VERSION ""

NS_ :

BS_:

BU_: AGSM BCM BSM CDCM DASM DCSM DCTM DIAG_TEST DTCM ECM ECM2 IPC ORC RFHM TBM TCM
BO_ 346 IMPACT_INFO: 4 ORC
 SG_ CRC_II : 31|8@0+ (1,0) [0|255] "" BCM,TBM
 SG_ IMPACT_A : 4|1@0+ (1,0) [0|1] "" Vector__XXX
 SG_ IMPACT_B : 3|1@0+ (1,0) [0|1] "" TBM
 SG_ IMPACT_C : 2|1@0+ (1,0) [0|1] "" TBM
 SG_ IMPACT_D : 1|1@0+ (1,0) [0|1] "" TBM
 SG_ IMPACT_E : 0|1@0+ (1,0) [0|1] "" TBM
 SG_ IMPACT_F : 15|1@0+ (1,0) [0|1] "" TBM
 SG_ IMPACT_G : 14|1@0+ (1,0) [0|1] "" Vector__XXX
 SG_ IMPACT_H : 13|1@0+ (1,0) [0|1] "" TBM
 SG_ IMPACT_I : 12|1@0+ (1,0) [0|1] "" TBM
 SG_ IMPACT_K : 11|1@0+ (1,0) [0|1] "" Vector__XXX
 SG_ IMPACT_L : 10|1@0+ (1,0) [0|1] "" TBM
 SG_ IMPACT_M : 9|1@0+ (1,0) [0|1] "" Vector__XXX
 SG_ IMPACT_O : 8|1@0+ (1,0) [0|1] "" Vector__XXX
 SG_ IMPACTCommand : 6|1@0+ (1,0) [0|1] "" BCM,ECM
 SG_ IMPACTConfirm : 7|1@0+ (1,0) [0|1] "" BCM,ECM
 SG_ IMPACTFailSts : 5|1@0+ (1,0) [0|1] "" BCM
 SG_ MessageCounter_II : 19|4@0+ (1,0) [0|15] "" BCM

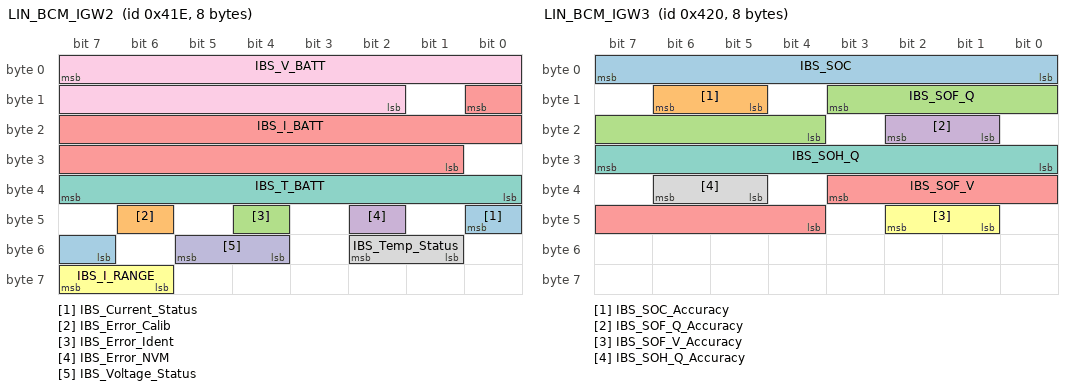
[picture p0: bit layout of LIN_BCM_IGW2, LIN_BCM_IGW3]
BO_ 1054 LIN_BCM_IGW2: 8 BCM
 SG_ IBS_Current_Status : 40|2@0+ (1,0) [0|3] "" ECM
 SG_ IBS_Error_Calib : 46|1@0+ (1,0) [0|1] "-" ECM
 SG_ IBS_Error_Ident : 44|1@0+ (1,0) [0|1] "-" ECM
 SG_ IBS_Error_NVM : 42|1@0+ (1,0) [0|1] "-" Vector__XXX
 SG_ IBS_I_BATT : 8|16@0+ (1,0) [0|65534] "" ECM
 SG_ IBS_I_RANGE : 63|2@0+ (1,0) [0|3] "" ECM
 SG_ IBS_T_BATT : 39|8@0+ (1,-40) [-40|215] "°C" ECM
 SG_ IBS_Temp_Status : 50|2@0+ (1,0) [0|3] "" BCM,ECM
 SG_ IBS_V_BATT : 7|14@0+ (0.0009765625,3) [3|18] "V" ECM
 SG_ IBS_Voltage_Status : 53|2@0+ (1,0) [0|3] "" ECM

BO_ 1056 LIN_BCM_IGW3: 8 BCM
 SG_ IBS_SOC : 7|8@0+ (1,0) [0|254] "%" ECM,IPC,ORC
 SG_ IBS_SOC_Accuracy : 14|2@0+ (1,0) [0|3] "" ECM
 SG_ IBS_SOF_Q : 11|8@0+ (0.5,0) [0|127] "Ah" ECM
 SG_ IBS_SOF_Q_Accuracy : 18|2@0+ (1,0) [0|3] "" ECM
 SG_ IBS_SOF_V : 35|8@0+ (0.0625,0) [0|15.875] "V" ECM
 SG_ IBS_SOF_V_Accuracy : 42|2@0+ (1,0) [0|3] "" ECM
 SG_ IBS_SOH_Q : 31|8@0+ (0.5,0) [0|127] "Ah" ECM
 SG_ IBS_SOH_Q_Accuracy : 38|2@0+ (1,0) [0|3] "" ECM

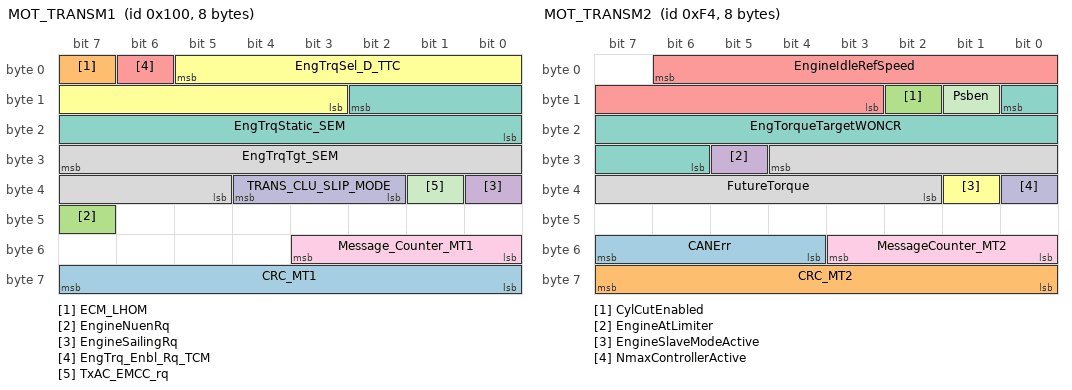
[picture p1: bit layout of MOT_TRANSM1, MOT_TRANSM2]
BO_ 256 MOT_TRANSM1: 8 ECM
 SG_ CRC_MT1 : 63|8@0+ (1,0) [0|255] "" DCTM,TCM
 SG_ ECM_LHOM : 7|1@0+ (1,0) [0|1] "-" DCTM,DTCM,TCM
 SG_ EngineNuenRq : 47|1@0+ (1,0) [0|1] "-" TCM
 SG_ EngineSailingRq : 32|1@0+ (1,0) [0|1] "-" DCTM,TCM
 SG_ EngTrq_Enbl_Rq_TCM : 6|1@0+ (1,0) [0|1] "-" ORC,TCM
 SG_ EngTrqSel_D_TTC : 5|11@0+ (1,-500) [-500|1546] "Nm" Vector__XXX
 SG_ EngTrqStatic_SEM : 10|11@0+ (1,-500) [-500|1546] "Nm" TCM
 SG_ EngTrqTgt_SEM : 31|11@0+ (1,-500) [-500|1546] "Nm" TCM
 SG_ Message_Counter_MT1 : 51|4@0+ (1,0) [0|15] "" DCTM,TCM
 SG_ TRANS_CLU_SLIP_MODE : 36|3@0+ (1,0) [0|7] "-" TCM
 SG_ TxAC_EMCC_rq : 33|1@0+ (1,0) [0|1] "-" TCM

BO_ 244 MOT_TRANSM2: 8 ECM
 SG_ CANErr : 55|4@0+ (1,0) [0|15] "-" DCTM,TCM
 SG_ CRC_MT2 : 63|8@0+ (1,0) [0|255] "" DCTM,TCM
 SG_ CylCutEnabled : 10|1@0+ (1,0) [0|1] "" DCTM
 SG_ EngineAtLimiter : 29|1@0+ (1,0) [0|1] "" DCTM
 SG_ EngineIdleRefSpeed : 6|12@0+ (1,0) [0|4094] "1/min" DCTM,TCM
 SG_ EngineSlaveModeActive : 33|1@0+ (1,0) [0|1] "" DCTM
 SG_ EngTorqueTargetWONCR : 8|11@0+ (1,-500) [-500|1546] "Nm" DCTM
 SG_ FutureTorque : 28|11@0+ (1,-500) [-500|1546] "Nm" DCTM
 SG_ MessageCounter_MT2 : 51|4@0+ (1,0) [0|15] "" DCTM,TCM
 SG_ NmaxControllerActive : 32|1@0+ (1,0) [0|1] "" DCTM
 SG_ Psben : 9|1@0+ (1,0) [0|1] "-" DCTM,TCM

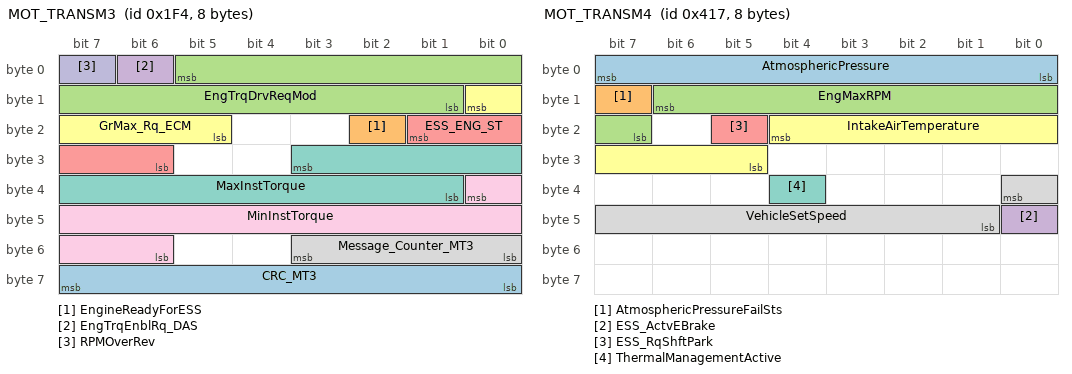
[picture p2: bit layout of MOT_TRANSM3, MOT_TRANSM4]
BO_ 500 MOT_TRANSM3: 8 ECM
 SG_ CRC_MT3 : 63|8@0+ (1,0) [0|255] "" BCM,BSM,DASM,DCSM,DCTM,TCM
 SG_ EngineReadyForESS : 18|1@0+ (1,0) [0|1] "-" BSM,DCTM,TCM
 SG_ EngTrqDrvReqMod : 5|13@0+ (0.25,-500) [-500|1547.5] "Nm" DCTM,TCM
 SG_ EngTrqEnblRq_DAS : 6|1@0+ (1,0) [0|1] "-" DASM
 SG_ ESS_ENG_ST : 17|4@0+ (1,0) [0|15] "-" AGSM,BCM,BSM,DASM,DCSM,DCTM,DTCM,TCM
 SG_ GrMax_Rq_ECM : 8|4@0+ (1,0) [0|15] "-" DCTM,TCM
 SG_ MaxInstTorque : 27|11@0+ (1,-500) [-500|1546] "Nm" DCTM
 SG_ Message_Counter_MT3 : 51|4@0+ (1,0) [0|15] "" BCM,BSM,DASM,DCSM,DCTM,TCM
 SG_ MinInstTorque : 32|11@0+ (1,-500) [-500|1546] "Nm" DCTM
 SG_ RPMOverRev : 7|1@0+ (1,0) [0|1] "-" DASM

BO_ 1047 MOT_TRANSM4: 8 ECM
 SG_ AtmosphericPressure : 7|8@0+ (3.6,300) [300|1214.4] "mbar" DCTM,ORC,RFHM,TCM
 SG_ AtmosphericPressureFailSts : 15|1@0+ (1,0) [0|1] "-" DCTM,RFHM,TCM
 SG_ EngMaxRPM : 14|8@0+ (50,0) [0|10000] "-" DCTM,TCM
 SG_ ESS_ActvEBrake : 40|1@0+ (1,0) [0|1] "-" BSM
 SG_ ESS_RqShftPark : 21|1@0+ (1,0) [0|1] "" DCTM,TCM
 SG_ IntakeAirTemperature : 20|8@0+ (1,-40) [-40|214] "C" Vector__XXX
 SG_ ThermalManagementActive : 36|1@0+ (1,0) [0|1] "-" DCTM,TCM
 SG_ VehicleSetSpeed : 32|8@0+ (1,0) [0|250] "km/h(mph)" DCTM,TCM

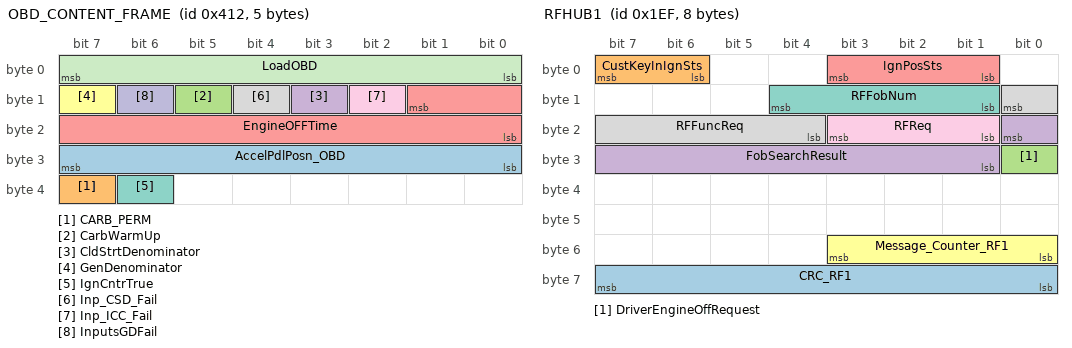
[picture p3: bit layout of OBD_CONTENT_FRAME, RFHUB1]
BO_ 1042 OBD_CONTENT_FRAME: 5 ECM
 SG_ AccelPdlPosn_OBD : 31|8@0+ (0.3922,0) [0|100] "%" DCTM,TCM
 SG_ CARB_PERM : 39|1@0+ (1,0) [0|1] "-" DCTM,TCM
 SG_ CarbWarmUp : 13|1@0+ (1,0) [0|1] "-" DCTM,TCM
 SG_ CldStrtDenominator : 11|1@0+ (1,0) [0|1] "-" DCTM,TCM
 SG_ EngineOFFTime : 9|10@0+ (1,0) [0|1022] "min" DCTM,DTCM,TCM
 SG_ GenDenominator : 15|1@0+ (1,0) [0|1] "-" DCTM,TCM
 SG_ IgnCntrTrue : 38|1@0+ (1,0) [0|1] "-" DCTM,TCM
 SG_ Inp_CSD_Fail : 12|1@0+ (1,0) [0|1] "-" DCTM,TCM
 SG_ Inp_ICC_Fail : 10|1@0+ (1,0) [0|1] "-" DCTM,TCM
 SG_ InputsGDFail : 14|1@0+ (1,0) [0|1] "-" DCTM,TCM
 SG_ LoadOBD : 7|8@0+ (0.3922,0) [0|100] "%" DCTM,TCM

BO_ 495 RFHUB1: 8 RFHM
 SG_ CRC_RF1 : 63|8@0+ (1,0) [0|255] "" BCM
 SG_ CustKeyInIgnSts : 7|2@0+ (1,0) [0|2] "" BCM
 SG_ DriverEngineOffRequest : 24|1@0+ (1,0) [0|1] "" BCM
 SG_ FobSearchResult : 16|8@0+ (1,0) [0|255] "" BCM
 SG_ IgnPosSts : 3|3@0+ (1,0) [0|6] "" BCM
 SG_ Message_Counter_RF1 : 51|4@0+ (1,0) [0|15] "" BCM
 SG_ RFFobNum : 12|4@0+ (1,0) [0|14] "" BCM
 SG_ RFFuncReq : 8|5@0+ (1,0) [0|30] "" BCM,RFHM
 SG_ RFReq : 19|3@0+ (1,0) [0|6] "" BCM

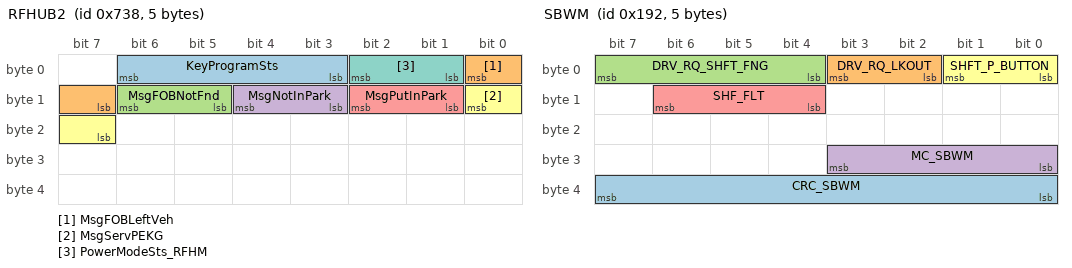
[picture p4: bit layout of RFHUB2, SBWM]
BO_ 1848 RFHUB2: 5 RFHM
 SG_ KeyProgramSts : 6|4@0+ (1,0) [0|15] "" IPC
 SG_ MsgFOBLeftVeh : 0|2@0+ (1,0) [0|2] "" IPC
 SG_ MsgFOBNotFnd : 14|2@0+ (1,0) [0|2] "" IPC
 SG_ MsgNotInPark : 12|2@0+ (1,0) [0|3] "" IPC
 SG_ MsgPutInPark : 10|2@0+ (1,0) [0|3] "" IPC
 SG_ MsgServPEKG : 8|2@0+ (1,0) [0|3] "" IPC
 SG_ PowerModeSts_RFHM : 2|2@0+ (1,0) [0|3] "" BCM

BO_ 402 SBWM: 5 AGSM
 SG_ CRC_SBWM : 39|8@0+ (1,0) [0|255] "" TCM
 SG_ DRV_RQ_LKOUT : 3|2@0+ (1,0) [0|3] "-" TCM
 SG_ DRV_RQ_SHFT_FNG : 7|4@0+ (1,0) [0|15] "" TCM
 SG_ MC_SBWM : 27|4@0+ (1,0) [0|15] "" TCM
 SG_ SHF_FLT : 14|3@0+ (1,0) [0|7] "-" TCM
 SG_ SHFT_P_BUTTON : 1|2@0+ (1,0) [0|3] "-" TCM

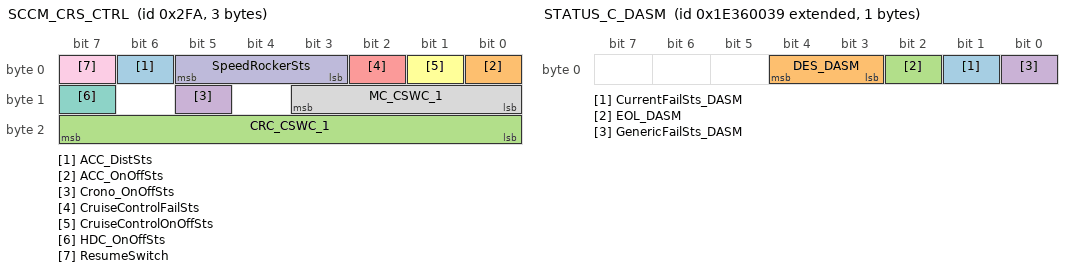
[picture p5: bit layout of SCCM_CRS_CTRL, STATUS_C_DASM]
BO_ 762 SCCM_CRS_CTRL: 3 BCM
 SG_ ACC_DistSts : 6|1@0+ (1,0) [0|1] "" DASM,ORC
 SG_ ACC_OnOffSts : 0|1@0+ (1,0) [0|1] "" DASM,ORC
 SG_ CRC_CSWC_1 : 23|8@0+ (1,0) [0|255] "" DASM,ECM
 SG_ Crono_OnOffSts : 13|1@0+ (1,0) [0|1] "" IPC
 SG_ CruiseControlFailSts : 2|1@0+ (1,0) [0|1] "" ECM,ORC
 SG_ CruiseControlOnOffSts : 1|1@0+ (1,0) [0|1] "" DASM,ECM,ORC
 SG_ HDC_OnOffSts : 15|1@0+ (1,0) [0|1] "" ECM
 SG_ MC_CSWC_1 : 11|4@0+ (1,0) [0|15] "" DASM,ECM
 SG_ ResumeSwitch : 7|1@0+ (1,0) [0|1] "" BSM,DASM,ECM,ORC
 SG_ SpeedRockerSts : 5|3@0+ (1,0) [0|7] "" BSM,DASM,ECM

BO_ 2654339129 STATUS_C_DASM: 1 DASM
 SG_ CurrentFailSts_DASM : 1|1@0+ (1,0) [0|1] "-" BCM
 SG_ DES_DASM : 4|2@0+ (1,0) [0|2] "-" Vector__XXX
 SG_ EOL_DASM : 2|1@0+ (1,0) [0|1] "-" BCM
 SG_ GenericFailSts_DASM : 0|1@0+ (1,0) [0|1] "-" BCM

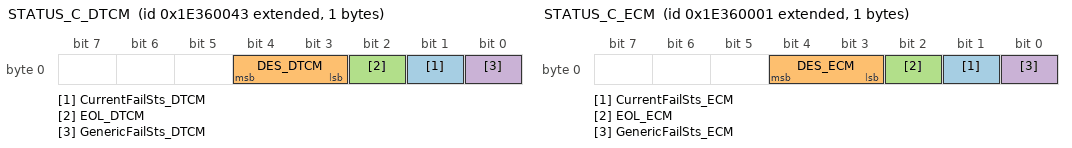
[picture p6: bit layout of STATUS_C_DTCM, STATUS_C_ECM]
BO_ 2654339139 STATUS_C_DTCM: 1 DTCM
 SG_ CurrentFailSts_DTCM : 1|1@0+ (1,0) [0|1] "-" BCM
 SG_ DES_DTCM : 4|2@0+ (1,0) [0|2] "-" Vector__XXX
 SG_ EOL_DTCM : 2|1@0+ (1,0) [0|1] "-" BCM
 SG_ GenericFailSts_DTCM : 0|1@0+ (1,0) [0|1] "-" BCM

BO_ 2654339073 STATUS_C_ECM: 1 ECM
 SG_ CurrentFailSts_ECM : 1|1@0+ (1,0) [0|1] "-" BCM
 SG_ DES_ECM : 4|2@0+ (1,0) [0|2] "-" Vector__XXX
 SG_ EOL_ECM : 2|1@0+ (1,0) [0|1] "-" BCM
 SG_ GenericFailSts_ECM : 0|1@0+ (1,0) [0|1] "-" BCM

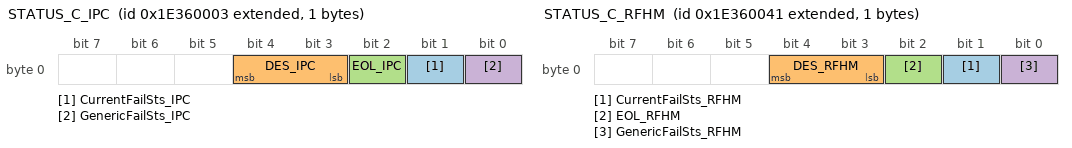
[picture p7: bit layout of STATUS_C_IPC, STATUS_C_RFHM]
BO_ 2654339075 STATUS_C_IPC: 1 IPC
 SG_ CurrentFailSts_IPC : 1|1@0+ (1,0) [0|1] "-" BCM
 SG_ DES_IPC : 4|2@0+ (1,0) [0|2] "-" Vector__XXX
 SG_ EOL_IPC : 2|1@0+ (1,0) [0|1] "-" BCM
 SG_ GenericFailSts_IPC : 0|1@0+ (1,0) [0|1] "-" BCM

BO_ 2654339137 STATUS_C_RFHM: 1 RFHM
 SG_ CurrentFailSts_RFHM : 1|1@0+ (1,0) [0|1] "-" BCM
 SG_ DES_RFHM : 4|2@0+ (1,0) [0|2] "-" Vector__XXX
 SG_ EOL_RFHM : 2|1@0+ (1,0) [0|1] "-" BCM
 SG_ GenericFailSts_RFHM : 0|1@0+ (1,0) [0|1] "-" BCM

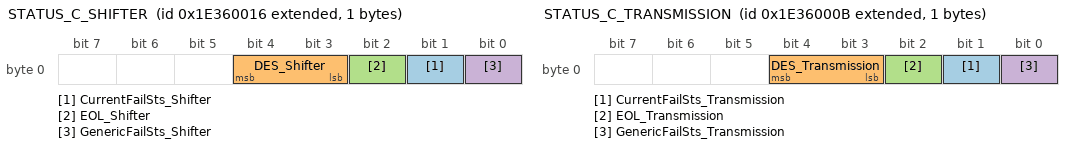
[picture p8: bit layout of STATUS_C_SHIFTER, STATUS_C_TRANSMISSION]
BO_ 2654339094 STATUS_C_SHIFTER: 1 AGSM
 SG_ CurrentFailSts_Shifter : 1|1@0+ (1,0) [0|1] "-" BCM
 SG_ DES_Shifter : 4|2@0+ (1,0) [0|2] "-" Vector__XXX
 SG_ EOL_Shifter : 2|1@0+ (1,0) [0|1] "-" BCM
 SG_ GenericFailSts_Shifter : 0|1@0+ (1,0) [0|1] "-" BCM

BO_ 2654339083 STATUS_C_TRANSMISSION: 1 TCM
 SG_ CurrentFailSts_Transmission : 1|1@0+ (1,0) [0|1] "-" BCM
 SG_ DES_Transmission : 4|2@0+ (1,0) [0|2] "-" Vector__XXX
 SG_ EOL_Transmission : 2|1@0+ (1,0) [0|1] "-" BCM
 SG_ GenericFailSts_Transmission : 0|1@0+ (1,0) [0|1] "-" BCM

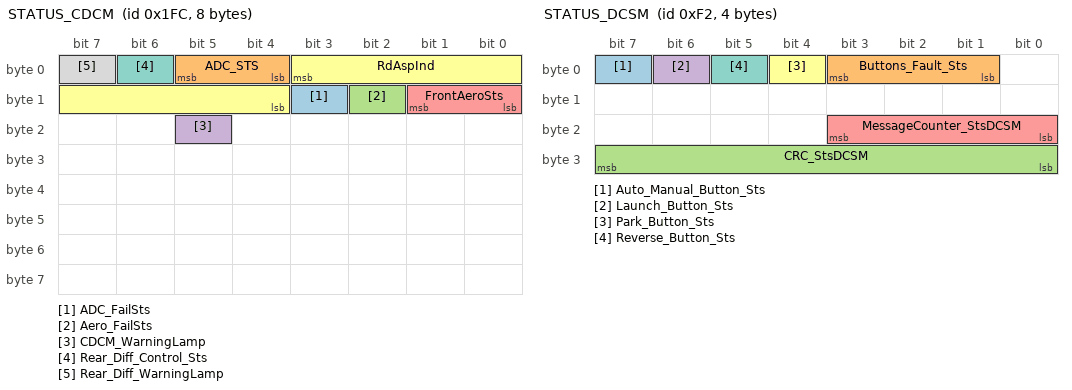
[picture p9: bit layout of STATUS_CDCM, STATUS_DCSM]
BO_ 508 STATUS_CDCM: 8 CDCM
 SG_ ADC_FailSts : 11|1@0+ (1,0) [0|1] "" IPC
 SG_ ADC_STS : 5|2@0+ (1,0) [0|3] "-" IPC
 SG_ Aero_FailSts : 10|1@0+ (1,0) [0|1] "" IPC
 SG_ CDCM_WarningLamp : 21|1@0+ (1,0) [0|1] "" IPC
 SG_ FrontAeroSts : 9|2@0+ (1,0) [0|3] "" Vector__XXX
 SG_ RdAspInd : 3|8@0+ (1,0) [0|255] "-" Vector__XXX
 SG_ Rear_Diff_Control_Sts : 6|1@0+ (1,0) [0|1] "" Vector__XXX
 SG_ Rear_Diff_WarningLamp : 7|1@0+ (1,0) [0|1] "" IPC

BO_ 1852 STATUS_DASM: 8 DASM
 SG_ ACC_RadarBlinded : 58|1@0+ (1,0) [0|1] "" BSM,IPC
 SG_ ACC_SetSpeedKPH : 31|8@0+ (1,0) [0|255] "kph" IPC
 SG_ ACC_SetSpeedMPH : 39|8@0+ (1,0) [0|255] "mph" IPC
 SG_ ACCFailSts : 47|1@0+ (1,0) [0|1] "" BSM,IPC
 SG_ ACCSystemSts : 62|3@0+ (1,0) [0|7] "" BSM,ECM
 SG_ CameraBlinded : 22|1@0+ (1,0) [0|1] "" IPC
 SG_ CameraFailure : 23|1@0+ (1,0) [0|1] "" IPC
 SG_ CHIME_REP_RATESts : 5|4@0+ (1,0) [0|15] "" IPC
 SG_ CHIME_TYPSts : 7|2@0+ (1,0) [0|3] "-" IPC,ORC
 SG_ DASMFailSts : 9|1@0+ (1,0) [0|1] "" BSM,IPC
 SG_ DASMTemporaryFailSts : 8|1@0+ (1,0) [0|1] "" BSM,IPC,ORC
 SG_ FCWSts : 15|2@0+ (1,0) [0|3] "-" IPC
 SG_ FCWSystemSts : 12|2@0+ (1,0) [0|3] "-" IPC,ORC
 SG_ HMICode_ACC : 45|8@0+ (1,0) [0|255] "" IPC
 SG_ HMICode_ACC_Ind : 63|1@0+ (1,0) [0|1] "" IPC
 SG_ HMICode_FCW : 21|6@0+ (1,0) [0|63] "" IPC
 SG_ HMIDisplay_ACC : 53|6@0+ (1,0) [0|63] "" IPC
 SG_ LF_CHIME_RQSts : 0|1@0+ (1,0) [0|1] "-" IPC
 SG_ NCCFailSts : 46|1@0+ (1,0) [0|1] "" IPC
 SG_ RadarBlinded : 10|1@0+ (1,0) [0|1] "" BSM,IPC
 SG_ RF_CHIME_RQSts : 1|1@0+ (1,0) [0|1] "" IPC

BO_ 242 STATUS_DCSM: 4 DCSM
 SG_ Auto_Manual_Button_Sts : 7|1@0+ (1,0) [0|1] "" DCTM
 SG_ Buttons_Fault_Sts : 3|3@0+ (1,0) [0|7] "" DCTM
 SG_ CRC_StsDCSM : 31|8@0+ (1,0) [0|255] "" DCTM
 SG_ Launch_Button_Sts : 6|1@0+ (1,0) [0|1] "" DCTM
 SG_ MessageCounter_StsDCSM : 19|4@0+ (1,0) [0|15] "" DCTM
 SG_ Park_Button_Sts : 4|1@0+ (1,0) [0|1] "" DCTM
 SG_ Reverse_Button_Sts : 5|1@0+ (1,0) [0|1] "" DCTM

BO_ 1454 STATUS_ECM: 8 ECM
 SG_ ChkFuelCap : 31|1@0+ (1,0) [0|1] "-" IPC
 SG_ ColdStartLampIndication : 17|2@0+ (1,0) [0|3] "-" BCM,IPC
 SG_ CompressorSts : 33|2@0+ (1,0) [0|3] "-" BCM,TCM
 SG_ DPFSts : 34|1@0+ (1,0) [0|1] "-" BCM,IPC
 SG_ EMSFailSts : 36|2@0+ (1,0) [0|3] "-" BCM,IPC,ORC
 SG_ EngineOperatingMode : 44|3@0+ (1,0) [0|7] "-" TCM
 SG_ EngineWaterTempWarningLightSts : 37|1@0+ (1,0) [0|1] "-" BCM,IPC
 SG_ ETCFailSts : 19|2@0+ (1,0) [0|3] "-" BCM,IPC,ORC
 SG_ ExhaustTemperature : 41|8@0+ (4,0) [0|1020] "°C" TCM
 SG_ FuelFilterHeaterReq : 46|1@0+ (1,0) [0|1] "-" BCM
 SG_ FuelWaterPresentFailSts : 38|1@0+ (1,0) [0|1] "-" IPC
 SG_ FuelWaterPresentSts : 39|1@0+ (1,0) [0|1] "-" IPC
 SG_ GlowPlugFailSts : 24|1@0+ (1,0) [0|1] "-" IPC
 SG_ GlowPlugLampSts : 25|1@0+ (1,0) [0|1] "-" BCM,IPC
 SG_ OilLifeSts : 29|2@0+ (1,0) [0|3] "-" BCM,IPC
 SG_ OilPressureFailSts : 30|1@0+ (1,0) [0|1] "-" IPC
 SG_ OilPressureSts : 26|1@0+ (1,0) [0|1] "-" BCM,IPC

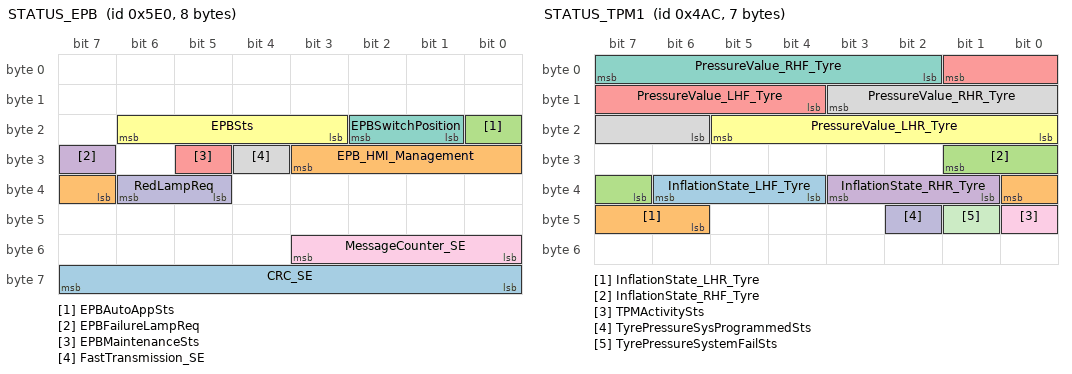
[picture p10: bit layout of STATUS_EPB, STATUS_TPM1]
BO_ 1504 STATUS_EPB: 8 BSM
 SG_ CRC_SE : 63|8@0+ (1,0) [0|255] "" BCM,DASM,DCTM,DTCM,ECM,TCM
 SG_ EPB_HMI_Management : 27|5@0+ (1,0) [0|31] "" IPC
 SG_ EPBAutoAppSts : 16|1@0+ (1,0) [0|1] "" IPC
 SG_ EPBFailureLampReq : 31|1@0+ (1,0) [0|1] "" IPC,ORC
 SG_ EPBMaintenanceSts : 29|1@0+ (1,0) [0|1] "" IPC
 SG_ EPBSts : 22|4@0+ (1,0) [0|14] "-" BCM,DASM,DCTM,DTCM,ECM,ORC,TCM
 SG_ EPBSwitchPosition : 18|2@0+ (1,0) [0|3] "" Vector__XXX
 SG_ FastTransmission_SE : 28|1@0+ (1,0) [0|1] "" Vector__XXX
 SG_ MessageCounter_SE : 51|4@0+ (1,0) [0|15] "" BCM,DASM,DCTM,DTCM,ECM,TCM
 SG_ RedLampReq : 38|2@0+ (1,0) [0|3] "" IPC,ORC

BO_ 1196 STATUS_TPM1: 7 RFHM
 SG_ InflationState_LHF_Tyre : 38|3@0+ (1,0) [0|4] "-" BCM,CDCM,IPC,ORC
 SG_ InflationState_LHR_Tyre : 32|3@0+ (1,0) [0|4] "-" BCM,CDCM,IPC,ORC
 SG_ InflationState_RHF_Tyre : 25|3@0+ (1,0) [0|4] "-" BCM,CDCM,IPC,ORC
 SG_ InflationState_RHR_Tyre : 35|3@0+ (1,0) [0|4] "-" BCM,CDCM,IPC,ORC
 SG_ PressureValue_LHF_Tyre : 1|6@0+ (0.1,0.7) [0.7|7] "bar" BCM,CDCM,IPC,ORC
 SG_ PressureValue_LHR_Tyre : 21|6@0+ (0.1,0.7) [0.7|7] "bar" BCM,CDCM,IPC,ORC
 SG_ PressureValue_RHF_Tyre : 7|6@0+ (0.1,0.7) [0.7|7] "bar" BCM,CDCM,IPC,ORC
 SG_ PressureValue_RHR_Tyre : 11|6@0+ (0.1,0.7) [0.7|7] "bar" BCM,CDCM,IPC,ORC
 SG_ TPMActivitySts : 40|1@0+ (1,0) [0|1] "-" CDCM,IPC,ORC
 SG_ TyrePressureSysProgrammedSts : 42|1@0+ (1,0) [0|1] "-" CDCM,IPC
 SG_ TyrePressureSystemFailSts : 41|1@0+ (1,0) [0|1] "-" BCM,CDCM,IPC,ORC

BO_ 1992 STATUS_TTM: 4 BCM
 SG_ TrailerConnectionSts : 8|2@0+ (1,0) [0|3] "" BSM,DASM
 SG_ TrailerGenericFailSts : 9|1@0+ (1,0) [0|1] "" BSM,DASM

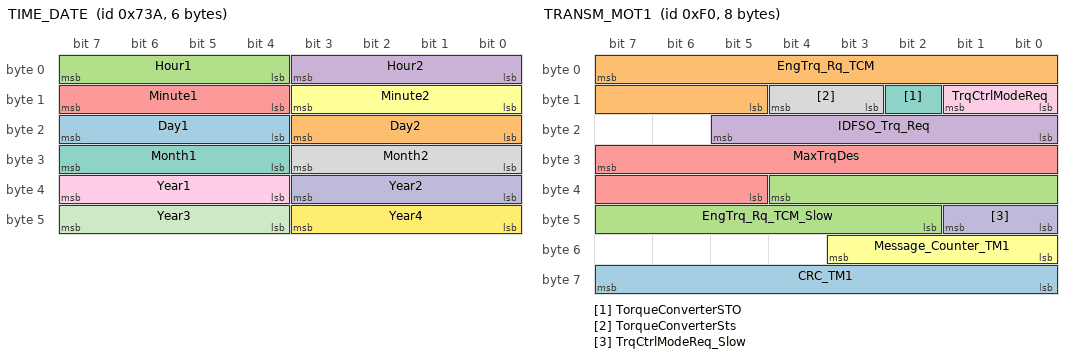
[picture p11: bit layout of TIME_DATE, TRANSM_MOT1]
BO_ 1850 TIME_DATE: 6 IPC
 SG_ Day1 : 23|4@0+ (1,0) [0|9] "-" BCM,ECM,RFHM
 SG_ Day2 : 19|4@0+ (1,0) [0|9] "-" BCM,ECM,RFHM
 SG_ Hour1 : 7|4@0+ (1,0) [0|9] "-" BCM,ECM,RFHM
 SG_ Hour2 : 3|4@0+ (1,0) [0|9] "-" BCM,ECM,RFHM
 SG_ Minute1 : 15|4@0+ (1,0) [0|9] "-" BCM,ECM,RFHM
 SG_ Minute2 : 11|4@0+ (1,0) [0|9] "-" BCM,ECM,RFHM
 SG_ Month1 : 31|4@0+ (1,0) [0|9] "-" BCM,ECM,RFHM
 SG_ Month2 : 27|4@0+ (1,0) [0|9] "-" BCM,ECM,RFHM
 SG_ Year1 : 39|4@0+ (1,0) [0|9] "-" BCM,ECM,RFHM
 SG_ Year2 : 35|4@0+ (1,0) [0|9] "-" BCM,ECM,RFHM
 SG_ Year3 : 47|4@0+ (1,0) [0|9] "-" BCM,ECM,RFHM
 SG_ Year4 : 43|4@0+ (1,0) [0|9] "-" BCM,ECM,RFHM

BO_ 240 TRANSM_MOT1: 8 TCM
 SG_ CRC_TM1 : 63|8@0+ (1,0) [0|255] "-" ECM
 SG_ EngTrq_Rq_TCM : 7|11@0+ (1,-500) [-500|1546] "Nm" ECM
 SG_ EngTrq_Rq_TCM_Slow : 36|11@0+ (1,-500) [-500|1546] "Nm" ECM
 SG_ IDFSO_Trq_Req : 21|6@0+ (3,-40) [-40|149] "°C" ECM
 SG_ MaxTrqDes : 31|11@0+ (1,-500) [-500|1546] "Nm" ECM
 SG_ Message_Counter_TM1 : 51|4@0+ (1,0) [0|15] "-" ECM
 SG_ TorqueConverterSTO : 10|1@0+ (1,0) [0|1] "-" ECM
 SG_ TorqueConverterSts : 12|2@0+ (1,0) [0|3] "-" ECM
 SG_ TrqCtrlModeReq : 9|2@0+ (1,0) [0|1] "-" ECM
 SG_ TrqCtrlModeReq_Slow : 41|2@0+ (1,0) [0|2] "-" ECM

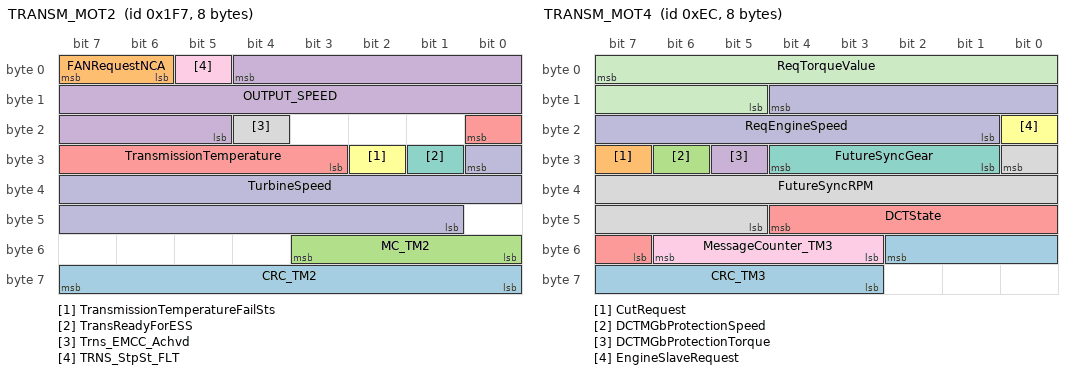
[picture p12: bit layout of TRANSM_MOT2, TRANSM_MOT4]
BO_ 503 TRANSM_MOT2: 8 DCTM
 SG_ CRC_TM2 : 63|8@0+ (1,0) [0|255] "-" ECM
 SG_ FANRequestNCA : 7|2@0+ (1,0) [0|3] "-" ECM
 SG_ MC_TM2 : 51|4@0+ (1,0) [0|15] "-" ECM
 SG_ OUTPUT_SPEED : 4|16@0+ (1,0) [0|65534] "RPM" DTCM,ECM
 SG_ TransmissionTemperature : 16|6@0+ (3,-40) [-40|149] "°C" ECM
 SG_ TransmissionTemperatureFailSts : 26|1@0+ (1,0) [0|1] "-" ECM
 SG_ TransReadyForESS : 25|1@0+ (1,0) [0|1] "-" ECM
 SG_ Trns_EMCC_Achvd : 20|1@0+ (1,0) [0|1] "-" ECM
 SG_ TRNS_StpSt_FLT : 5|1@0+ (1,0) [0|1] "-" ECM
 SG_ TurbineSpeed : 24|16@0+ (1,0) [0|65534] "RPM" ECM

BO_ 236 TRANSM_MOT4: 8 DCTM
 SG_ CRC_TM3 : 50|8@0+ (1,0) [0|225] "" ECM
 SG_ CutRequest : 31|1@0+ (1,0) [0|1] "" ECM
 SG_ DCTMGbProtectionSpeed : 30|1@0+ (1,0) [0|1] "" ECM
 SG_ DCTMGbProtectionTorque : 29|1@0+ (1,0) [0|1] "" ECM
 SG_ DCTState : 44|6@0+ (1,0) [0|63] "" ECM
 SG_ EngineSlaveRequest : 16|1@0+ (1,0) [0|1] "" ECM
 SG_ FutureSyncGear : 28|4@0+ (1,-500) [-500|1546] "" ECM
 SG_ FutureSyncRPM : 24|12@0+ (5,0) [0|2470] "rev/min" ECM
 SG_ MessageCounter_TM3 : 54|4@0+ (1,0) [0|15] "" ECM
 SG_ ReqEngineSpeed : 12|12@0+ (5,0) [0|2470] "rev/min" ECM
 SG_ ReqTorqueValue : 7|11@0+ (1,-500) [-500|1546] "Nm" ECM

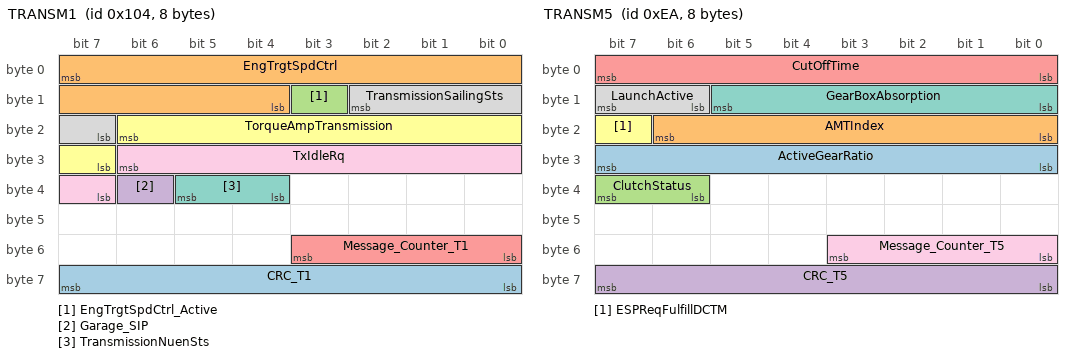
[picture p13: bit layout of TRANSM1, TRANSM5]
BO_ 260 TRANSM1: 8 DCTM
 SG_ CRC_T1 : 63|8@0+ (1,0) [0|255] "-" CDCM,DASM,DTCM,ECM
 SG_ EngTrgtSpdCtrl : 7|12@0+ (2.05,0) [0|8392.7] "rpm" ECM
 SG_ EngTrgtSpdCtrl_Active : 11|1@0+ (1,0) [0|1] "-" ECM
 SG_ Garage_SIP : 38|1@0+ (1,0) [0|1] "-" ECM
 SG_ Message_Counter_T1 : 51|4@0+ (1,0) [0|15] "" CDCM,DASM,DTCM,ECM
 SG_ TorqueAmpTransmission : 22|8@0+ (0.125,0) [0|23.125] "-" CDCM,DASM,ECM
 SG_ TransmissionNuenSts : 37|2@0+ (1,0) [0|3] "-" DTCM,ECM
 SG_ TransmissionSailingSts : 10|4@0+ (1,0) [0|15] "-" DTCM,ECM
 SG_ TxIdleRq : 30|8@0+ (4,500) [500|1516] "rpm" ECM

BO_ 1448 TRANSM2: 8 DCTM
 SG_ BuzzerReqSts_T2 : 11|2@0+ (1,0) [0|3] "" IPC
 SG_ CrankEnable : 7|1@0+ (1,0) [0|1] "-" ECM
 SG_ CRC_T2 : 63|8@0+ (1,0) [0|255] "count" AGSM,BCM,BSM,CDCM,DCSM,DTCM,ECM,RFHM
 SG_ DriveModeSts : 38|4@0+ (1,0) [0|7] "-" ECM
 SG_ GearEngaged : 26|4@0+ (1,0) [0|15] "-" BSM,CDCM,DASM,DTCM,ECM,IPC
 SG_ GearIndicationSts : 9|1@0+ (1,0) [0|1] "-" AGSM,DCSM,IPC
 SG_ LeverPosition : 8|4@0+ (1,0) [0|15] "-" BCM,DTCM
 SG_ LimpHomeSts : 6|1@0+ (1,0) [0|1] "-" DASM,ECM,ORC
 SG_ Message_Counter_T2 : 51|4@0+ (1,0) [0|15] "" AGSM,BCM,BSM,CDCM,DCSM,DTCM,ECM,RFHM
 SG_ MIReq : 5|1@0+ (1,0) [0|1] "-" ECM
 SG_ OilTemperatureSts : 20|1@0+ (1,0) [0|1] "-" IPC
 SG_ ParkingFailSts : 3|1@0+ (1,0) [0|1] "-" Vector__XXX
 SG_ ParkingSts : 4|1@0+ (1,0) [0|1] "-" Vector__XXX
 SG_ ShiftInProgress : 19|1@0+ (1,0) [0|1] "-" BSM,CDCM,DASM,ECM
 SG_ ShiftLeverPosition : 17|4@0+ (1,0) [0|15] "-" AGSM,BCM,BSM,CDCM,DCSM,ECM,IPC,ORC,RFHM
 SG_ ShiftModeSts : 28|1@0+ (1,0) [0|1] "-" BCM,DASM,ECM,IPC
 SG_ TargetGear : 34|4@0+ (1,0) [0|15] "-" BSM,CDCM,DASM,DTCM,ECM,IPC
 SG_ TemporaryManualSts : 42|1@0+ (1,0) [0|1] "-" IPC
 SG_ TransmissionFailSts : 12|1@0+ (1,0) [0|1] "" BCM,IPC,ORC
 SG_ TransmissionWarnings : 2|6@0+ (1,0) [0|10] "-" AGSM,IPC
 SG_ TxDisengaged : 46|1@0+ (1,0) [0|1] "-" ECM
 SG_ UpDownShiftSel : 27|1@0+ (1,0) [0|1] "-" Vector__XXX

BO_ 234 TRANSM5: 8 DCTM
 SG_ ActiveGearRatio : 31|8@0+ (0.125,0) [0|31.75] "" ECM
 SG_ AMTIndex : 22|7@0+ (1,0) [0|126] "%" ECM
 SG_ ClutchStatus : 39|2@0+ (1,0) [0|3] "" ECM
 SG_ CRC_T5 : 63|8@0+ (1,0) [0|255] "count" ECM
 SG_ CutOffTime : 7|8@0+ (5,0) [0|1270] "ms" ECM
 SG_ ESPReqFulfillDCTM : 23|1@0+ (1,0) [0|1] "" ECM
 SG_ GearBoxAbsorption : 13|6@0+ (1,0) [0|62] "" ECM
 SG_ LaunchActive : 15|2@0+ (1,0) [0|3] "" ECM,IPC
 SG_ Message_Counter_T5 : 51|4@0+ (1,0) [0|15] "" ECM

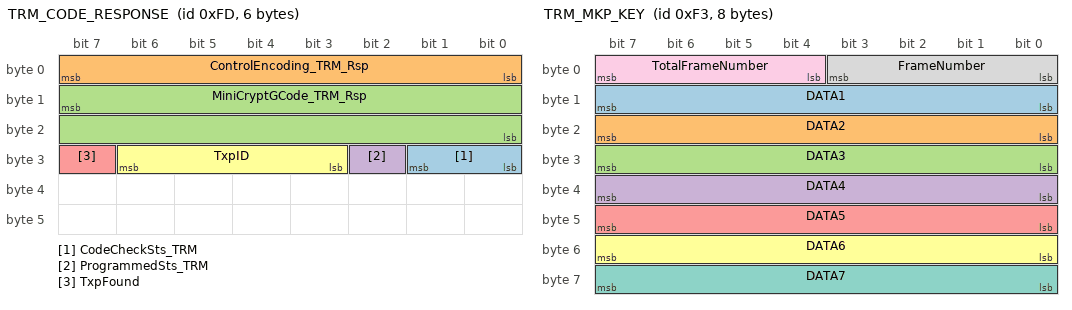
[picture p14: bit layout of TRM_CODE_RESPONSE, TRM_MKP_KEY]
BO_ 253 TRM_CODE_RESPONSE: 6 RFHM
 SG_ CodeCheckSts_TRM : 25|2@0+ (1,0) [0|3] "-" BCM
 SG_ ControlEncoding_TRM_Rsp : 7|8@0+ (1,0) [0|255] "-" BCM
 SG_ MiniCryptGCode_TRM_Rsp : 15|16@0+ (1,0) [0|65535] "" BCM
 SG_ ProgrammedSts_TRM : 26|1@0+ (1,0) [0|1] "-" BCM
 SG_ TxpFound : 31|1@0+ (1,0) [0|1] "-" BCM
 SG_ TxpID : 30|4@0+ (1,0) [0|15] "-" BCM

BO_ 243 TRM_MKP_KEY: 8 RFHM
 SG_ DATA1 : 15|8@0+ (1,0) [0|255] "" BCM
 SG_ DATA2 : 23|8@0+ (1,0) [0|255] "" BCM
 SG_ DATA3 : 31|8@0+ (1,0) [0|255] "" BCM
 SG_ DATA4 : 39|8@0+ (1,0) [0|255] "" BCM
 SG_ DATA5 : 47|8@0+ (1,0) [0|255] "" BCM
 SG_ DATA6 : 55|8@0+ (1,0) [0|255] "" BCM
 SG_ DATA7 : 63|8@0+ (1,0) [0|255] "" BCM
 SG_ FrameNumber : 3|4@0+ (1,0) [0|15] "-" BCM
 SG_ TotalFrameNumber : 7|4@0+ (1,0) [0|15] "-" BCM

BO_ 1046 VIN: 8 BCM
 SG_ VIN_DATA : 15|56@0+ (1,0) [0|7.20575940379279E+16] "" AGSM,DASM,DCSM,DCTM,DTCM,ECM,IPC,ORC,RFHM,TCM
 SG_ VIN_MSG : 1|2@0+ (1,0) [0|3] "" AGSM,DASM,DCSM,DCTM,DTCM,ECM,IPC,ORC,RFHM,TCM

BO_ 2654208000 WAKE_C_BCM: 8 BCM
 SG_ MainWakeSts_BCM : 7|1@0+ (1,0) [0|1] "-" BSM,IPC,RFHM,TCM
 SG_ Node0 : 40|1@0+ (1,0) [0|1] "-" BSM,IPC,RFHM,TCM
 SG_ Node1 : 41|1@0+ (1,0) [0|1] "-" BSM,IPC,RFHM,TCM
 SG_ Node10 : 34|1@0+ (1,0) [0|1] "-" BSM,IPC,RFHM,TCM
 SG_ Node11 : 35|1@0+ (1,0) [0|1] "-" BSM,IPC,RFHM,TCM
 SG_ Node12 : 36|1@0+ (1,0) [0|1] "-" BSM,IPC,RFHM,TCM
 SG_ Node13 : 37|1@0+ (1,0) [0|1] "-" BSM,IPC,RFHM,TCM
 SG_ Node14 : 38|1@0+ (1,0) [0|1] "-" BSM,IPC,RFHM,TCM
 SG_ Node15 : 39|1@0+ (1,0) [0|1] "-" BSM,IPC,RFHM,TCM
 SG_ Node16 : 24|1@0+ (1,0) [0|1] "-" BSM,IPC,RFHM,TCM
 SG_ Node17 : 25|1@0+ (1,0) [0|1] "-" BSM,IPC,RFHM,TCM
 SG_ Node18 : 26|1@0+ (1,0) [0|1] "-" BSM,IPC,RFHM,TCM
 SG_ Node19 : 27|1@0+ (1,0) [0|1] "-" BSM,IPC,RFHM,TCM
 SG_ Node2 : 42|1@0+ (1,0) [0|1] "-" BSM,IPC,RFHM,TCM
 SG_ Node20 : 28|1@0+ (1,0) [0|1] "-" BSM,IPC,RFHM,TCM
 SG_ Node21 : 29|1@0+ (1,0) [0|1] "-" BSM,IPC,RFHM,TCM
 SG_ Node22 : 30|1@0+ (1,0) [0|1] "-" BSM,IPC,RFHM,TCM
 SG_ Node23 : 31|1@0+ (1,0) [0|1] "-" BSM,IPC,RFHM,TCM
 SG_ Node24 : 16|1@0+ (1,0) [0|1] "-" BSM,IPC,RFHM,TCM
 SG_ Node25 : 17|1@0+ (1,0) [0|1] "-" BSM,IPC,RFHM,TCM
 SG_ Node26 : 18|1@0+ (1,0) [0|1] "-" BSM,IPC,RFHM,TCM
 SG_ Node27 : 19|1@0+ (1,0) [0|1] "-" BSM,IPC,RFHM,TCM
 SG_ Node28 : 20|1@0+ (1,0) [0|1] "-" BSM,IPC,RFHM,TCM
 SG_ Node29 : 21|1@0+ (1,0) [0|1] "-" BSM,IPC,RFHM,TCM
 SG_ Node3 : 43|1@0+ (1,0) [0|1] "-" BSM,IPC,RFHM,TCM
 SG_ Node30 : 22|1@0+ (1,0) [0|1] "-" BSM,IPC,RFHM,TCM
 SG_ Node31 : 23|1@0+ (1,0) [0|1] "-" BSM,IPC,RFHM,TCM
 SG_ Node4 : 44|1@0+ (1,0) [0|1] "-" BSM,IPC,RFHM,TCM
 SG_ Node5 : 45|1@0+ (1,0) [0|1] "-" BSM,IPC,RFHM,TCM
 SG_ Node6 : 46|1@0+ (1,0) [0|1] "-" BSM,IPC,RFHM,TCM
 SG_ Node7 : 47|1@0+ (1,0) [0|1] "-" BSM,IPC,RFHM,TCM
 SG_ Node8 : 32|1@0+ (1,0) [0|1] "-" BSM,IPC,RFHM,TCM
 SG_ Node9 : 33|1@0+ (1,0) [0|1] "-" BSM,IPC,RFHM,TCM
 SG_ WakeCntr_BCM : 15|8@0+ (1,0) [0|255] "-" Vector__XXX
 SG_ WakeRsn_BCM : 6|7@0+ (1,0) [0|127] "-" Vector__XXX

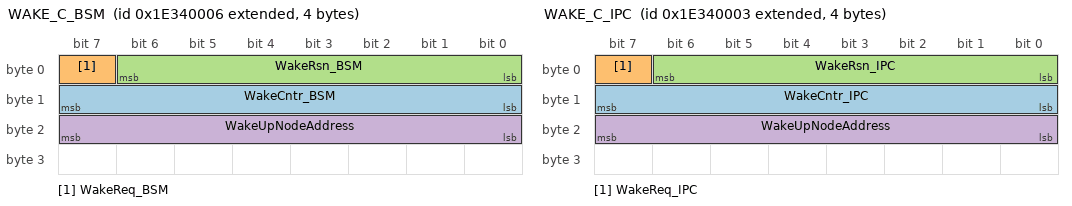
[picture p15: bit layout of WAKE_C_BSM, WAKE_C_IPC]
BO_ 2654208006 WAKE_C_BSM: 4 BSM
 SG_ WakeCntr_BSM : 15|8@0+ (1,0) [0|255] "" Vector__XXX
 SG_ WakeReq_BSM : 7|1@0+ (1,0) [0|1] "" BCM
 SG_ WakeRsn_BSM : 6|7@0+ (1,0) [0|127] "" Vector__XXX
 SG_ WakeUpNodeAddress : 23|8@0+ (1,0) [0|255] "" BCM

BO_ 2654208003 WAKE_C_IPC: 4 IPC
 SG_ WakeCntr_IPC : 15|8@0+ (1,0) [0|255] "" Vector__XXX
 SG_ WakeReq_IPC : 7|1@0+ (1,0) [0|1] "" BCM
 SG_ WakeRsn_IPC : 6|7@0+ (1,0) [0|127] "" Vector__XXX
 SG_ WakeUpNodeAddress : 23|8@0+ (1,0) [0|255] "" BCM

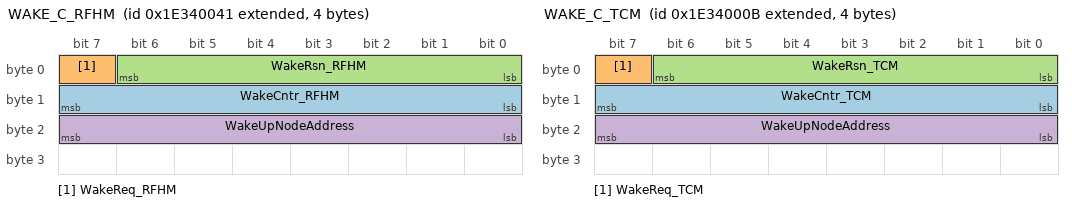
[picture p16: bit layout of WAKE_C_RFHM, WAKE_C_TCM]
BO_ 2654208065 WAKE_C_RFHM: 4 RFHM
 SG_ WakeCntr_RFHM : 15|8@0+ (1,0) [0|255] "" Vector__XXX
 SG_ WakeReq_RFHM : 7|1@0+ (1,0) [0|1] "" BCM
 SG_ WakeRsn_RFHM : 6|7@0+ (1,0) [0|127] "" Vector__XXX
 SG_ WakeUpNodeAddress : 23|8@0+ (1,0) [0|255] "" BCM

BO_ 2654208011 WAKE_C_TCM: 4 TCM
 SG_ WakeCntr_TCM : 15|8@0+ (1,0) [0|255] "" Vector__XXX
 SG_ WakeReq_TCM : 7|1@0+ (1,0) [0|1] "" BCM
 SG_ WakeRsn_TCM : 6|7@0+ (1,0) [0|127] "" Vector__XXX
 SG_ WakeUpNodeAddress : 23|8@0+ (1,0) [0|255] "" BCM

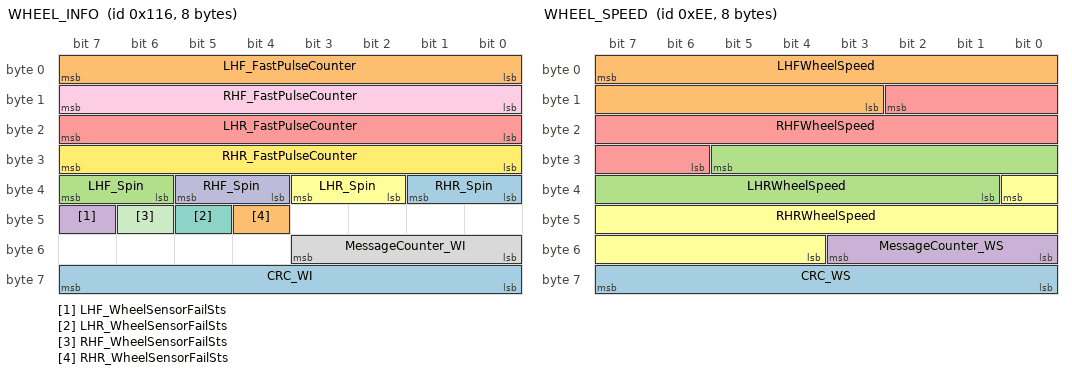
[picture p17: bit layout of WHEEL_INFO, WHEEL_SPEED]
BO_ 278 WHEEL_INFO: 8 BSM
 SG_ CRC_WI : 63|8@0+ (1,0) [0|255] "-" CDCM,DCTM,DTCM,RFHM,TCM
 SG_ LHF_FastPulseCounter : 7|8@0+ (1,0) [0|255] "pulse" BCM,DASM,RFHM
 SG_ LHF_Spin : 39|2@0+ (1,0) [0|3] "-" BCM,CDCM,DCTM,DTCM,TCM
 SG_ LHF_WheelSensorFailSts : 47|1@0+ (1,0) [0|1] "-" BCM,CDCM,DASM,DCTM,DTCM,RFHM,TCM
 SG_ LHR_FastPulseCounter : 23|8@0+ (1,0) [0|255] "pulse" BCM,DASM,ORC,RFHM
 SG_ LHR_Spin : 35|2@0+ (1,0) [0|3] "-" BCM,CDCM,DASM,DCTM,DTCM,TCM
 SG_ LHR_WheelSensorFailSts : 45|1@0+ (1,0) [0|1] "-" BCM,CDCM,DASM,DCTM,DTCM,RFHM,TCM
 SG_ MessageCounter_WI : 51|4@0+ (1,0) [0|15] "-" CDCM,DCTM,DTCM,RFHM,TCM
 SG_ RHF_FastPulseCounter : 15|8@0+ (1,0) [0|255] "pulse" BCM,DASM,RFHM
 SG_ RHF_Spin : 37|2@0+ (1,0) [0|3] "-" BCM,CDCM,DCTM,DTCM,TCM
 SG_ RHF_WheelSensorFailSts : 46|1@0+ (1,0) [0|1] "-" BCM,CDCM,DASM,DCTM,DTCM,RFHM,TCM
 SG_ RHR_FastPulseCounter : 31|8@0+ (1,0) [0|255] "pulse" BCM,DASM,ORC,RFHM
 SG_ RHR_Spin : 33|2@0+ (1,0) [0|3] "-" BCM,CDCM,DASM,DCTM,DTCM,TCM
 SG_ RHR_WheelSensorFailSts : 44|1@0+ (1,0) [0|1] "-" BCM,CDCM,DASM,DCTM,DTCM,RFHM,TCM

BO_ 238 WHEEL_SPEED: 8 BSM
 SG_ CRC_WS : 63|8@0+ (1,0) [0|255] "" CDCM,DASM,DCTM,DTCM,ECM,RFHM,TCM
 SG_ LHFWheelSpeed : 7|13@0+ (0.0625,0) [0|511.875] "Km/h" CDCM,DASM,DCTM,DTCM,ECM,ORC,RFHM,TCM
 SG_ LHRWheelSpeed : 29|13@0+ (0.0625,0) [0|511.875] "Km/h" CDCM,DASM,DCTM,DTCM,ECM,ORC,RFHM,TCM
 SG_ MessageCounter_WS : 51|4@0+ (1,0) [0|15] "" CDCM,DASM,DCTM,DTCM,ECM,RFHM,TCM
 SG_ RHFWheelSpeed : 10|13@0+ (0.0625,0) [0|511.875] "Km/h" CDCM,DASM,DCTM,DTCM,ECM,ORC,RFHM,TCM
 SG_ RHRWheelSpeed : 32|13@0+ (0.0625,0) [0|511.875] "Km/h" CDCM,DASM,DCTM,DTCM,ECM,ORC,RFHM,TCM

BO_TX_BU_ 2654339094 : AGSM,DCSM;
BO_TX_BU_ 503 : DCTM,TCM;
BO_TX_BU_ 260 : DCTM,TCM;
BO_TX_BU_ 1448 : DCTM,TCM;
CM_ SG_ 346 CRC_II "CRC according to SAE J1850 standard that has to be calculated from bit 63 to bit 8 at each frame transmission.";
CM_ SG_ 346 IMPACT_A "Front Pretensioner Event";
CM_ SG_ 346 IMPACT_B "EARS Rear Event";
CM_ SG_ 346 IMPACT_C "EARS Higher Severity Front Event";
CM_ SG_ 346 IMPACT_D "Less Severe Side Event";
CM_ SG_ 346 IMPACT_E "Rear Event";
CM_ SG_ 346 IMPACT_F "EARS Lower Severity Front Event";
CM_ SG_ 346 IMPACT_G "Not Used";
CM_ SG_ 346 IMPACT_H "Non-EARS RolloverEvent";
CM_ SG_ 346 IMPACT_I "EARS RolloverEvent";
CM_ SG_ 346 IMPACT_K "EARS Driver/Left Side Event";
CM_ SG_ 346 IMPACT_L "EARS Side Event";
CM_ SG_ 346 IMPACT_M "EARS Passenger/Right Side Event";
CM_ SG_ 346 IMPACT_O "Pedestrain Crash Event";
CM_ SG_ 346 IMPACTCommand "This signal is used to indicate that a crash happened";
CM_ SG_ 346 IMPACTConfirm "This signal is used to confirm that a crash happened";
CM_ SG_ 346 IMPACTFailSts "This signal is used to inform that an internal fault is present in the ORC";
CM_ SG_ 346 MessageCounter_II "This signal is a counter used for safety checks strategies. This counter is incremented of 1 (one) unit at each frame transmission.";
CM_ SG_ 1054 IBS_Current_Status "IBS Current Status";
CM_ SG_ 1054 IBS_Error_Calib "Error in IBS calibration data";
CM_ SG_ 1054 IBS_Error_Ident "Error in ECU identification";
CM_ SG_ 1054 IBS_Error_NVM "Error in IBS NVM data";
CM_ SG_ 1054 IBS_I_BATT "Battery current (Using I_Range resolution)";
CM_ SG_ 1054 IBS_I_RANGE "Current range sensor setting";
CM_ SG_ 1054 IBS_T_BATT "Battery temperature";
CM_ SG_ 1054 IBS_Temp_Status "IBS Temperature Status";
CM_ SG_ 1054 IBS_V_BATT "Batt. voltage measured at the terminals";
CM_ SG_ 1054 IBS_Voltage_Status "IBS Voltage Status";
CM_ SG_ 1056 IBS_SOC "State of charge";
CM_ SG_ 1056 IBS_SOC_Accuracy "SOC accuracy status";
CM_ SG_ 1056 IBS_SOF_Q "Residual battery charge in Ah";
CM_ SG_ 1056 IBS_SOF_Q_Accuracy "SOF_Q accuracy status";
CM_ SG_ 1056 IBS_SOF_V "Predicted battery voltage during cranking V2";
CM_ SG_ 1056 IBS_SOF_V_Accuracy "SOF_V accuracy status";
CM_ SG_ 1056 IBS_SOH_Q "State of health";
CM_ SG_ 1056 IBS_SOH_Q_Accuracy "SOH_Q accuracy status";
CM_ SG_ 256 EngineNuenRq "This signal indicates the request for NueN functionality";
CM_ SG_ 256 EngineSailingRq "This signal indicates the request for Sailing functionality";
CM_ SG_ 256 EngTrq_Enbl_Rq_TCM "Allow TRANS torque request";
CM_ SG_ 244 CANErr "This is a feedback on the status of communication between ECM and DCTM.
There are 4 possible cases:
A. No CAN message received from DCTM (time out).
B. Unplausible message
C. Unplausible command
D. Not used.";
CM_ SG_ 244 CylCutEnabled "Fuel cut strategy enable flag. Informs the gearbox that one or more cylinders are currently in fuel cut-off.";
CM_ SG_ 244 EngineAtLimiter "Informs the gearbox that the engine speed limiter is currently active.";
CM_ SG_ 244 EngineIdleRefSpeed "This signal represents target of engine speed for the idle control function, at the end of dynamic transient conditions. It takes into account changes of idle speed due to temperature and auxiliary loads. It is updated even when the engine is ou(...)";
CM_ SG_ 244 EngineSlaveModeActive "Acknowledge of the slave mode by the ECM.";
CM_ SG_ 244 FutureTorque "Driver torque which will be active in the target gear/target speed during gearshift/pullaway.";
CM_ SG_ 244 NmaxControllerActive "Acknowledge of max engine speed limitation from the ECM.";
CM_ SG_ 244 Psben "This signal indicate inhibition of gear shift down";
CM_ SG_ 500 EngineReadyForESS "ESS request HIS charget (1=do charge)";
CM_ SG_ 500 GrMax_Rq_ECM "Target gear upper limit (ECM requested limit)";
CM_ SG_ 500 MaxInstTorque "Maximum torque currently deliverable by the engine through spark advance control";
CM_ SG_ 500 MinInstTorque "Minimum torque currently deliverable by the engine through spark advance control";
CM_ SG_ 1047 ESS_ActvEBrake "Stop start system requests shifting to park";
CM_ SG_ 1042 AccelPdlPosn_OBD "Pedal value for OBD (ISO 15031-5.4 PID 49)";
CM_ SG_ 1042 CARB_PERM "Fault code for diagnostics.";
CM_ SG_ 1042 CarbWarmUp "CARB warmup criteria true.  The engine controller will set this bit when the engine coolant temp achieves the CARB warm-up criteria.";
CM_ SG_ 1042 CldStrtDenominator "Cold start denominator conditions are met [1]";
CM_ SG_ 1042 EngineOFFTime "The number of minutes the engine was off.";
CM_ SG_ 1042 GenDenominator "General denominator conditions are met.  The engine controller will set this bit when the conditions for setting the General Denominator are met for rate based diagnostics.";
CM_ SG_ 1042 IgnCntrTrue "Ignition cycle counter is true [1]";
CM_ SG_ 1042 Inp_CSD_Fail "Inputs to the cold start denominator are in a pend or MIL fault.";
CM_ SG_ 1042 Inp_ICC_Fail "Inputs to the Ign Cycle Cntr are in a Pend or MIL cond.";
CM_ SG_ 1042 InputsGDFail "General Denominator Requirements Achieved Validity. The engine controller sets this bit when any of the inputs to the General Denominator are in a pending or MIL fault.";
CM_ SG_ 1042 LoadOBD "Engine calculated load value in percentage of load.";
CM_ SG_ 495 CRC_RF1 "CRC according to SAE J1850 standard that has to be calculated at each frame transmission";
CM_ SG_ 495 DriverEngineOffRequest "The signal is used to inform that an engine shut off is requried by the driver";
CM_ SG_ 495 FobSearchResult "FOB search result";
CM_ SG_ 495 Message_Counter_RF1 "This signal is a counter used for safety checks strategies. This counter is incremented of 1 (one) unit at each frame transmission";
CM_ SG_ 1848 MsgFOBLeftVeh "FOB left vehicle";
CM_ SG_ 1848 MsgFOBNotFnd "FOB Not Detected.";
CM_ SG_ 402 CRC_SBWM "CRC according to SAE J1850 standard that has to be calculated from bit 63 to bit 8 at each frame transmission";
CM_ SG_ 402 DRV_RQ_LKOUT "This signals gives the information of the Driver requested shifter lockout release switch";
CM_ SG_ 402 DRV_RQ_SHFT_FNG "This signal gives the information of the Driver requested gear shift position";
CM_ SG_ 402 MC_SBWM "This signal is a counter used for safety checks strategies. This counter is incremented of 1 (one) unit at each frame transmission.";
CM_ SG_ 402 SHF_FLT "This signal indicates the fault of the Lever";
CM_ SG_ 402 SHFT_P_BUTTON "This signals gives the information of the Driver request P-button";
CM_ SG_ 762 ACC_DistSts "ACC distance switch regulation";
CM_ SG_ 762 ACC_OnOffSts "This signal is used to give information about adaptive cruise control on/off button activation.";
CM_ SG_ 762 CRC_CSWC_1 "CRC according to SAE J1850 standard that has to be calculated from bit 63 to bit 48 at each frame transmission.";
CM_ SG_ 762 Crono_OnOffSts "This signal indicates the status to enable/disable the Chronometer functionality";
CM_ SG_ 762 CruiseControlFailSts "This signal is used to give information about a fault on cruise control commands.";
CM_ SG_ 762 CruiseControlOnOffSts "This signal is used to give information about cruise control on/off button activation.";
CM_ SG_ 762 HDC_OnOffSts "This signal is used to give information about HDC on/off button activation.";
CM_ SG_ 762 MC_CSWC_1 "This signal is a counter used for safety checks strategies. This counter is incremented of 1 (one) unit at each frame transmission.";
CM_ SG_ 762 ResumeSwitch "This signal is used to give information about cruise control RESUME button activation.";
CM_ SG_ 762 SpeedRockerSts "This signal is used to give information about speed rocker request";
CM_ SG_ 2654339129 CurrentFailSts_DASM "The signal indicates that a present fault exists on node";
CM_ SG_ 2654339129 DES_DASM "The signal indicates the CAN Controller status";
CM_ SG_ 2654339129 EOL_DASM "This signal indicates if it is required/not required to the node to partecipate to the PROXI procedure.";
CM_ SG_ 2654339129 GenericFailSts_DASM "The signal indicates that one or more cells containing fault information exist on node memory.";
CM_ SG_ 2654339139 CurrentFailSts_DTCM "The signal indicates that a present fault exists on node";
CM_ SG_ 2654339139 DES_DTCM "The signal indicates the CAN Controller status";
CM_ SG_ 2654339139 EOL_DTCM "This signal indicates if it is required/not required to the node to partecipate to the PROXI procedure.";
CM_ SG_ 2654339139 GenericFailSts_DTCM "The signal indicates that one or more cells containing fault information exist on node memory.";
CM_ SG_ 2654339073 CurrentFailSts_ECM "The signal indicates that a present fault exists on node";
CM_ SG_ 2654339073 DES_ECM "The signal indicates the CAN Controller status";
CM_ SG_ 2654339073 EOL_ECM "This signal indicates if it is required/not required to the node to partecipate to the PROXI procedure.";
CM_ SG_ 2654339073 GenericFailSts_ECM "The signal indicates that one or more cells containing fault information exist on node memory.";
CM_ SG_ 2654339075 CurrentFailSts_IPC "The signal indicates that a present fault exists on node";
CM_ SG_ 2654339075 DES_IPC "The signal indicates the CAN Controller status";
CM_ SG_ 2654339075 EOL_IPC "This signal indicates if it is required/not required to the node to partecipate to the PROXI procedure.";
CM_ SG_ 2654339075 GenericFailSts_IPC "The signal indicates that one or more cells containing fault information exist on node memory.";
CM_ SG_ 2654339137 CurrentFailSts_RFHM "The signal indicates that a present fault exists on node";
CM_ SG_ 2654339137 DES_RFHM "The signal indicates the CAN Controller status";
CM_ SG_ 2654339137 EOL_RFHM "This signal indicates if it is required/not required to the node to partecipate to the PROXI procedure.";
CM_ SG_ 2654339137 GenericFailSts_RFHM "The signal indicates that one or more cells containing fault information exist on node memory.";
CM_ SG_ 2654339094 CurrentFailSts_Shifter "The signal indicates that a present fault exists on node";
CM_ SG_ 2654339094 DES_Shifter "The signal indicates the CAN Controller status";
CM_ SG_ 2654339094 EOL_Shifter "This signal indicates if it is required/not required to the node to partecipate to the PROXI procedure.";
CM_ SG_ 2654339094 GenericFailSts_Shifter "The signal indicates that one or more cells containing fault information exist on node memory.";
CM_ SG_ 2654339083 CurrentFailSts_Transmission "The signal indicates that a present fault exists on node";
CM_ SG_ 2654339083 DES_Transmission "The signal indicates the CAN Controller status";
CM_ SG_ 2654339083 EOL_Transmission "This signal indicates if it is required/not required to the node to partecipate to the PROXI procedure.";
CM_ SG_ 2654339083 GenericFailSts_Transmission "The signal indicates that one or more cells containing fault information exist on node memory.";
CM_ SG_ 508 ADC_FailSts "Tihs signal indicates the fail status of ADC control";
CM_ SG_ 508 ADC_STS "This signal indicates the state of ADC control";
CM_ SG_ 508 Aero_FailSts "Tihs signal indicates the fail status of Aero system";
CM_ SG_ 508 CDCM_WarningLamp "This signal indicates the request for CDCM_Warning_Lamp";
CM_ SG_ 508 FrontAeroSts "This signal indicates the status of the Front Aero System";
CM_ SG_ 508 RdAspInd "This signal indicates the road asperity index estimated by CDCM";
CM_ SG_ 508 Rear_Diff_Control_Sts "This signal indicates the Status of Rear Differential Control.";
CM_ SG_ 508 Rear_Diff_WarningLamp "This signal indicates the request for Rear_Differential_Warning_Lamp";
CM_ SG_ 1852 ACC_RadarBlinded "It communicate if the Radar is blinded or not";
CM_ SG_ 1852 ACC_SetSpeedKPH "Speed shown by IPC, which ACC is controlling in KPH";
CM_ SG_ 1852 ACC_SetSpeedMPH "Speed shown by IPC, which ACC is controlling in MPH";
CM_ SG_ 1852 ACCFailSts "It informs about an ACC failure visualized in the IPC";
CM_ SG_ 1852 ACCSystemSts "It indicates ACC/NCC system status";
CM_ SG_ 1852 CameraBlinded "This signal is used to indicate the presence of an occlusion on the camera";
CM_ SG_ 1852 CameraFailure "This signal is used to indicate the presence of a failure in the camera";
CM_ SG_ 1852 CHIME_TYPSts "Selects Chime Type for ACC & FCW.";
CM_ SG_ 1852 DASMFailSts "This signal is used to indicate the presence of a permanent failure in the ECU";
CM_ SG_ 1852 DASMTemporaryFailSts "This signal is used to indicate the presence of a temporary failure in the ECU";
CM_ SG_ 1852 FCWSts "This signal is used to indicate the type of intervention set by customer";
CM_ SG_ 1852 FCWSystemSts "This signal is used to indicate the actual system status of FCW features";
CM_ SG_ 1852 HMICode_ACC "It is used in order to command ACC and NCC warnings and failures.";
CM_ SG_ 1852 HMICode_ACC_Ind "Used to activate the HMIDisplay_ACC indications on the IPC";
CM_ SG_ 1852 HMICode_FCW "Signal to activate HMI indication on IPC";
CM_ SG_ 1852 HMIDisplay_ACC "It indicates the status of ACC/NCC, visualized in the IPC.";
CM_ SG_ 1852 NCCFailSts "It informs about an NCC failure visualized in the IPC";
CM_ SG_ 1852 RadarBlinded "This signal is used to indicate the presence of an occlusion on the radar";
CM_ SG_ 242 Auto_Manual_Button_Sts "This signal is usedto indicate the status of the Auto/Manual Button";
CM_ SG_ 242 Buttons_Fault_Sts "This signal is use to indicate the Fail Status of the DCMS";
CM_ SG_ 242 CRC_StsDCSM "CRC according to SAE J1850 standard that has to be calculated from bit 63 to bit 8 at each frame transmission.";
CM_ SG_ 242 Launch_Button_Sts "This signal is use to indicate the status of the Launch_Button";
CM_ SG_ 242 MessageCounter_StsDCSM "This signal is a counter used for safety checks strategies. This counter is incremented of 1 (one) unit at each frame transmission.";
CM_ SG_ 242 Park_Button_Sts "This signal is use to indicate the status of the Park_Button";
CM_ SG_ 242 Reverse_Button_Sts "This signal is use to indicate the status of the Reverse_Button";
CM_ SG_ 1454 ChkFuelCap "This signal gives indication about loose fuel cap.";
CM_ SG_ 1454 ColdStartLampIndication "This signal gives indications about starting strategies in case of engine cold start.";
CM_ SG_ 1454 CompressorSts "This signal gives information about the present status of A/C external request and actual A/C activation by ECM.";
CM_ SG_ 1454 DPFSts "It is required only on diesel systems equipped with Diesel Particulate Filter. It is used to signalize that the current operating conditions (engine load, DPF pressure and temperature) do not allow performing the DPF regeneration strategy (signa(...)";
CM_ SG_ 1454 EMSFailSts "This signal is used  to switch on and off the engine control system warning lamp (called MI for EOBD applications)";
CM_ SG_ 1454 EngineOperatingMode "This signal indicates the engine operating mode (normal or after-treatment systems regeneration)";
CM_ SG_ 1454 EngineWaterTempWarningLightSts "It is the information about water overtemperature light status.";
CM_ SG_ 1454 ETCFailSts "This signal is used  to switch on and off  ETC lamp to give informations about faults not EOBD relevant.";
CM_ SG_ 1454 ExhaustTemperature "This signal indicates the exhaust engine temperature after combustion or after-treatment systems (if applicable)";
CM_ SG_ 1454 FuelFilterHeaterReq "This signal is used to require the fuel filter heating.";
CM_ SG_ 1454 FuelWaterPresentFailSts "The signal is required on diesel systems only. It is the Fail Status bit of FuelWaterPresentSts signal.";
CM_ SG_ 1454 FuelWaterPresentSts "This signal is send if water is present on the fuel. It is required on diesel systems only.";
CM_ SG_ 1454 GlowPlugFailSts "It is the information that a fault is detected by glow plug control unit; it is transmitted on diesel systems only.";
CM_ SG_ 1454 GlowPlugLampSts "The signal is required on diesel systems only. It is the glow plug light command";
CM_ SG_ 1454 OilLifeSts "This information is related to engine oil life algorithm, currently used on Diesel engines equipped with DPF.";
CM_ SG_ 1454 OilPressureFailSts "It is the Fail Status bit of OilPressure signal.";
CM_ SG_ 1454 OilPressureSts "This signal  indicates oil pressure status (High or low).";
CM_ SG_ 1504 EPB_HMI_Management "Management IPC/VP pop-up";
CM_ SG_ 1504 EPBAutoAppSts "Status of AutoApply Functionality";
CM_ SG_ 1504 EPBFailureLampReq "This signal is used to request the EPB failure indication";
CM_ SG_ 1504 EPBMaintenanceSts "Status of Maintenance Functionality";
CM_ SG_ 1504 EPBSts "This signal describes the EPB status";
CM_ SG_ 1504 EPBSwitchPosition "This signal is used to give information about the postition of the EPB switch";
CM_ SG_ 1504 RedLampReq "This signal is used to request the EPB RED Indication";
CM_ SG_ 1196 InflationState_LHF_Tyre "It signal indicated the state for the pressure of the wheel identified";
CM_ SG_ 1196 InflationState_LHR_Tyre "It signal indicated the state for the pressure of the wheel identified";
CM_ SG_ 1196 InflationState_RHF_Tyre "It signal indicated the state for the pressure of the wheel identified";
CM_ SG_ 1196 InflationState_RHR_Tyre "It signal indicated the state for the pressure of the wheel identified";
CM_ SG_ 1196 PressureValue_LHF_Tyre "It is the value of indicated tyre wheel [bar]";
CM_ SG_ 1196 PressureValue_LHR_Tyre "It is the value of indicated tyre wheel [bar]";
CM_ SG_ 1196 PressureValue_RHF_Tyre "It is the value of indicated tyre wheel [bar]";
CM_ SG_ 1196 PressureValue_RHR_Tyre "It is the value of indicated tyre wheel [bar]";
CM_ SG_ 1196 TPMActivitySts "It indicates whether the TPMS ECU is enabled or disabled.";
CM_ SG_ 1196 TyrePressureSysProgrammedSts "It indicates the TPMS ECU programming status.";
CM_ SG_ 1196 TyrePressureSystemFailSts "It indicates that the TPM System is in Fault or not";
CM_ SG_ 1992 TrailerConnectionSts "Connection status of TTM";
CM_ SG_ 1992 TrailerGenericFailSts "Status of Fail of TTM";
CM_ SG_ 1850 Day1 "It is the first digit of the day for the date visualization";
CM_ SG_ 1850 Day2 "It is the second digit of the day for the date visualization";
CM_ SG_ 1850 Hour1 "It is the first digit of the hours for the clock visualization";
CM_ SG_ 1850 Hour2 "It is the second digit of the hours for the clock visualization";
CM_ SG_ 1850 Minute1 "It is  the first digit of the minutes for the clock visualization";
CM_ SG_ 1850 Minute2 "It is the second digit of the minutes for the clock visualization";
CM_ SG_ 1850 Month1 "It is the first digit of the month for the date visualization";
CM_ SG_ 1850 Month2 "It is the second digit of the month for the date visualization";
CM_ SG_ 1850 Year1 "It is the first digit of the year for the date visualization";
CM_ SG_ 1850 Year2 "It is the second digit of the year for the date visualization";
CM_ SG_ 1850 Year3 "It is the third digit of the year for the date visualization";
CM_ SG_ 1850 Year4 "It is the fourth digit of the year for the date visualization";
CM_ SG_ 240 EngTrq_Rq_TCM "Requested engine torque";
CM_ SG_ 240 EngTrq_Rq_TCM_Slow "Slow path torque request from transmission to be actuated by throttle";
CM_ SG_ 240 MaxTrqDes "Maximum engine torque desired";
CM_ SG_ 240 TorqueConverterSTO "Conf. (torque converter lock-up) \"Starts to open\"";
CM_ SG_ 240 TorqueConverterSts "This signal indicates the control phase of lockup clutch.";
CM_ SG_ 240 TrqCtrlModeReq "Torque control mode request";
CM_ SG_ 240 TrqCtrlModeReq_Slow "Slow path torque control mode request";
CM_ SG_ 503 CRC_TM2 "Checksum";
CM_ SG_ 503 MC_TM2 "Message Counter";
CM_ SG_ 236 CutRequest "Engine fuel cut request from DCTM";
CM_ SG_ 236 DCTMGbProtectionSpeed "Protection maximum engine speed request value active flag from DCTM. Maximum speed value will be sent on ReqEngineSpeed";
CM_ SG_ 236 DCTMGbProtectionTorque "Protection maximum engine torque request value active flag from DCTM. Maximum torque value will be sent on ReqTorqueValue.";
CM_ SG_ 236 DCTState "See DCT State Definition";
CM_ SG_ 236 EngineSlaveRequest "Speed or Torque request from DCTM active flag";
CM_ SG_ 236 FutureSyncGear "Target gear for upcoming gearshift used by ECM for calibration switching.";
CM_ SG_ 236 FutureSyncRPM "Final synchronization engine speed for upcoming gearshift/pullaway used by ECM for calibration switching.";
CM_ SG_ 236 ReqEngineSpeed "Engine Speed request from DCTM";
CM_ SG_ 236 ReqTorqueValue "Engine Torque request from DCTM";
CM_ SG_ 260 Garage_SIP "This signal indicates the control phase of lockup clutch.";
CM_ SG_ 260 TorqueAmpTransmission "It is the torque transmission ratio from gearbox primary to wheels, calculated by gearbox . It is only used in Automatic Transmission application";
CM_ SG_ 260 TransmissionNuenSts "This signal indicates the status of the Nuen functionality";
CM_ SG_ 260 TransmissionSailingSts "This signal indicates the status of the Sailing functionality";
CM_ SG_ 1448 CrankEnable "This signal is used to enable the cranking in safety condition";
CM_ SG_ 1448 GearEngaged "Current engaged gear.";
CM_ SG_ 1448 LimpHomeSts "This signal is used in case of those gearbox faults that limit the higher usable gear.";
CM_ SG_ 1448 MIReq "This signal indicates that the gearbox has any EOBD errors.";
CM_ SG_ 1448 ShiftInProgress "Transmission shift in progress";
CM_ SG_ 1448 TargetGear "Tells of the intended target gear that the transmission will be shifting to. Also includes an cancel shift that the DASM uses for better control.";
CM_ SG_ 1448 TemporaryManualSts "This signal indicates a temporary manual Status of the GearBox";
CM_ SG_ 1448 TxDisengaged "Transmission is disengaged";
CM_ SG_ 1448 UpDownShiftSel "When the bit is switching from ON to OFF, the clutch is engaging and the vehicle is driving away from stop condition";
CM_ SG_ 234 ActiveGearRatio "Current gearbox transmission ratio, defined as a continous profile during gearshift";
CM_ SG_ 234 AMTIndex "Percentage of AMT Gearshift simulation strategy";
CM_ SG_ 234 ClutchStatus "Current operating state defined from combining the actual state of both clutches";
CM_ SG_ 234 CutOffTime "DCTM request to prevent the ECM from entering fuel cut-off mode";
CM_ SG_ 234 ESPReqFulfillDCTM "ESP torque cut request fulfilled by DCTM strategy";
CM_ SG_ 234 GearBoxAbsorption "Loss torque from gearbox";
CM_ SG_ 234 LaunchActive "Additional flag reserved for possible Launch control implementations.";
CM_ SG_ 253 CodeCheckSts_TRM "This signal is used to indicate the result of the code check.";
CM_ SG_ 253 ProgrammedSts_TRM "This signal  is used to indicate if the TRM is programmed.";
CM_ SG_ 253 TxpFound "This signal is used to give information about the presence of a transponder";
CM_ SG_ 253 TxpID "This signal is used to give information about the transponder authentication.";
CM_ SG_ 1046 VIN_DATA "VIN Digits (8 bit ascii encoded)";
CM_ SG_ 1046 VIN_MSG "VIN Message Information";
CM_ SG_ 2654208000 MainWakeSts_BCM "Main wakeup status from BCM";
CM_ SG_ 2654208000 Node0 "Node 0 wakeup active";
CM_ SG_ 2654208000 Node1 "Node 1 wakeup active";
CM_ SG_ 2654208000 Node10 "Node 10 wakeup active";
CM_ SG_ 2654208000 Node11 "Node 11 wakeup active";
CM_ SG_ 2654208000 Node12 "Node 12 wakeup active";
CM_ SG_ 2654208000 Node13 "Node 13 wakeup active";
CM_ SG_ 2654208000 Node14 "Node 14 wakeup active";
CM_ SG_ 2654208000 Node15 "Node 15 wakeup active";
CM_ SG_ 2654208000 Node16 "Node 16 wakeup active";
CM_ SG_ 2654208000 Node17 "Node 17 wakeup active";
CM_ SG_ 2654208000 Node18 "Node 18 wakeup active";
CM_ SG_ 2654208000 Node19 "Node 19 wakeup active";
CM_ SG_ 2654208000 Node2 "Node 2 wakeup active";
CM_ SG_ 2654208000 Node20 "Node 20 wakeup active";
CM_ SG_ 2654208000 Node21 "Node 21 wakeup active";
CM_ SG_ 2654208000 Node22 "Node 22 wakeup active";
CM_ SG_ 2654208000 Node23 "Node 23 wakeup active";
CM_ SG_ 2654208000 Node24 "Node 24 wakeup active";
CM_ SG_ 2654208000 Node25 "Node 25 wakeup active";
CM_ SG_ 2654208000 Node26 "Node 26 wakeup active";
CM_ SG_ 2654208000 Node27 "Node 27 wakeup active";
CM_ SG_ 2654208000 Node28 "Node 28 wakeup active";
CM_ SG_ 2654208000 Node29 "Node 29 wakeup active";
CM_ SG_ 2654208000 Node3 "Node 3 wakeup active";
CM_ SG_ 2654208000 Node30 "Node 30 wakeup active";
CM_ SG_ 2654208000 Node31 "Node 31 wakeup active";
CM_ SG_ 2654208000 Node4 "Node 4 wakeup active";
CM_ SG_ 2654208000 Node5 "Node 5 wakeup active";
CM_ SG_ 2654208000 Node6 "Node 6 wakeup active";
CM_ SG_ 2654208000 Node7 "Node 7 wakeup active";
CM_ SG_ 2654208000 Node8 "Node 8 wakeup active";
CM_ SG_ 2654208000 Node9 "Node 9 wakeup active";
CM_ SG_ 2654208000 WakeCntr_BCM "Wakeup counter for BCM";
CM_ SG_ 2654208000 WakeRsn_BCM "Wakeup reason for BCM";
CM_ SG_ 2654208006 WakeCntr_BSM "Wakeup counter for BSM.";
CM_ SG_ 2654208006 WakeReq_BSM "Wakeup request bit for BSM.";
CM_ SG_ 2654208006 WakeRsn_BSM "Wakeup reason for BSM.";
CM_ SG_ 2654208003 WakeCntr_IPC "Wakeup counter for SCCM";
CM_ SG_ 2654208003 WakeReq_IPC "Wakeup request bit for SCCM";
CM_ SG_ 2654208003 WakeRsn_IPC "Wakeup reason for SCCM";
CM_ SG_ 2654208065 WakeCntr_RFHM "Wakeup counter for RFHM";
CM_ SG_ 2654208065 WakeReq_RFHM "Wakeup request bit for RFHM";
CM_ SG_ 2654208065 WakeRsn_RFHM "Wakeup reason for RFHM";
CM_ SG_ 2654208011 WakeCntr_TCM "Wakeup counter for TCM";
CM_ SG_ 2654208011 WakeReq_TCM "Wakeup request bit for TCM";
CM_ SG_ 2654208011 WakeRsn_TCM "Wakeup reason for TCM";
CM_ SG_ 278 CRC_WI "CRC according to SAE J1850 standard that has to be calculated from bit 63 to bit 8 at each frame transmission.";
CM_ SG_ 278 LHF_FastPulseCounter "This signal is the left front wheel pulse counter.";
CM_ SG_ 278 LHF_Spin "This signal indicates the left hand front wheel status";
CM_ SG_ 278 LHF_WheelSensorFailSts "This signal indicates the fail status of LHF sensor";
CM_ SG_ 278 LHR_FastPulseCounter "This signal is the left rear wheel pulse counter.";
CM_ SG_ 278 LHR_Spin "This signal indicates the left hand rear wheel status";
CM_ SG_ 278 LHR_WheelSensorFailSts "This signal indicates the fail status of LHR sensor";
CM_ SG_ 278 MessageCounter_WI "This signal is a counter used for safety checks strategies. This counter is incremented of 1 (one) unit at each frame transmission.";
CM_ SG_ 278 RHF_FastPulseCounter "This signal is the right front wheel pulse counter.";
CM_ SG_ 278 RHF_Spin "This signal indicates the right hand front wheel status";
CM_ SG_ 278 RHF_WheelSensorFailSts "This signal indicates the fail status of RHF sensor";
CM_ SG_ 278 RHR_FastPulseCounter "This signal is the right rear wheel pulse counter.";
CM_ SG_ 278 RHR_Spin "This signal indicates the right hand rear wheel status";
CM_ SG_ 278 RHR_WheelSensorFailSts "This signal indicates the fail status of RHR sensor";
CM_ SG_ 238 CRC_WS "CRC according to SAE J1850 standard that has to be calculated from bit 63 to bit 8 at each frame transmission.";
CM_ SG_ 238 LHFWheelSpeed "This is the value of the left front wheel speed";
CM_ SG_ 238 LHRWheelSpeed "This is the value of the left rear wheel speed";
CM_ SG_ 238 MessageCounter_WS "This signal is a counter used for safety checks strategies. This counter is incremented of 1 (one) unit at each frame transmission.";
CM_ SG_ 238 RHFWheelSpeed "This is the value of the right front wheel speed";
CM_ SG_ 238 RHRWheelSpeed "This is the value of the right rear wheel speed";

BA_DEF_ SG_ "Accuracy" STRING ;
BA_DEF_ SG_ "Event trans." ENUM "Yes","No";
BA_DEF_ SG_ "GenSigStartValue" INT 0 2147483647;
BA_DEF_ SG_ "GenSigInactiveValue" INT 0 2147483647;
BA_DEF_ SG_ "GenSigSendType" ENUM "NotUsed","OnWrite","OnWriteWithRepetition","OnChange","OnChangeWithRepetition","IfActive","IfActiveWithRepetition","NoSigSendType";
BA_DEF_ BO_ "DiagRequest" ENUM "No","Yes";
BA_DEF_ BO_ "Period [ms]" INT 0 65535;
BA_DEF_ BO_ "Type" ENUM "P","C","PE","COC","PE_Cntrl","E","E_Cntrl","OC","S","BAF","DC","EM","MM","-";
BA_DEF_ BO_ "DiagResponse" ENUM "No","Yes";
BA_DEF_ BO_ "NmMessage" ENUM "No","Yes";
BA_DEF_ BO_ "GenMsgSendType" ENUM "Cyclic","NotUsed","NotUsed","NotUsed","NotUsed","NotUsed","NotUsed","NotUsed","NoMsgSendType";
BA_DEF_ BO_ "GenMsgTimeoutTime" INT 0 10000;
BA_DEF_ BO_ "GenMsgNrOfRepetition" INT 0 255;
BA_DEF_ BO_ "GenMsgILSupport" ENUM "No","Yes";
BA_DEF_ BO_ "GenMsgStartDelayTime" INT 0 65535;
BA_DEF_ BO_ "GenMsgCycleTimeFast" INT 0 65535;
BA_DEF_ BO_ "GenMsgCycleTime" INT 0 65535;
BA_DEF_ BO_ "GenMsgDelayTime" INT 0 65535;
BA_DEF_ BO_ "DiagState" ENUM "No","Yes";
BA_DEF_DEF_ "Accuracy" "";
BA_DEF_DEF_ "Event trans." "No";
BA_DEF_DEF_ "GenSigStartValue" 0;
BA_DEF_DEF_ "GenSigInactiveValue" 0;
BA_DEF_DEF_ "GenSigSendType" "NoSigSendType";
BA_DEF_DEF_ "DiagRequest" "No";
BA_DEF_DEF_ "Period [ms]" 0;
BA_DEF_DEF_ "Type" "-";
BA_DEF_DEF_ "DiagResponse" "No";
BA_DEF_DEF_ "NmMessage" "No";
BA_DEF_DEF_ "GenMsgSendType" "NoMsgSendType";
BA_DEF_DEF_ "GenMsgTimeoutTime" 0;
BA_DEF_DEF_ "GenMsgNrOfRepetition" 0;
BA_DEF_DEF_ "GenMsgILSupport" "No";
BA_DEF_DEF_ "GenMsgStartDelayTime" 0;
BA_DEF_DEF_ "GenMsgCycleTimeFast" 0;
BA_DEF_DEF_ "GenMsgCycleTime" 0;
BA_DEF_DEF_ "GenMsgDelayTime" 0;
BA_DEF_DEF_ "DiagState" "No";
BA_ "Period [ms]" BO_ 346 500;
BA_ "Type" BO_ 346 10;
BA_ "GenMsgSendType" BO_ 346 0;
BA_ "GenMsgILSupport" BO_ 346 1;
BA_ "GenMsgStartDelayTime" BO_ 346 250;
BA_ "GenMsgCycleTimeFast" BO_ 346 10;
BA_ "GenMsgCycleTime" BO_ 346 500;
BA_ "Period [ms]" BO_ 1054 100;
BA_ "Type" BO_ 1054 1;
BA_ "GenMsgSendType" BO_ 1054 0;
BA_ "GenMsgILSupport" BO_ 1054 1;
BA_ "GenMsgCycleTime" BO_ 1054 100;
BA_ "Period [ms]" BO_ 1056 100;
BA_ "Type" BO_ 1056 1;
BA_ "GenMsgSendType" BO_ 1056 0;
BA_ "GenMsgILSupport" BO_ 1056 1;
BA_ "GenMsgCycleTime" BO_ 1056 100;
BA_ "Period [ms]" BO_ 256 10;
BA_ "Type" BO_ 256 1;
BA_ "GenMsgSendType" BO_ 256 0;
BA_ "GenMsgILSupport" BO_ 256 1;
BA_ "GenMsgStartDelayTime" BO_ 256 8;
BA_ "GenMsgCycleTime" BO_ 256 10;
BA_ "Period [ms]" BO_ 244 10;
BA_ "Type" BO_ 244 1;
BA_ "GenMsgSendType" BO_ 244 0;
BA_ "GenMsgILSupport" BO_ 244 1;
BA_ "GenMsgStartDelayTime" BO_ 244 2;
BA_ "GenMsgCycleTime" BO_ 244 10;
BA_ "Period [ms]" BO_ 500 20;
BA_ "Type" BO_ 500 1;
BA_ "GenMsgSendType" BO_ 500 0;
BA_ "GenMsgILSupport" BO_ 500 1;
BA_ "GenMsgStartDelayTime" BO_ 500 4;
BA_ "GenMsgCycleTime" BO_ 500 20;
BA_ "Period [ms]" BO_ 1047 100;
BA_ "Type" BO_ 1047 1;
BA_ "GenMsgSendType" BO_ 1047 0;
BA_ "GenMsgILSupport" BO_ 1047 1;
BA_ "GenMsgStartDelayTime" BO_ 1047 48;
BA_ "GenMsgCycleTime" BO_ 1047 100;
BA_ "Period [ms]" BO_ 1042 100;
BA_ "Type" BO_ 1042 1;
BA_ "GenMsgSendType" BO_ 1042 0;
BA_ "GenMsgILSupport" BO_ 1042 1;
BA_ "GenMsgStartDelayTime" BO_ 1042 14;
BA_ "GenMsgCycleTime" BO_ 1042 100;
BA_ "Period [ms]" BO_ 495 20;
BA_ "Type" BO_ 495 1;
BA_ "GenMsgSendType" BO_ 495 0;
BA_ "GenMsgILSupport" BO_ 495 1;
BA_ "GenMsgStartDelayTime" BO_ 495 10;
BA_ "GenMsgCycleTime" BO_ 495 20;
BA_ "Period [ms]" BO_ 1848 1000;
BA_ "Type" BO_ 1848 3;
BA_ "GenMsgSendType" BO_ 1848 0;
BA_ "GenMsgILSupport" BO_ 1848 1;
BA_ "GenMsgStartDelayTime" BO_ 1848 500;
BA_ "GenMsgCycleTime" BO_ 1848 1000;
BA_ "GenMsgDelayTime" BO_ 1848 20;
BA_ "Period [ms]" BO_ 402 10;
BA_ "Type" BO_ 402 1;
BA_ "GenMsgSendType" BO_ 402 0;
BA_ "GenMsgILSupport" BO_ 402 1;
BA_ "GenMsgStartDelayTime" BO_ 402 10;
BA_ "GenMsgCycleTime" BO_ 402 10;
BA_ "Type" BO_ 762 11;
BA_ "GenMsgTimeoutTime" BO_ 762 2500;
BA_ "GenMsgILSupport" BO_ 762 1;
BA_ "Period [ms]" BO_ 2654339129 1000;
BA_ "Type" BO_ 2654339129 1;
BA_ "GenMsgSendType" BO_ 2654339129 0;
BA_ "GenMsgTimeoutTime" BO_ 2654339129 2500;
BA_ "GenMsgILSupport" BO_ 2654339129 1;
BA_ "GenMsgStartDelayTime" BO_ 2654339129 500;
BA_ "GenMsgCycleTime" BO_ 2654339129 1000;
BA_ "Period [ms]" BO_ 2654339139 1000;
BA_ "Type" BO_ 2654339139 1;
BA_ "GenMsgSendType" BO_ 2654339139 0;
BA_ "GenMsgTimeoutTime" BO_ 2654339139 2500;
BA_ "GenMsgILSupport" BO_ 2654339139 1;
BA_ "GenMsgStartDelayTime" BO_ 2654339139 500;
BA_ "GenMsgCycleTime" BO_ 2654339139 1000;
BA_ "Period [ms]" BO_ 2654339073 1000;
BA_ "Type" BO_ 2654339073 1;
BA_ "GenMsgSendType" BO_ 2654339073 0;
BA_ "GenMsgTimeoutTime" BO_ 2654339073 2500;
BA_ "GenMsgILSupport" BO_ 2654339073 1;
BA_ "GenMsgStartDelayTime" BO_ 2654339073 100;
BA_ "GenMsgCycleTime" BO_ 2654339073 1000;
BA_ "Period [ms]" BO_ 2654339075 1000;
BA_ "Type" BO_ 2654339075 1;
BA_ "GenMsgSendType" BO_ 2654339075 0;
BA_ "GenMsgTimeoutTime" BO_ 2654339075 2500;
BA_ "GenMsgILSupport" BO_ 2654339075 1;
BA_ "GenMsgStartDelayTime" BO_ 2654339075 250;
BA_ "GenMsgCycleTime" BO_ 2654339075 1000;
BA_ "Period [ms]" BO_ 2654339137 1000;
BA_ "Type" BO_ 2654339137 1;
BA_ "GenMsgSendType" BO_ 2654339137 0;
BA_ "GenMsgTimeoutTime" BO_ 2654339137 2500;
BA_ "GenMsgILSupport" BO_ 2654339137 1;
BA_ "GenMsgStartDelayTime" BO_ 2654339137 500;
BA_ "GenMsgCycleTime" BO_ 2654339137 1000;
BA_ "Period [ms]" BO_ 2654339094 1000;
BA_ "Type" BO_ 2654339094 1;
BA_ "GenMsgSendType" BO_ 2654339094 0;
BA_ "GenMsgTimeoutTime" BO_ 2654339094 2500;
BA_ "GenMsgILSupport" BO_ 2654339094 1;
BA_ "GenMsgStartDelayTime" BO_ 2654339094 500;
BA_ "GenMsgCycleTime" BO_ 2654339094 1000;
BA_ "Period [ms]" BO_ 2654339083 1000;
BA_ "Type" BO_ 2654339083 1;
BA_ "GenMsgSendType" BO_ 2654339083 0;
BA_ "GenMsgTimeoutTime" BO_ 2654339083 2500;
BA_ "GenMsgILSupport" BO_ 2654339083 1;
BA_ "GenMsgStartDelayTime" BO_ 2654339083 250;
BA_ "GenMsgCycleTime" BO_ 2654339083 1000;
BA_ "Period [ms]" BO_ 508 20;
BA_ "Type" BO_ 508 1;
BA_ "GenMsgSendType" BO_ 508 0;
BA_ "GenMsgTimeoutTime" BO_ 508 2500;
BA_ "GenMsgILSupport" BO_ 508 1;
BA_ "GenMsgCycleTime" BO_ 508 20;
BA_ "Period [ms]" BO_ 1852 1000;
BA_ "Type" BO_ 1852 3;
BA_ "GenMsgSendType" BO_ 1852 0;
BA_ "GenMsgTimeoutTime" BO_ 1852 2500;
BA_ "GenMsgNrOfRepetition" BO_ 1852 2;
BA_ "GenMsgILSupport" BO_ 1852 1;
BA_ "GenMsgStartDelayTime" BO_ 1852 830;
BA_ "GenMsgCycleTimeFast" BO_ 1852 100;
BA_ "GenMsgCycleTime" BO_ 1852 1000;
BA_ "GenMsgDelayTime" BO_ 1852 20;
BA_ "Period [ms]" BO_ 242 10;
BA_ "Type" BO_ 242 1;
BA_ "GenMsgSendType" BO_ 242 0;
BA_ "GenMsgTimeoutTime" BO_ 242 2500;
BA_ "GenMsgILSupport" BO_ 242 1;
BA_ "GenMsgCycleTime" BO_ 242 10;
BA_ "Period [ms]" BO_ 1454 1000;
BA_ "Type" BO_ 1454 3;
BA_ "GenMsgSendType" BO_ 1454 0;
BA_ "GenMsgILSupport" BO_ 1454 1;
BA_ "GenMsgStartDelayTime" BO_ 1454 906;
BA_ "GenMsgCycleTime" BO_ 1454 1000;
BA_ "GenMsgDelayTime" BO_ 1454 20;
BA_ "Period [ms]" BO_ 1504 250;
BA_ "Type" BO_ 1504 10;
BA_ "GenMsgSendType" BO_ 1504 0;
BA_ "GenMsgILSupport" BO_ 1504 1;
BA_ "GenMsgStartDelayTime" BO_ 1504 125;
BA_ "GenMsgCycleTimeFast" BO_ 1504 20;
BA_ "GenMsgCycleTime" BO_ 1504 250;
BA_ "GenMsgDelayTime" BO_ 1504 10;
BA_ "Period [ms]" BO_ 1196 2000;
BA_ "Type" BO_ 1196 3;
BA_ "GenMsgSendType" BO_ 1196 0;
BA_ "GenMsgNrOfRepetition" BO_ 1196 2;
BA_ "GenMsgILSupport" BO_ 1196 1;
BA_ "GenMsgStartDelayTime" BO_ 1196 1000;
BA_ "GenMsgCycleTimeFast" BO_ 1196 10;
BA_ "GenMsgCycleTime" BO_ 1196 2000;
BA_ "GenMsgDelayTime" BO_ 1196 10;
BA_ "Type" BO_ 1992 11;
BA_ "GenMsgTimeoutTime" BO_ 1992 2500;
BA_ "GenMsgILSupport" BO_ 1992 1;
BA_ "Period [ms]" BO_ 1850 1000;
BA_ "Type" BO_ 1850 1;
BA_ "GenMsgSendType" BO_ 1850 0;
BA_ "GenMsgILSupport" BO_ 1850 1;
BA_ "GenMsgStartDelayTime" BO_ 1850 750;
BA_ "GenMsgCycleTime" BO_ 1850 1000;
BA_ "Period [ms]" BO_ 240 10;
BA_ "Type" BO_ 240 1;
BA_ "GenMsgSendType" BO_ 240 0;
BA_ "GenMsgILSupport" BO_ 240 1;
BA_ "GenMsgCycleTime" BO_ 240 10;
BA_ "Period [ms]" BO_ 503 20;
BA_ "Type" BO_ 503 1;
BA_ "GenMsgSendType" BO_ 503 0;
BA_ "GenMsgILSupport" BO_ 503 1;
BA_ "GenMsgStartDelayTime" BO_ 503 10;
BA_ "GenMsgCycleTime" BO_ 503 20;
BA_ "Period [ms]" BO_ 236 10;
BA_ "Type" BO_ 236 1;
BA_ "GenMsgSendType" BO_ 236 0;
BA_ "GenMsgNrOfRepetition" BO_ 236 3;
BA_ "GenMsgILSupport" BO_ 236 1;
BA_ "GenMsgCycleTimeFast" BO_ 236 10;
BA_ "GenMsgCycleTime" BO_ 236 10;
BA_ "GenMsgDelayTime" BO_ 236 10;
BA_ "Period [ms]" BO_ 260 10;
BA_ "Type" BO_ 260 1;
BA_ "GenMsgSendType" BO_ 260 0;
BA_ "GenMsgILSupport" BO_ 260 1;
BA_ "GenMsgStartDelayTime" BO_ 260 5;
BA_ "GenMsgCycleTime" BO_ 260 10;
BA_ "Period [ms]" BO_ 1448 1000;
BA_ "Type" BO_ 1448 3;
BA_ "GenMsgSendType" BO_ 1448 0;
BA_ "GenMsgILSupport" BO_ 1448 1;
BA_ "GenMsgStartDelayTime" BO_ 1448 750;
BA_ "GenMsgCycleTime" BO_ 1448 1000;
BA_ "GenMsgDelayTime" BO_ 1448 20;
BA_ "Period [ms]" BO_ 234 10;
BA_ "Type" BO_ 234 1;
BA_ "GenMsgSendType" BO_ 234 0;
BA_ "GenMsgILSupport" BO_ 234 1;
BA_ "GenMsgCycleTime" BO_ 234 10;
BA_ "GenMsgDelayTime" BO_ 234 20;
BA_ "Type" BO_ 253 8;
BA_ "GenMsgTimeoutTime" BO_ 253 2500;
BA_ "GenMsgILSupport" BO_ 253 1;
BA_ "GenMsgDelayTime" BO_ 253 10;
BA_ "Type" BO_ 243 12;
BA_ "GenMsgILSupport" BO_ 243 1;
BA_ "GenMsgDelayTime" BO_ 243 20;
BA_ "Period [ms]" BO_ 1046 100;
BA_ "Type" BO_ 1046 1;
BA_ "GenMsgSendType" BO_ 1046 0;
BA_ "GenMsgILSupport" BO_ 1046 1;
BA_ "GenMsgStartDelayTime" BO_ 1046 40;
BA_ "GenMsgCycleTime" BO_ 1046 100;
BA_ "Period [ms]" BO_ 2654208000 200;
BA_ "Type" BO_ 2654208000 3;
BA_ "NmMessage" BO_ 2654208000 1;
BA_ "GenMsgSendType" BO_ 2654208000 0;
BA_ "GenMsgTimeoutTime" BO_ 2654208000 2500;
BA_ "GenMsgCycleTime" BO_ 2654208000 200;
BA_ "GenMsgDelayTime" BO_ 2654208000 10;
BA_ "Type" BO_ 2654208006 8;
BA_ "NmMessage" BO_ 2654208006 1;
BA_ "GenMsgDelayTime" BO_ 2654208006 10;
BA_ "Type" BO_ 2654208003 8;
BA_ "NmMessage" BO_ 2654208003 1;
BA_ "GenMsgTimeoutTime" BO_ 2654208003 2500;
BA_ "GenMsgDelayTime" BO_ 2654208003 10;
BA_ "Type" BO_ 2654208065 8;
BA_ "NmMessage" BO_ 2654208065 1;
BA_ "GenMsgDelayTime" BO_ 2654208065 10;
BA_ "Type" BO_ 2654208011 8;
BA_ "NmMessage" BO_ 2654208011 1;
BA_ "GenMsgDelayTime" BO_ 2654208011 10;
BA_ "Period [ms]" BO_ 278 10;
BA_ "Type" BO_ 278 1;
BA_ "GenMsgSendType" BO_ 278 0;
BA_ "GenMsgILSupport" BO_ 278 1;
BA_ "GenMsgStartDelayTime" BO_ 278 10;
BA_ "GenMsgCycleTime" BO_ 278 10;
BA_ "Period [ms]" BO_ 238 10;
BA_ "Type" BO_ 238 1;
BA_ "GenMsgSendType" BO_ 238 0;
BA_ "GenMsgILSupport" BO_ 238 1;
BA_ "GenMsgCycleTime" BO_ 238 10;
BA_ "Event trans." SG_ 346 IMPACTCommand 0;
BA_ "GenSigSendType" SG_ 346 IMPACTCommand 5;
BA_ "Event trans." SG_ 346 IMPACTConfirm 0;
BA_ "GenSigStartValue" SG_ 346 IMPACTConfirm 1;
BA_ "GenSigInactiveValue" SG_ 346 IMPACTConfirm 1;
BA_ "GenSigSendType" SG_ 346 IMPACTConfirm 5;
BA_ "Event trans." SG_ 346 IMPACTFailSts 0;
BA_ "GenSigSendType" SG_ 346 IMPACTFailSts 5;
BA_ "GenSigStartValue" SG_ 1054 IBS_I_BATT 65535;
BA_ "GenSigStartValue" SG_ 1054 IBS_I_RANGE 3;
BA_ "GenSigStartValue" SG_ 1054 IBS_T_BATT 255;
BA_ "GenSigStartValue" SG_ 1054 IBS_V_BATT 16383;
BA_ "GenSigStartValue" SG_ 1056 IBS_SOC 255;
BA_ "GenSigStartValue" SG_ 1056 IBS_SOC_Accuracy 3;
BA_ "GenSigStartValue" SG_ 1056 IBS_SOF_Q 255;
BA_ "GenSigStartValue" SG_ 1056 IBS_SOF_Q_Accuracy 3;
BA_ "GenSigStartValue" SG_ 1056 IBS_SOF_V 255;
BA_ "GenSigStartValue" SG_ 1056 IBS_SOF_V_Accuracy 3;
BA_ "GenSigStartValue" SG_ 1056 IBS_SOH_Q 255;
BA_ "GenSigStartValue" SG_ 1056 IBS_SOH_Q_Accuracy 3;
BA_ "GenSigStartValue" SG_ 500 EngTrqDrvReqMod 8191;
BA_ "GenSigStartValue" SG_ 500 EngTrqEnblRq_DAS 1;
BA_ "GenSigStartValue" SG_ 500 ESS_ENG_ST 15;
BA_ "GenSigStartValue" SG_ 1047 AtmosphericPressure 255;
BA_ "GenSigStartValue" SG_ 1047 EngMaxRPM 255;
BA_ "GenSigStartValue" SG_ 1047 IntakeAirTemperature 65;
BA_ "Accuracy" SG_ 1042 CARB_PERM "-";
BA_ "Accuracy" SG_ 1042 CarbWarmUp "-";
BA_ "Accuracy" SG_ 1042 CldStrtDenominator "-";
BA_ "Accuracy" SG_ 1042 EngineOFFTime "-";
BA_ "GenSigStartValue" SG_ 1042 EngineOFFTime 1023;
BA_ "Accuracy" SG_ 1042 GenDenominator "-";
BA_ "Accuracy" SG_ 1042 IgnCntrTrue "-";
BA_ "Accuracy" SG_ 1042 Inp_CSD_Fail "-";
BA_ "Accuracy" SG_ 1042 Inp_ICC_Fail "-";
BA_ "Accuracy" SG_ 1042 InputsGDFail "-";
BA_ "Event trans." SG_ 1848 KeyProgramSts 0;
BA_ "GenSigSendType" SG_ 1848 KeyProgramSts 3;
BA_ "Event trans." SG_ 1848 MsgFOBLeftVeh 0;
BA_ "GenSigSendType" SG_ 1848 MsgFOBLeftVeh 3;
BA_ "Event trans." SG_ 1848 MsgFOBNotFnd 0;
BA_ "GenSigSendType" SG_ 1848 MsgFOBNotFnd 3;
BA_ "Event trans." SG_ 1848 MsgNotInPark 0;
BA_ "GenSigSendType" SG_ 1848 MsgNotInPark 3;
BA_ "Event trans." SG_ 1848 MsgPutInPark 0;
BA_ "GenSigSendType" SG_ 1848 MsgPutInPark 3;
BA_ "Event trans." SG_ 1848 MsgServPEKG 0;
BA_ "GenSigSendType" SG_ 1848 MsgServPEKG 3;
BA_ "GenSigStartValue" SG_ 762 CRC_CSWC_1 255;
BA_ "Accuracy" SG_ 2654339129 CurrentFailSts_DASM "-";
BA_ "Accuracy" SG_ 2654339129 DES_DASM "-";
BA_ "Accuracy" SG_ 2654339129 EOL_DASM "-";
BA_ "Accuracy" SG_ 2654339129 GenericFailSts_DASM "-";
BA_ "Accuracy" SG_ 2654339139 CurrentFailSts_DTCM "-";
BA_ "Accuracy" SG_ 2654339139 DES_DTCM "-";
BA_ "Accuracy" SG_ 2654339139 EOL_DTCM "-";
BA_ "Accuracy" SG_ 2654339139 GenericFailSts_DTCM "-";
BA_ "Accuracy" SG_ 2654339073 CurrentFailSts_ECM "-";
BA_ "Accuracy" SG_ 2654339073 DES_ECM "-";
BA_ "Accuracy" SG_ 2654339073 EOL_ECM "-";
BA_ "Accuracy" SG_ 2654339073 GenericFailSts_ECM "-";
BA_ "Accuracy" SG_ 2654339075 CurrentFailSts_IPC "-";
BA_ "Accuracy" SG_ 2654339075 DES_IPC "-";
BA_ "Accuracy" SG_ 2654339075 EOL_IPC "-";
BA_ "Accuracy" SG_ 2654339075 GenericFailSts_IPC "-";
BA_ "Accuracy" SG_ 2654339137 CurrentFailSts_RFHM "-";
BA_ "Accuracy" SG_ 2654339137 DES_RFHM "-";
BA_ "Accuracy" SG_ 2654339137 EOL_RFHM "-";
BA_ "Accuracy" SG_ 2654339137 GenericFailSts_RFHM "-";
BA_ "Accuracy" SG_ 2654339094 CurrentFailSts_Shifter "-";
BA_ "Accuracy" SG_ 2654339094 DES_Shifter "-";
BA_ "Accuracy" SG_ 2654339094 EOL_Shifter "-";
BA_ "Accuracy" SG_ 2654339094 GenericFailSts_Shifter "-";
BA_ "Accuracy" SG_ 2654339083 CurrentFailSts_Transmission "-";
BA_ "Accuracy" SG_ 2654339083 DES_Transmission "-";
BA_ "Accuracy" SG_ 2654339083 EOL_Transmission "-";
BA_ "Accuracy" SG_ 2654339083 GenericFailSts_Transmission "-";
BA_ "Accuracy" SG_ 508 ADC_STS "-";
BA_ "Accuracy" SG_ 508 CDCM_WarningLamp "-";
BA_ "Accuracy" SG_ 508 FrontAeroSts "-";
BA_ "Accuracy" SG_ 508 RdAspInd "-";
BA_ "Accuracy" SG_ 508 Rear_Diff_Control_Sts "-";
BA_ "Accuracy" SG_ 508 Rear_Diff_WarningLamp "-";
BA_ "Event trans." SG_ 1852 ACC_RadarBlinded 0;
BA_ "GenSigStartValue" SG_ 1852 ACC_RadarBlinded 1;
BA_ "GenSigSendType" SG_ 1852 ACC_RadarBlinded 4;
BA_ "Event trans." SG_ 1852 ACC_SetSpeedKPH 0;
BA_ "GenSigSendType" SG_ 1852 ACC_SetSpeedKPH 4;
BA_ "Event trans." SG_ 1852 ACC_SetSpeedMPH 0;
BA_ "GenSigSendType" SG_ 1852 ACC_SetSpeedMPH 4;
BA_ "Event trans." SG_ 1852 ACCFailSts 0;
BA_ "GenSigSendType" SG_ 1852 ACCFailSts 4;
BA_ "Event trans." SG_ 1852 ACCSystemSts 0;
BA_ "GenSigSendType" SG_ 1852 ACCSystemSts 4;
BA_ "Event trans." SG_ 1852 CameraBlinded 0;
BA_ "GenSigStartValue" SG_ 1852 CameraBlinded 1;
BA_ "GenSigSendType" SG_ 1852 CameraBlinded 4;
BA_ "Event trans." SG_ 1852 CameraFailure 0;
BA_ "GenSigStartValue" SG_ 1852 CameraFailure 1;
BA_ "GenSigSendType" SG_ 1852 CameraFailure 4;
BA_ "Accuracy" SG_ 1852 CHIME_TYPSts "-";
BA_ "Event trans." SG_ 1852 DASMFailSts 0;
BA_ "GenSigStartValue" SG_ 1852 DASMFailSts 1;
BA_ "GenSigSendType" SG_ 1852 DASMFailSts 4;
BA_ "Event trans." SG_ 1852 DASMTemporaryFailSts 0;
BA_ "GenSigStartValue" SG_ 1852 DASMTemporaryFailSts 1;
BA_ "GenSigSendType" SG_ 1852 DASMTemporaryFailSts 4;
BA_ "Accuracy" SG_ 1852 FCWSts "-";
BA_ "GenSigStartValue" SG_ 1852 FCWSts 2;
BA_ "Accuracy" SG_ 1852 FCWSystemSts "-";
BA_ "Event trans." SG_ 1852 FCWSystemSts 0;
BA_ "GenSigStartValue" SG_ 1852 FCWSystemSts 3;
BA_ "GenSigSendType" SG_ 1852 FCWSystemSts 4;
BA_ "Event trans." SG_ 1852 HMICode_ACC 0;
BA_ "GenSigSendType" SG_ 1852 HMICode_ACC 4;
BA_ "Event trans." SG_ 1852 HMICode_FCW 0;
BA_ "GenSigSendType" SG_ 1852 HMICode_FCW 4;
BA_ "Event trans." SG_ 1852 HMIDisplay_ACC 0;
BA_ "GenSigSendType" SG_ 1852 HMIDisplay_ACC 4;
BA_ "Event trans." SG_ 1852 NCCFailSts 0;
BA_ "GenSigSendType" SG_ 1852 NCCFailSts 4;
BA_ "Event trans." SG_ 1852 RadarBlinded 0;
BA_ "GenSigStartValue" SG_ 1852 RadarBlinded 1;
BA_ "GenSigSendType" SG_ 1852 RadarBlinded 4;
BA_ "Accuracy" SG_ 1454 ChkFuelCap "-";
BA_ "Event trans." SG_ 1454 ChkFuelCap 0;
BA_ "GenSigSendType" SG_ 1454 ChkFuelCap 3;
BA_ "Accuracy" SG_ 1454 ColdStartLampIndication "-";
BA_ "Event trans." SG_ 1454 ColdStartLampIndication 0;
BA_ "GenSigStartValue" SG_ 1454 ColdStartLampIndication 3;
BA_ "GenSigSendType" SG_ 1454 ColdStartLampIndication 3;
BA_ "Accuracy" SG_ 1454 CompressorSts "-";
BA_ "Event trans." SG_ 1454 CompressorSts 0;
BA_ "GenSigStartValue" SG_ 1454 CompressorSts 2;
BA_ "GenSigSendType" SG_ 1454 CompressorSts 3;
BA_ "Accuracy" SG_ 1454 DPFSts "-";
BA_ "Event trans." SG_ 1454 DPFSts 0;
BA_ "GenSigSendType" SG_ 1454 DPFSts 3;
BA_ "Accuracy" SG_ 1454 EMSFailSts "-";
BA_ "Event trans." SG_ 1454 EMSFailSts 0;
BA_ "GenSigStartValue" SG_ 1454 EMSFailSts 2;
BA_ "GenSigSendType" SG_ 1454 EMSFailSts 3;
BA_ "Event trans." SG_ 1454 EngineOperatingMode 0;
BA_ "GenSigSendType" SG_ 1454 EngineOperatingMode 3;
BA_ "Accuracy" SG_ 1454 EngineWaterTempWarningLightSts "-";
BA_ "Event trans." SG_ 1454 EngineWaterTempWarningLightSts 0;
BA_ "GenSigSendType" SG_ 1454 EngineWaterTempWarningLightSts 3;
BA_ "Accuracy" SG_ 1454 ETCFailSts "-";
BA_ "Event trans." SG_ 1454 ETCFailSts 0;
BA_ "GenSigSendType" SG_ 1454 ETCFailSts 3;
BA_ "Event trans." SG_ 1454 ExhaustTemperature 0;
BA_ "GenSigSendType" SG_ 1454 ExhaustTemperature 3;
BA_ "Accuracy" SG_ 1454 FuelFilterHeaterReq "-";
BA_ "Event trans." SG_ 1454 FuelFilterHeaterReq 0;
BA_ "GenSigSendType" SG_ 1454 FuelFilterHeaterReq 3;
BA_ "Accuracy" SG_ 1454 FuelWaterPresentFailSts "-";
BA_ "Event trans." SG_ 1454 FuelWaterPresentFailSts 0;
BA_ "GenSigSendType" SG_ 1454 FuelWaterPresentFailSts 3;
BA_ "Accuracy" SG_ 1454 FuelWaterPresentSts "-";
BA_ "Event trans." SG_ 1454 FuelWaterPresentSts 0;
BA_ "GenSigSendType" SG_ 1454 FuelWaterPresentSts 3;
BA_ "Accuracy" SG_ 1454 GlowPlugFailSts "-";
BA_ "Event trans." SG_ 1454 GlowPlugFailSts 0;
BA_ "GenSigSendType" SG_ 1454 GlowPlugFailSts 3;
BA_ "Accuracy" SG_ 1454 GlowPlugLampSts "-";
BA_ "Event trans." SG_ 1454 GlowPlugLampSts 0;
BA_ "GenSigSendType" SG_ 1454 GlowPlugLampSts 3;
BA_ "Accuracy" SG_ 1454 OilLifeSts "-";
BA_ "Event trans." SG_ 1454 OilLifeSts 0;
BA_ "GenSigSendType" SG_ 1454 OilLifeSts 3;
BA_ "Accuracy" SG_ 1454 OilPressureFailSts "-";
BA_ "Event trans." SG_ 1454 OilPressureFailSts 0;
BA_ "GenSigSendType" SG_ 1454 OilPressureFailSts 3;
BA_ "Accuracy" SG_ 1454 OilPressureSts "-";
BA_ "Event trans." SG_ 1454 OilPressureSts 0;
BA_ "GenSigStartValue" SG_ 1454 OilPressureSts 1;
BA_ "GenSigSendType" SG_ 1454 OilPressureSts 3;
BA_ "GenSigStartValue" SG_ 1504 EPBAutoAppSts 1;
BA_ "Event trans." SG_ 1504 FastTransmission_SE 0;
BA_ "GenSigSendType" SG_ 1504 FastTransmission_SE 5;
BA_ "Accuracy" SG_ 1196 InflationState_LHF_Tyre "-";
BA_ "Event trans." SG_ 1196 InflationState_LHF_Tyre 0;
BA_ "GenSigSendType" SG_ 1196 InflationState_LHF_Tyre 4;
BA_ "Accuracy" SG_ 1196 InflationState_LHR_Tyre "-";
BA_ "Event trans." SG_ 1196 InflationState_LHR_Tyre 0;
BA_ "GenSigSendType" SG_ 1196 InflationState_LHR_Tyre 4;
BA_ "Accuracy" SG_ 1196 InflationState_RHF_Tyre "-";
BA_ "Event trans." SG_ 1196 InflationState_RHF_Tyre 0;
BA_ "GenSigSendType" SG_ 1196 InflationState_RHF_Tyre 4;
BA_ "Accuracy" SG_ 1196 InflationState_RHR_Tyre "-";
BA_ "Event trans." SG_ 1196 InflationState_RHR_Tyre 0;
BA_ "GenSigSendType" SG_ 1196 InflationState_RHR_Tyre 4;
BA_ "Accuracy" SG_ 1196 PressureValue_LHF_Tyre "+/- 0,1 bar";
BA_ "Accuracy" SG_ 1196 PressureValue_LHR_Tyre "+/- 0,1 bar";
BA_ "Accuracy" SG_ 1196 PressureValue_RHF_Tyre "+/- 0,1 bar";
BA_ "Accuracy" SG_ 1196 PressureValue_RHR_Tyre "+/- 0,1 bar";
BA_ "Accuracy" SG_ 1196 TPMActivitySts "-";
BA_ "Accuracy" SG_ 1196 TyrePressureSysProgrammedSts "-";
BA_ "Event trans." SG_ 1196 TyrePressureSysProgrammedSts 0;
BA_ "GenSigSendType" SG_ 1196 TyrePressureSysProgrammedSts 4;
BA_ "Accuracy" SG_ 1196 TyrePressureSystemFailSts "-";
BA_ "Event trans." SG_ 1196 TyrePressureSystemFailSts 0;
BA_ "GenSigSendType" SG_ 1196 TyrePressureSystemFailSts 4;
BA_ "Accuracy" SG_ 1850 Day1 "-";
BA_ "Accuracy" SG_ 1850 Day2 "-";
BA_ "Accuracy" SG_ 1850 Hour1 "-";
BA_ "Accuracy" SG_ 1850 Hour2 "-";
BA_ "Accuracy" SG_ 1850 Minute1 "-";
BA_ "Accuracy" SG_ 1850 Minute2 "-";
BA_ "Accuracy" SG_ 1850 Month1 "-";
BA_ "Accuracy" SG_ 1850 Month2 "-";
BA_ "Accuracy" SG_ 1850 Year1 "-";
BA_ "Accuracy" SG_ 1850 Year2 "-";
BA_ "Accuracy" SG_ 1850 Year3 "-";
BA_ "Accuracy" SG_ 1850 Year4 "-";
BA_ "GenSigStartValue" SG_ 240 EngTrq_Rq_TCM 2047;
BA_ "GenSigStartValue" SG_ 240 EngTrq_Rq_TCM_Slow 2047;
BA_ "GenSigStartValue" SG_ 240 MaxTrqDes 2047;
BA_ "GenSigStartValue" SG_ 503 FANRequestNCA 3;
BA_ "GenSigStartValue" SG_ 503 OUTPUT_SPEED 65535;
BA_ "GenSigStartValue" SG_ 503 TRNS_StpSt_FLT 1;
BA_ "GenSigStartValue" SG_ 503 TurbineSpeed 65535;
BA_ "GenSigStartValue" SG_ 260 EngTrgtSpdCtrl 4095;
BA_ "Event trans." SG_ 1448 BuzzerReqSts_T2 0;
BA_ "GenSigSendType" SG_ 1448 BuzzerReqSts_T2 3;
BA_ "Event trans." SG_ 1448 CrankEnable 0;
BA_ "GenSigSendType" SG_ 1448 CrankEnable 3;
BA_ "Event trans." SG_ 1448 DriveModeSts 0;
BA_ "GenSigSendType" SG_ 1448 DriveModeSts 3;
BA_ "Event trans." SG_ 1448 GearEngaged 0;
BA_ "GenSigSendType" SG_ 1448 GearEngaged 3;
BA_ "Event trans." SG_ 1448 GearIndicationSts 0;
BA_ "GenSigSendType" SG_ 1448 GearIndicationSts 3;
BA_ "Event trans." SG_ 1448 LeverPosition 0;
BA_ "GenSigSendType" SG_ 1448 LeverPosition 3;
BA_ "Event trans." SG_ 1448 LimpHomeSts 0;
BA_ "GenSigSendType" SG_ 1448 LimpHomeSts 3;
BA_ "Event trans." SG_ 1448 MIReq 0;
BA_ "GenSigSendType" SG_ 1448 MIReq 3;
BA_ "Event trans." SG_ 1448 OilTemperatureSts 0;
BA_ "GenSigSendType" SG_ 1448 OilTemperatureSts 3;
BA_ "Event trans." SG_ 1448 ParkingFailSts 0;
BA_ "GenSigSendType" SG_ 1448 ParkingFailSts 3;
BA_ "Event trans." SG_ 1448 ParkingSts 0;
BA_ "GenSigSendType" SG_ 1448 ParkingSts 3;
BA_ "Event trans." SG_ 1448 ShiftInProgress 0;
BA_ "GenSigSendType" SG_ 1448 ShiftInProgress 3;
BA_ "Event trans." SG_ 1448 ShiftLeverPosition 0;
BA_ "GenSigSendType" SG_ 1448 ShiftLeverPosition 3;
BA_ "Event trans." SG_ 1448 ShiftModeSts 0;
BA_ "GenSigSendType" SG_ 1448 ShiftModeSts 3;
BA_ "Event trans." SG_ 1448 TargetGear 0;
BA_ "GenSigStartValue" SG_ 1448 TargetGear 15;
BA_ "GenSigSendType" SG_ 1448 TargetGear 3;
BA_ "Event trans." SG_ 1448 TemporaryManualSts 0;
BA_ "GenSigSendType" SG_ 1448 TemporaryManualSts 3;
BA_ "Event trans." SG_ 1448 TransmissionFailSts 0;
BA_ "GenSigSendType" SG_ 1448 TransmissionFailSts 3;
BA_ "Event trans." SG_ 1448 TransmissionWarnings 0;
BA_ "GenSigSendType" SG_ 1448 TransmissionWarnings 3;
BA_ "Event trans." SG_ 1448 TxDisengaged 0;
BA_ "GenSigSendType" SG_ 1448 TxDisengaged 3;
BA_ "Event trans." SG_ 1448 UpDownShiftSel 0;
BA_ "GenSigSendType" SG_ 1448 UpDownShiftSel 3;
BA_ "Accuracy" SG_ 253 ControlEncoding_TRM_Rsp "-";
BA_ "Event trans." SG_ 253 ControlEncoding_TRM_Rsp 0;
BA_ "GenSigSendType" SG_ 253 ControlEncoding_TRM_Rsp 3;
BA_ "GenSigStartValue" SG_ 253 TxpFound 1;
BA_ "Accuracy" SG_ 243 FrameNumber "-";
BA_ "Event trans." SG_ 243 FrameNumber 0;
BA_ "GenSigSendType" SG_ 243 FrameNumber 1;
BA_ "Accuracy" SG_ 243 TotalFrameNumber "-";
BA_ "GenSigStartValue" SG_ 1046 VIN_MSG 3;
BA_ "Accuracy" SG_ 2654208000 MainWakeSts_BCM "-";
BA_ "Accuracy" SG_ 2654208000 Node0 "-";
BA_ "Accuracy" SG_ 2654208000 Node1 "-";
BA_ "Accuracy" SG_ 2654208000 Node10 "-";
BA_ "Accuracy" SG_ 2654208000 Node11 "-";
BA_ "Accuracy" SG_ 2654208000 Node12 "-";
BA_ "Accuracy" SG_ 2654208000 Node13 "-";
BA_ "Accuracy" SG_ 2654208000 Node14 "-";
BA_ "Accuracy" SG_ 2654208000 Node15 "-";
BA_ "Accuracy" SG_ 2654208000 Node16 "-";
BA_ "Accuracy" SG_ 2654208000 Node17 "-";
BA_ "Accuracy" SG_ 2654208000 Node18 "-";
BA_ "Accuracy" SG_ 2654208000 Node19 "-";
BA_ "Accuracy" SG_ 2654208000 Node2 "-";
BA_ "Accuracy" SG_ 2654208000 Node20 "-";
BA_ "Accuracy" SG_ 2654208000 Node21 "-";
BA_ "Accuracy" SG_ 2654208000 Node22 "-";
BA_ "Accuracy" SG_ 2654208000 Node23 "-";
BA_ "Accuracy" SG_ 2654208000 Node24 "-";
BA_ "Accuracy" SG_ 2654208000 Node25 "-";
BA_ "Accuracy" SG_ 2654208000 Node26 "-";
BA_ "Accuracy" SG_ 2654208000 Node27 "-";
BA_ "Accuracy" SG_ 2654208000 Node28 "-";
BA_ "Accuracy" SG_ 2654208000 Node29 "-";
BA_ "Accuracy" SG_ 2654208000 Node3 "-";
BA_ "Accuracy" SG_ 2654208000 Node30 "-";
BA_ "Accuracy" SG_ 2654208000 Node31 "-";
BA_ "Accuracy" SG_ 2654208000 Node4 "-";
BA_ "Accuracy" SG_ 2654208000 Node5 "-";
BA_ "Accuracy" SG_ 2654208000 Node6 "-";
BA_ "Accuracy" SG_ 2654208000 Node7 "-";
BA_ "Accuracy" SG_ 2654208000 Node8 "-";
BA_ "Accuracy" SG_ 2654208000 Node9 "-";
BA_ "Accuracy" SG_ 2654208000 WakeCntr_BCM "-";
BA_ "Accuracy" SG_ 2654208000 WakeRsn_BCM "-";
BA_ "GenSigStartValue" SG_ 2654208006 WakeUpNodeAddress 1;
BA_ "GenSigStartValue" SG_ 2654208003 WakeUpNodeAddress 6;
BA_ "GenSigStartValue" SG_ 2654208065 WakeUpNodeAddress 21;
BA_ "GenSigStartValue" SG_ 2654208011 WakeUpNodeAddress 8;
BA_ "Accuracy" SG_ 278 CRC_WI "-";
BA_ "Accuracy" SG_ 278 LHF_FastPulseCounter "-";
BA_ "Accuracy" SG_ 278 LHF_Spin "-";
BA_ "Accuracy" SG_ 278 LHF_WheelSensorFailSts "-";
BA_ "Accuracy" SG_ 278 LHR_FastPulseCounter "-";
BA_ "Accuracy" SG_ 278 LHR_Spin "-";
BA_ "Accuracy" SG_ 278 LHR_WheelSensorFailSts "-";
BA_ "Accuracy" SG_ 278 MessageCounter_WI "-";
BA_ "Accuracy" SG_ 278 RHF_FastPulseCounter "-";
BA_ "Accuracy" SG_ 278 RHF_Spin "-";
BA_ "Accuracy" SG_ 278 RHF_WheelSensorFailSts "-";
BA_ "Accuracy" SG_ 278 RHR_FastPulseCounter "-";
BA_ "Accuracy" SG_ 278 RHR_Spin "-";
BA_ "Accuracy" SG_ 278 RHR_WheelSensorFailSts "-";
BA_ "Accuracy" SG_ 238 LHFWheelSpeed "-";
BA_ "Accuracy" SG_ 238 LHRWheelSpeed "-";
BA_ "Accuracy" SG_ 238 RHFWheelSpeed "-";
BA_ "Accuracy" SG_ 238 RHRWheelSpeed "-";
VAL_ 346 IMPACT_A 0 "Do_Not_Actuate" 1 "Actuate";
VAL_ 346 IMPACT_B 0 "Do_Not_Actuate" 1 "Actuate";
VAL_ 346 IMPACT_C 0 "Do_Not_Actuate" 1 "Actuate";
VAL_ 346 IMPACT_D 0 "Do_Not_Actuate" 1 "Actuate";
VAL_ 346 IMPACT_E 0 "Do_Not_Actuate" 1 "Actuate";
VAL_ 346 IMPACT_F 0 "Do_Not_Actuate" 1 "Actuate";
VAL_ 346 IMPACT_G 0 "Do_Not_Actuate" 1 "Actuate";
VAL_ 346 IMPACT_H 0 "Do_Not_Actuate" 1 "Actuate";
VAL_ 346 IMPACT_I 0 "Do_Not_Actuate" 1 "Actuate";
VAL_ 346 IMPACT_K 0 "Do_Not_Actuate" 1 "Actuate";
VAL_ 346 IMPACT_L 0 "Do_Not_Actuate" 1 "Actuate";
VAL_ 346 IMPACT_M 0 "Do_Not_Actuate" 1 "Actuate";
VAL_ 346 IMPACT_O 0 "Do_Not_Actuate" 1 "Actuate";
VAL_ 346 IMPACTCommand 0 "Do_Not_Actuate" 1 "Actuate";
VAL_ 346 IMPACTConfirm 0 "Actuate" 1 "Do_Not_Actuate";
VAL_ 346 IMPACTFailSts 0 "Fail_Not_Present" 1 "Fail_Present";
VAL_ 1054 IBS_Current_Status 0 "No_Error" 1 "Open_Circuit" 2 "HW_Defect" 3 "Saturated";
VAL_ 1054 IBS_Error_Calib 0 "No_Error" 1 "Error";
VAL_ 1054 IBS_Error_Ident 0 "No_Error" 1 "Error";
VAL_ 1054 IBS_Error_NVM 0 "No_Error" 1 "Error";
VAL_ 1054 IBS_I_BATT 65535 "SNA";
VAL_ 1054 IBS_I_RANGE 0 "Range_I1" 1 "Range_I200" 2 "Range_I1500" 3 "SNA";
VAL_ 1054 IBS_T_BATT 255 "SNA";
VAL_ 1054 IBS_Temp_Status 0 "No_Error" 1 "Open_Circuit" 2 "HW_Defect" 3 "Saturated";
VAL_ 1054 IBS_V_BATT 16383 "SNA";
VAL_ 1054 IBS_Voltage_Status 0 "No_Error" 1 "Open_Circuit" 2 "HW_Defect" 3 "Saturated";
VAL_ 1056 IBS_SOC 255 "SNA";
VAL_ 1056 IBS_SOC_Accuracy 0 "ACCURACY_0" 1 "ACCURACY_1" 2 "ACCURACY_2" 3 "SNA";
VAL_ 1056 IBS_SOF_Q 255 "SNA";
VAL_ 1056 IBS_SOF_Q_Accuracy 0 "ACCURACY_0" 1 "ACCURACY_1" 2 "ACCURACY_2" 3 "SNA";
VAL_ 1056 IBS_SOF_V 255 "SNA";
VAL_ 1056 IBS_SOF_V_Accuracy 0 "ACCURACY_0" 1 "ACCURACY_1" 2 "ACCURACY_2" 3 "SNA";
VAL_ 1056 IBS_SOH_Q 255 "SNA";
VAL_ 1056 IBS_SOH_Q_Accuracy 0 "ACCURACY_0" 1 "ACCURACY_1" 2 "ACCURACY_2" 3 "SNA";
VAL_ 256 ECM_LHOM 0 "Not_In_Limp_Home" 1 "In_Limp_Home";
VAL_ 256 EngineNuenRq 0 "Not_Request" 1 "Request";
VAL_ 256 EngineSailingRq 0 "Not_Request" 1 "Request";
VAL_ 256 EngTrq_Enbl_Rq_TCM 0 "Not_Active" 1 "Active";
VAL_ 256 EngTrqSel_D_TTC 2047 "SNA";
VAL_ 256 EngTrqStatic_SEM 2047 "SNA";
VAL_ 256 EngTrqTgt_SEM 2047 "SNA";
VAL_ 256 TRANS_CLU_SLIP_MODE 0 "NORMAL" 1 "MDS_RQ" 2 "IDFSO_RQ" 3 "AC_EN_DIS_RQ" 4 "IDFSO_ACTIVE" 7 "SNA";
VAL_ 256 TxAC_EMCC_rq 0 "False" 1 "True";
VAL_ 244 CANErr 1 "NoCanMessage" 2 "UnplausibleMessage" 4 "UnplausibleCommand" 8 "NotUsed";
VAL_ 244 CylCutEnabled 0 "Not_Active" 1 "Cut_Off_Enabled";
VAL_ 244 EngineAtLimiter 0 "Not_Active" 1 "Speed_Limiter_Active";
VAL_ 244 EngineIdleRefSpeed 4095 "SNA";
VAL_ 244 EngineSlaveModeActive 0 "Not_Active" 1 "Slave_Mode_Active";
VAL_ 244 EngTorqueTargetWONCR 2047 "SNA";
VAL_ 244 FutureTorque 2047 "SNA";
VAL_ 244 NmaxControllerActive 0 "Not_Active" 1 "Speed_Control_Active";
VAL_ 244 Psben 0 "Not_Active" 1 "Active";
VAL_ 500 EngineReadyForESS 0 "Not_Active" 1 "Active";
VAL_ 500 EngTrqDrvReqMod 8191 "SNA";
VAL_ 500 EngTrqEnblRq_DAS 0 "FALSE" 1 "TRUE";
VAL_ 500 ESS_ENG_ST 1 "ENS Stopped / ENS_STOPPED" 2 "ENS Request Start / ENS_RQ_ST" 3 "ENS Running / ENS_RUN" 4 "ENS Stop Pending / ENS_STOP_PEND" 5 "ENS Start protection / ENS_ST_PRTCT" 6 "ENS Start inhibit / ENS_ST_INH" 7 "ENS disabled / ENS_DSBL" 8 "ENS_IHB_LATCH" 9 "ENS Starting / ENS_Starting" 15 "SNA";
VAL_ 500 GrMax_Rq_ECM 0 "Passive" 1 "G1" 2 "G2" 3 "G3" 4 "G4" 5 "G5" 6 "G6" 7 "G7" 8 "G8" 9 "G9";
VAL_ 500 MaxInstTorque 2047 "SNA";
VAL_ 500 MinInstTorque 2047 "SNA";
VAL_ 500 RPMOverRev 0 "FALSE" 1 "TRUE";
VAL_ 1047 AtmosphericPressure 255 "SNA";
VAL_ 1047 AtmosphericPressureFailSts 0 "Fail_Not_Present" 1 "Fail_Present";
VAL_ 1047 EngMaxRPM 255 "SNA";
VAL_ 1047 ESS_ActvEBrake 0 "Do_Nothing" 1 "Activate E Brake";
VAL_ 1047 ESS_RqShftPark 0 "Do_Nothing" 1 "Shift_to_Park";
VAL_ 1047 IntakeAirTemperature 255 "SNA";
VAL_ 1047 ThermalManagementActive 0 "Not_active" 1 "Active";
VAL_ 1047 VehicleSetSpeed 255 "SNA";
VAL_ 1042 CARB_PERM 0 "False" 1 "True";
VAL_ 1042 CarbWarmUp 0 "False" 1 "True";
VAL_ 1042 CldStrtDenominator 0 "Not_Active" 1 "Active";
VAL_ 1042 EngineOFFTime 1023 "SNA";
VAL_ 1042 GenDenominator 0 "False" 1 "True";
VAL_ 1042 IgnCntrTrue 0 "False" 1 "True";
VAL_ 1042 Inp_CSD_Fail 0 "Fail_Not_Present" 1 "Fail_Present";
VAL_ 1042 Inp_ICC_Fail 0 "Fail_Not_Present" 1 "Fail_Present";
VAL_ 1042 InputsGDFail 0 "False" 1 "True";
VAL_ 495 CustKeyInIgnSts 0 "CUST_KEY_DEFAULT" 1 "CUST_KEY_NOT_IN_IGNITION" 2 "CUST_KEY_IN_IGNITION" 3 "SNA";
VAL_ 495 DriverEngineOffRequest 0 "Not_Active" 1 "Active";
VAL_ 495 IgnPosSts 0 "Initialization" 1 "IGN_LK" 3 "ACC" 4 "RUN" 5 "START" 7 "SNA";
VAL_ 495 RFFobNum 0 "FOB_DEFAULT" 1 "FOB_1" 2 "FOB_2" 3 "FOB_3" 4 "FOB_4" 5 "FOB_5" 6 "FOB_6" 7 "FOB_7" 8 "FOB_8" 15 "SNA";
VAL_ 495 RFFuncReq 0 "NO_BASIC_REQUEST" 1 "LOCK_REQUEST" 2 "RELOCK_REQUEST" 3 "DRIVER_UNLOCK_REQUEST" 4 "ALL_UNLOCK_REQUEST" 5 "TRUNK_PLG_TOGGLE_REQUEST" 6 "LEFT_SLIDER_TOGGLE_REQUEST" 7 "RIGHT_SLIDER_TOGGLE_REQUEST" 8 "FLIPPER_GLASS_REQUEST" 9 "REMOTE_START_ON" 10 "REMOTE_START_OFF" 11 "GLOBAL_WINDOW_DOWN_REQUEST" 12 "OPEN_CONVERTIBLE_TOP" 13 "CLOSE_CONVERTIBLE_TOP" 14 "PANIC_TOGGLE_REQUEST" 15 "DEAD_LOCK_REQUEST" 16 "GLOBAL_WINDOWS_UP_REQUEST" 31 "SNA";
VAL_ 495 RFReq 0 "REQUESTOR_DEFAULT" 1 "REQUESTOR_RKE" 2 "REQUESTOR_PE" 3 "REQUESTOR_REMOTESTART" 4 "REQUESTOR_UCONNECT" 7 "SNA";
VAL_ 1848 KeyProgramSts 0 "RKE_NORM_STAT" 1 "EN_KEY_PROG" 2 "PROG_ACT" 3 "EX_KEY_PROG" 4 "KEY_PROG" 5 "DMG_KEY" 6 "INV_KEY" 7 "EXCD_KEY" 8 "RKE_BATT_LO" 9 "SRV_SKREEM" 10 "BTN_DLY_ACT" 11 "BTN_DLY_INACT" 12 "KEY_NOT_PROG" 15 "SNA";
VAL_ 1848 MsgFOBLeftVeh 0 "MSG_DEFAULT" 1 "MSG_ACTIVE" 3 "SNA";
VAL_ 1848 MsgFOBNotFnd 0 "MSG_DEFAULT" 1 "MSG_ACTIVE" 3 "SNA";
VAL_ 1848 MsgNotInPark 0 "MSG_DEFAULT" 1 "MSG_ACTIVE" 3 "SNA";
VAL_ 1848 MsgPutInPark 0 "MSG_DEFAULT" 1 "MSG_ACTIVE" 3 "SNA";
VAL_ 1848 MsgServPEKG 0 "MSG_DEFAULT" 1 "MSG_ACTIVE" 3 "SNA";
VAL_ 1848 PowerModeSts_RFHM 0 "Standard Power" 1 "Logistic Mode ON" 2 "Logistic_Mode_PR" 3 "Not_Used";
VAL_ 402 DRV_RQ_LKOUT 0 "Lockout release switch not pressed_NPSD" 1 "Lockout release switch pressed_PSD" 3 "SNA";
VAL_ 402 DRV_RQ_SHFT_FNG 0 "Shifter_not_initialized" 4 "idle_position" 5 "backwards_twice" 6 "backwards_once" 7 "forward_twice" 9 "forward_once" 10 "tip_plus" 11 "tip_minus" 12 "tip_lane " 14 "M_button" 15 "SNA";
VAL_ 402 SHF_FLT 0 "No_Fault" 1 "LeverPosition_Fault" 2 "P_Button_Fault" 3 "Unlock_Button_Fault" 4 "Background_Illumination_Fault" 5 "Indication_Illumination_Fault" 6 "CAN_Comunication_Fault" 7 "Return_System_Or_Mgate_Locking_Fault";
VAL_ 402 SHFT_P_BUTTON 0 "Init" 1 "Not_Pressed" 2 "Pressed" 3 "Failure";
VAL_ 762 ACC_DistSts 0 "Not Active" 1 "Active";
VAL_ 762 ACC_OnOffSts 0 "Not_Active" 1 "Active";
VAL_ 762 Crono_OnOffSts 0 "Not_Active" 1 "Active";
VAL_ 762 CruiseControlFailSts 0 "Fail_Not_Present" 1 "Fail_Present";
VAL_ 762 CruiseControlOnOffSts 0 "Not_Active" 1 "Active";
VAL_ 762 HDC_OnOffSts 0 "Not_Pressed" 1 "Pressed";
VAL_ 762 ResumeSwitch 0 "Not_Active" 1 "Active";
VAL_ 762 SpeedRockerSts 0 "Increse_10" 1 "Increase_01" 2 "No_Req" 3 "Decrease_01" 4 "Decrease_10" 5 "Not Used" 6 "Not Used" 7 "Not Used";
VAL_ 2654339129 DES_DASM 0 "Error_Active_state" 1 "Error_passive_warning_state" 2 "Bus_off_state" 3 "Not_used";
VAL_ 2654339129 EOL_DASM 0 "No_EOL_prog_at_FIAT" 1 "EOL_prog_at_FIAT";
VAL_ 2654339139 DES_DTCM 0 "Error_Active_state" 1 "Error_passive_warning_state" 2 "Bus_off_state" 3 "Not_used";
VAL_ 2654339139 EOL_DTCM 0 "No_EOL_prog_at_FIAT" 1 "EOL_prog_at_FIAT";
VAL_ 2654339073 DES_ECM 0 "Error_Active_state" 1 "Error_passive_warning_state" 2 "Bus_off_state" 3 "Not_used";
VAL_ 2654339073 EOL_ECM 0 "No_EOL_prog_at_FIAT" 1 "EOL_prog_at_FIAT";
VAL_ 2654339075 DES_IPC 0 "Error_Active_state" 1 "Error_passive_warning_state" 2 "Bus_off_state" 3 "Not_used";
VAL_ 2654339075 EOL_IPC 0 "No_EOL_prog_at_FIAT" 1 "EOL_prog_at_FIAT";
VAL_ 2654339137 DES_RFHM 0 "Error_Active_state" 1 "Error_passive_warning_state" 2 "Bus_off_state" 3 "Not_used";
VAL_ 2654339137 EOL_RFHM 0 "No_EOL_prog_at_FIAT" 1 "EOL_prog_at_FIAT";
VAL_ 2654339094 DES_Shifter 0 "Error_Active_state" 1 "Error_passive_warning_state" 2 "Bus_off_state" 3 "Not_used";
VAL_ 2654339094 EOL_Shifter 0 "No_EOL_prog_at_FIAT" 1 "EOL_prog_at_FIAT";
VAL_ 2654339083 DES_Transmission 0 "Error_Active_state" 1 "Error_passive_warning_state" 2 "Bus_off_state" 3 "Not_used";
VAL_ 2654339083 EOL_Transmission 0 "No_EOL_prog_at_FIAT" 1 "EOL_prog_at_FIAT";
VAL_ 508 ADC_FailSts 0 "Fail_not_present" 1 "Fail_Present";
VAL_ 508 ADC_STS 0 "AUTO" 1 "SOFT" 2 "HARD" 3 "SNA";
VAL_ 508 Aero_FailSts 0 "Fail_not_present" 1 "Fail_Present";
VAL_ 508 CDCM_WarningLamp 0 "Not_Active" 1 "Active";
VAL_ 508 FrontAeroSts 0 "Closed" 1 "Open" 2 "Control_Not_Active" 3 "SNA";
VAL_ 508 Rear_Diff_Control_Sts 0 "Control_Not_Active" 1 "Control_Active";
VAL_ 508 Rear_Diff_WarningLamp 0 "Not_Active" 1 "Active";
VAL_ 1852 ACC_RadarBlinded 0 "Fail_Present" 1 "Fail_not_present";
VAL_ 1852 ACC_SetSpeedKPH 255 "SNA";
VAL_ 1852 ACC_SetSpeedMPH 255 "SNA";
VAL_ 1852 ACCFailSts 0 "Fail_not_present" 1 "Fail_Present";
VAL_ 1852 ACCSystemSts 0 "OFF" 1 "Enabled" 2 "Engaged" 3 "Engaged_BrakeOnly" 4 "Override" 5 "Cancel";
VAL_ 1852 CameraBlinded 0 "Fail_Present" 1 "Fail_not_present";
VAL_ 1852 CameraFailure 0 "Fail_Present" 1 "Fail_not_present";
VAL_ 1852 CHIME_TYPSts 0 "Default" 1 "Chime1" 2 "Chime2" 3 "Chime3";
VAL_ 1852 DASMFailSts 0 "Fail_Present" 1 "Fail_not_present";
VAL_ 1852 DASMTemporaryFailSts 0 "Fail_Present" 1 "Fail_not_present";
VAL_ 1852 FCWSts 0 "Off" 1 "Sound" 2 "Sound_Brake" 3 "Brake";
VAL_ 1852 FCWSystemSts 0 "Off" 1 "On_Only_Warning" 2 "On_Only_Braking" 3 "On_Full";
VAL_ 1852 HMICode_ACC 0 "No CODE" 1 "ACC_UNAVAILABLE_4WD_LOW" 2 "ACC_UNAVAILABLE_HDC_ACTIVE" 3 "ACC_UNAVAILABLE_ESC_FAULT" 4 "ACC_UNAVAILABLE_ESC_OFF" 5 "ACC_UNAVAILABLE_BRAKES_COOLING" 6 "ACC_UNAVAILABLE_BELOW_MIN_SPEED" 7 "ACC_UNAVAILABLE_ABOVE_MAX_SPEED" 8 "ACC_UNAVAILABLE_EPB_ACTIVE" 9 "ACC_UNAVAILABLE_SHIFT_D" 10 "ACC_UNAVAILABLE_WRONG_GEAR" 11 "ACC_UNAVAILABLE_HIGH_RPM" 12 "ACC_UNAVAILABLE_LOW_RPM" 13 "ACC_CANC_BRAKE_COOLING" 14 "ACC_CANC_BELOW_MIN_SPEED" 15 "ACC_CANC_ABOVE_MAX_SPEED" 16 "ACC_CANC_EPB_ACTIVE" 17 "ACC_CANC_ESC_OFF" 18 "ACC_CANC_ESC_EVENT" 19 "ACC_WARNING_CLUTCH_ENGAGED" 20 "ACC_CANC_LOW_RPM" 21 "ACC_CANC_HIGH_RPM" 22 "ACC_WARNING_NEUTRAL_ENGAGED" 23 "ACC_CANC_WRONG_GEAR" 24 "ACC_CANC_SHIFT_D" 25 "ACC_OFF_ESC_FAULT" 26 "ACC_PROX_WARNING" 27 "ACC_CAMERA_FAIL" 28 "ACC_CAMERA BLINDED" 29 "NCC_UNAVAILABLE_4WD_LOW" 30 "NCC_UNAVAILABLE_HDC_ACTIVE" 31 "NCC_UNAVAILABLE_ESC_FAULT" 32 "NCC_UNAVAILABLE_ESC_OFF" 33 "NCC_UNAVAILABLE_BRAKES_COOLING" 34 "NCC_UNAVAILABLE_BELOW_MIN_SPEED" 35 "NCC_UNAVAILABLE_ABOVE_MAX_SPEED" 36 "NCC_UNAVAILABLE_EPB_ACTIVE" 37 "NCC_UNAVAILABLE_SHIFT_D" 38 "NCC_UNAVAILABLE_WRONG_GEAR" 39 "NCC_UNAVAILABLE_HIGH_RPM" 40 "NCC_UNAVAILABLE_LOW_RPM" 41 "NCC_CANC_BRAKE_COOLING" 42 "NCC_CANC_BELOW_MIN_SPEED" 43 "NCC_CANC_ABOVE_MAX_SPEED" 44 "NCC_CANC_EPB_ACTIVE" 45 "NCC_CANC_ESC_OFF" 46 "NCC_CANC_ESC_EVENT" 47 "NCC_WARNING_CLUTCH_ENGAGED" 48 "NCC_CANC_LOW_RPM" 49 "NCC_CANC_HIGH_RPM" 50 "NCC_WARNING_NEUTRAL_ENGAGED" 51 "NCC_CANC_WRONG_GEAR" 52 "NCC_CANC_SHIFT_D" 53 "ACC_USER_DISABLED" 54 "ACC_USER_ENABLED_D1" 55 "ACC_USER_ENABLED_D2" 56 "ACC_USER_ENABLED_D3" 57 "ACC_USER_ENABLED_D4" 58 "ACC_SET_D1_TARGET" 59 "ACC_SET_D2_TARGET" 60 "ACC_SET_D3_TARGET" 61 "ACC_SET_D4_TARGET" 62 "ACC_SET_D1_NO_TARGET" 63 "ACC_SET_D2_NO_TARGET" 64 "ACC_SET_D3_NO_TARGET" 65 "ACC_SET_D4_NO_TARGET" 66 "ACC_CANCEL_D1" 67 "ACC_CANCEL_D2" 68 "ACC_CANCEL_D3" 69 "ACC_CANCEL_D4" 70 "ACC_CANCEL" 71 "ACC_ENABLED" 72 "ACC_SET" 73 "ACC_RESUME" 74 "ACC_OVERRIDE" 75 "ACC_OVERRIDE_D1" 76 "ACC_OVERRIDE_D2" 77 "ACC_OVERRIDE_D3" 78 "ACC_OVERRIDE_D4" 79 "NCC_CANCEL" 80 "NCC_USER_ENABLED" 81 "NCC_SET" 82 "NCC_RESUME" 83 "NCC_USER_DISABLED" 84 "NCC_OVERRIDE" 85 "ACC_UNAVAILABLE" 86 "NCC_UNAVAILABLE" 87 "ACC_CANCEL_CHIME" 88 "NCC_CANCEL_CHIME" 89 "ACC_UNAVAILABLE_ESC_EVENT" 90 "NCC_UNAVAILABLE_ESC_EVENT" 91 "ACC_UNAVAILABLE_CLUTCH_ENGAGED" 92 "NCC_UNAVAILABLE_CLUTCH_ENGAGED" 93 "ACC_FRONT_RADAR_SENSOR_PLANT_MODE" 94 "ACC_CANC_DOOR_OPEN" 95 "ACC_CANC_SEATBELT_UNBUCKLED" 96 "ACC_UNAVAILABLE_DOOR_OPEN" 97 "ACC_UNAVAILABLE_SEATBELT_UNBUCKLED" 98 "ACC_STOP_VEHICLE_OBJECT_DETECTED" 99 "ACC_CANC_ROAD_TOO_STEEP" 100 "ACC_UNAVAILABLE_ROAD_TOO_STEEP";
VAL_ 1852 HMICode_ACC_Ind 0 "Not_Active" 1 "Active";
VAL_ 1852 HMICode_FCW 0 "Idle" 1 "Pre_Intervention_warning" 2 "Intervention__warning" 3 "Not_Available_warning_type1" 4 "Not_Available_warning_4WD_Low";
VAL_ 1852 HMIDisplay_ACC 0 "No_Code" 1 "ACC_USER_DISABLED" 2 "ACC_USER_ENABLED_D1" 3 "ACC_USER_ENABLED_D2" 4 "ACC_USER_ENABLED_D3" 5 "ACC_USER_ENABLED_D4" 6 "ACC_SET_D1_TARGET" 7 "ACC_SET_D2_TARGET" 8 "ACC_SET_D3_TARGET" 9 "ACC_SET_D4_TARGET" 10 "ACC_SET_D1_NO_TARGET" 11 "ACC_SET_D2_NO_TARGET" 12 "ACC_SET_D3_NO_TARGET" 13 "ACC_SET_D4_NO_TARGET" 14 "ACC_CANCEL_D1" 15 "ACC_CANCEL_D2" 16 "ACC_CANCEL_D3" 17 "ACC_CANCEL_D4" 18 "ACC_CANCEL" 19 "ACC_ENABLED" 20 "ACC_SET" 21 "ACC_RESUME" 22 "ACC_OVERRIDE" 23 "ACC_OVERRIDE_D1" 24 "ACC_OVERRIDE_D2" 25 "ACC_OVERRIDE_D3" 26 "ACC_OVERRIDE_D4" 27 "NCC_CANCEL" 28 "NCC_USER_ENABLED" 29 "NCC_SET" 30 "NCC_RESUME" 31 "NCC_USER_DISABLED" 32 "NCC_OVERRIDE";
VAL_ 1852 NCCFailSts 0 "Fail_not_present" 1 "Fail_Present";
VAL_ 1852 RadarBlinded 0 "Fail_Present" 1 "Fail_not_present";
VAL_ 242 Auto_Manual_Button_Sts 0 "Not_Pressed" 1 "Pressed";
VAL_ 242 Buttons_Fault_Sts 0 "No_Fault" 1 "Auto_Manual_Fault" 2 "Launch_Button_Fault" 3 "Reverse_Button_Fault" 4 "Background_Illumination_Fault" 5 "CAN_Commnication_Fault" 6 "Multiple_Button_Fault";
VAL_ 242 Launch_Button_Sts 0 "Not_Pressed" 1 "Pressed";
VAL_ 242 Park_Button_Sts 0 "Not_Pressed" 1 "Pressed";
VAL_ 242 Reverse_Button_Sts 0 "Not_Pressed" 1 "Pressed";
VAL_ 1454 ChkFuelCap 0 "Not_Detected" 1 "Detected";
VAL_ 1454 ColdStartLampIndication 0 "Steady_Light" 1 "Blinking_Light" 2 "Warning_Message" 3 "No_Indication";
VAL_ 1454 CompressorSts 0 "Not_Used" 1 "Not_inserted_by_NCM" 2 "Not_insrtd_by_driver_or_security" 3 "Inserted";
VAL_ 1454 DPFSts 0 "Clean" 1 "Dirty";
VAL_ 1454 EMSFailSts 0 "Fail_Not_Present" 1 "Fail_Flash_Light_Indication" 2 "Fail_Fix_Light_Indication" 3 "Flash_For_Service";
VAL_ 1454 EngineOperatingMode 0 "Normal" 1 "DPF Regeneration LO" 2 "DPF Regeneration HI" 3 "NSC DeNOx Regeneration" 4 "NSC DeSOx Regeneration" 5 "SCR Heat-up strategy";
VAL_ 1454 EngineWaterTempWarningLightSts 0 "OFF" 1 "ON";
VAL_ 1454 ETCFailSts 0 "Fail_Not_Present" 1 "Fail_Flash_Light_Indication" 2 "Fail_Fix_Light_Indication" 3 "Flash_For_Service";
VAL_ 1454 ExhaustTemperature 255 "SNA";
VAL_ 1454 FuelFilterHeaterReq 0 "Not_Active" 1 "Active";
VAL_ 1454 FuelWaterPresentFailSts 0 "Fail_Not_Present" 1 "Fail_Present";
VAL_ 1454 FuelWaterPresentSts 0 "Water_Not_Present" 1 "Water_Present";
VAL_ 1454 GlowPlugFailSts 0 "Fail_Not_Present" 1 "Fail_Present";
VAL_ 1454 GlowPlugLampSts 0 "OFF" 1 "ON";
VAL_ 1454 OilLifeSts 0 "Normal_Oil_Properties" 1 "Oil_Life_Reset" 2 "Change_Oil_Required" 3 "Not_used";
VAL_ 1454 OilPressureFailSts 0 "Fail_Not_Present" 1 "Fail_Present";
VAL_ 1454 OilPressureSts 0 "Normal_Pressure" 1 "Low_Pressure";
VAL_ 1504 EPB_HMI_Management 0 "No_Ind" 1 "Ind1" 2 "Ind2" 3 "Ind3" 4 "Ind4" 5 "Ind5" 6 "Ind6" 7 "Ind7" 8 "Ind8" 9 "Ind9" 10 "Ind10" 11 "Ind11" 12 "Ind12" 13 "Ind13" 14 "Ind14" 15 "Ind15" 16 "Ind16" 17 "Ind17" 18 "Ind18" 19 "Ind19" 20 "Ind20" 21 "Ind21" 22 "Ind22" 23 "Ind23" 24 "Ind24" 25 "Ind25" 26 "Ind26" 27 "Ind27" 28 "Ind28" 29 "Ind29" 30 "Ind30" 31 "Ind31";
VAL_ 1504 EPBAutoAppSts 0 "AutoApply_Disable" 1 "AutoApply_Enable";
VAL_ 1504 EPBFailureLampReq 0 "lamp off" 1 "lamp on";
VAL_ 1504 EPBMaintenanceSts 0 "Maintenance_Disabled" 1 "Maintenance_Enabled";
VAL_ 1504 EPBSts 0 "Released" 1 "Applied" 2 "DynamicBrkESC" 3 "DynamicBrkEPB" 4 "Emergency_Braking" 5 "Applying" 6 "Maintenance_Mode" 7 "Assembly_Check" 8 "Inspection_Mode" 9 "Re_Clamping" 10 "Adjuste_Mode" 11 "Releasing" 12 "Fault_EPB_Released" 13 "Fault_EPB_Applied" 14 "Fault_Present" 15 "SNA";
VAL_ 1504 EPBSwitchPosition 0 "No request" 1 "Release request" 2 "Apply request" 3 "Error";
VAL_ 1504 FastTransmission_SE 0 "Slow" 1 "Fast";
VAL_ 1504 RedLampReq 0 "Off" 1 "Fixed" 2 "Blinking" 3 "SNA";
VAL_ 1196 InflationState_LHF_Tyre 0 "Normal_Tyre_Pressure" 1 "Under_Inflated_Tyre" 2 "SignificantlyUnderInflatedTyre" 3 "Over_Inflated_Tyre" 4 "Sensor_Missing";
VAL_ 1196 InflationState_LHR_Tyre 0 "Normal_Tyre_Pressure" 1 "Under_Inflated_Tyre" 2 "SignificantlyUnderInflatedTyre" 3 "Over_Inflated_Tyre" 4 "Sensor_Missing";
VAL_ 1196 InflationState_RHF_Tyre 0 "Normal_Tyre_Pressure" 1 "Under_Inflated_Tyre" 2 "SignificantlyUnderInflatedTyre" 3 "Over_Inflated_Tyre" 4 "Sensor_Missing";
VAL_ 1196 InflationState_RHR_Tyre 0 "Normal_Tyre_Pressure" 1 "Under_Inflated_Tyre" 2 "SignificantlyUnderInflatedTyre" 3 "Over_Inflated_Tyre" 4 "Sensor_Missing";
VAL_ 1196 PressureValue_LHF_Tyre 63 "SNA";
VAL_ 1196 PressureValue_LHR_Tyre 63 "SNA";
VAL_ 1196 PressureValue_RHF_Tyre 63 "SNA";
VAL_ 1196 PressureValue_RHR_Tyre 63 "SNA";
VAL_ 1196 TPMActivitySts 0 "TPM_Enabled" 1 "TPM_Disabled";
VAL_ 1196 TyrePressureSysProgrammedSts 0 "System_Programmed" 1 "System_Not_Programmed";
VAL_ 1196 TyrePressureSystemFailSts 0 "Fail_Not_Present" 1 "Fail_Present";
VAL_ 1992 TrailerConnectionSts 0 "Not_Connected" 1 "Connected" 2 "Not_Used" 3 "SNA";
VAL_ 1992 TrailerGenericFailSts 0 "No_fault_present" 1 "Fault_present";
VAL_ 240 EngTrq_Rq_TCM 2047 "SNA";
VAL_ 240 EngTrq_Rq_TCM_Slow 2047 "SNA";
VAL_ 240 IDFSO_Trq_Req 63 "SNA";
VAL_ 240 MaxTrqDes 2047 "SNA";
VAL_ 240 TorqueConverterSTO 0 "Not_Active" 1 "Active";
VAL_ 240 TorqueConverterSts 0 "Lock_up_clutch_opened" 1 "Lock_up_clutch_is_slipping" 2 "Lock_up_clutch_closed" 3 "SNA";
VAL_ 240 TrqCtrlModeReq 0 "None" 1 "TRQ_INC" 2 "TRQ_DEC" 3 "SNA";
VAL_ 240 TrqCtrlModeReq_Slow 0 "NONE" 1 "TRQ_INC" 2 "TRQ_DEC" 3 "SNA";
VAL_ 503 FANRequestNCA 0 "Off" 1 "LowSpeed" 2 "highSpeed" 3 "SNA";
VAL_ 503 OUTPUT_SPEED 65535 "SNA";
VAL_ 503 TransmissionTemperature 63 "SNA";
VAL_ 503 TransmissionTemperatureFailSts 0 "Fail_not_present" 1 "Fail_present";
VAL_ 503 TransReadyForESS 0 "Not_Ready" 1 "Ready";
VAL_ 503 Trns_EMCC_Achvd 0 "False" 1 "True";
VAL_ 503 TRNS_StpSt_FLT 0 "Not_Present" 1 "Present";
VAL_ 503 TurbineSpeed 65535 "SNA";
VAL_ 236 CutRequest 0 "Inactive" 1 "Cut Request";
VAL_ 236 DCTMGbProtectionSpeed 0 "Inactive" 1 "Active";
VAL_ 236 DCTMGbProtectionTorque 0 "Inactive" 1 "Active";
VAL_ 236 EngineSlaveRequest 0 "Inactive" 1 "Slave Mode";
VAL_ 236 FutureSyncGear 0 "Neutral" 1 "ForwardGear_1" 2 "ForwardGear_2" 3 "ForwardGear_3" 4 "ForwardGear_4" 5 "ForwardGear_5" 6 "ForwardGear_6" 7 "ForwardGear_7" 8 "ForwardGear_8" 9 "ForwardGear_9" 13 "Parking" 14 "ReverseGear" 15 "SNA";
VAL_ 236 FutureSyncRPM 4095 "SNA";
VAL_ 236 ReqEngineSpeed 4095 "SNA";
VAL_ 236 ReqTorqueValue 2047 "SNA";
VAL_ 260 EngTrgtSpdCtrl 4095 "SNA";
VAL_ 260 EngTrgtSpdCtrl_Active 0 "Not_Active" 1 "Active";
VAL_ 260 Garage_SIP 0 "Not_Active" 1 "Active";
VAL_ 260 TransmissionNuenSts 0 "Nuen_Passive" 1 "Nuen_Entry" 2 "Nuen_Active" 3 "Nuen_Exit";
VAL_ 260 TransmissionSailingSts 0 "Sailing_Not Possible" 1 "Sailing_Possible_Passive" 2 "Transition_To_Sailing" 3 "Sailing_Active" 4 "Transition_Out_Of_Sailing" 5 "Sailing_Not_Available" 15 "SNA";
VAL_ 260 TxIdleRq 255 "SNA";
VAL_ 1448 BuzzerReqSts_T2 0 "OFF" 1 "Reverse_Gear_Sound_ON" 2 "Others_case_Sound_ON" 3 "Not_used";
VAL_ 1448 CrankEnable 0 "Disabled" 1 "Enabled";
VAL_ 1448 DriveModeSts 0 "No_programs_available_selected" 1 "Eco" 2 "Sport" 3 "Not_used" 4 "Ice_Winter" 5 "Tow_Haul" 6 "Track" 7 "4LowMode" 8 "HDC/SSC" 9 "not_used" 10 "not_used" 11 "not_used" 12 "not_used" 13 "not_used" 14 "not_used" 15 "not_used";
VAL_ 1448 GearEngaged 0 "Neutral" 1 "ForwardGear_1" 2 "ForwardGear_2" 3 "ForwardGear_3" 4 "ForwardGear_4" 5 "ForwardGear_5" 6 "ForwardGear_6" 7 "ForwardGear_7" 8 "ForwardGear_8" 9 "ForwardGear_9" 13 "Parking" 14 "ReverseGear" 15 "SNA";
VAL_ 1448 GearIndicationSts 0 "Normal" 1 "Blinking";
VAL_ 1448 LeverPosition 0 "No_Selection_Active_Or_Available" 1 "P" 2 "R" 3 "N" 4 "D" 5 "L" 6 "TIP_Autostick" 7 "Plus" 8 "Minus" 9 "Sport" 10 "Not_Used" 11 "Not_Used" 12 "Not_Used" 13 "Not_Used" 14 "Not_Used" 15 "SNA";
VAL_ 1448 LimpHomeSts 0 "NotActive" 1 "Active";
VAL_ 1448 MIReq 0 "No_EOBD_error" 1 "EOBD_error";
VAL_ 1448 OilTemperatureSts 0 "Normal" 1 "High";
VAL_ 1448 ParkingFailSts 0 "Fail_not_present" 1 "Fail_present";
VAL_ 1448 ParkingSts 0 "Not_Parking" 1 "Parking";
VAL_ 1448 ShiftInProgress 0 "No Shift in progress" 1 "Shift in progress";
VAL_ 1448 ShiftLeverPosition 0 "No_Selection_Active_Or_Available" 1 "P" 2 "R" 3 "N" 4 "D" 5 "L" 6 "TIP_Autostick" 7 "Plus" 8 "Minus" 9 "Sport" 10 "Not_Used" 11 "Not_Used" 12 "Not_Used" 13 "Not_Used" 14 "Not_Used" 15 "SNA";
VAL_ 1448 ShiftModeSts 0 "Manual" 1 "Automatic";
VAL_ 1448 TargetGear 0 "Neutral" 1 "ForwardGear_1" 2 "ForwardGear_2" 3 "ForwardGear_3" 4 "ForwardGear_4" 5 "ForwardGear_5" 6 "ForwardGear_6" 7 "ForwardGear_7" 8 "ForwardGear_8" 9 "ForwardGear_9" 13 "Parking" 14 "ReverseGear" 15 "SNA";
VAL_ 1448 TemporaryManualSts 0 "Not_Active" 1 "Active";
VAL_ 1448 TransmissionFailSts 0 "Fail_not_present" 1 "Fail_present";
VAL_ 1448 TransmissionWarnings 0 "No_Warning" 1 "Press_Brake_Pedal" 2 "Tip_Not_Available" 3 "Lower_Gear_Shifts" 4 "Manual_Mode_Not_Available" 5 "Insert_N" 6 "Automatic_Mode_Not_Available" 7 "Press_Brake_Delayed_Startup_Warning" 8 "Clutch_Overtemperature" 9 "Manoeuvre_Not_Allowed" 10 "Press_Brake_Pedal_Repeat" 11 "Gear_Not_Available" 12 "Shift_Not_Allowed" 13 "Shift_to_Neutral_Then_DR" 14 "Reduce_Gear_Changes" 15 "Clutch_Overheater_Must_Cool" 16 "Service_Transmission" 17 "Service_Shifter" 18 "Engage_Park_Brake" 19 "Trans_Too_Cold_Pls_Wait" 20 "Push_Button_to_Shift" 21 "Return_Shifter_To_Home" 22 "Press_Brake_Push_Button_Shift" 23 "Service_Trans_Shut_Off" 24 "Already_in_Des_Gear" 25 "Start_Engine_to_Shift" 26 "Service_Trans_Use_Pk_Brk" 27 "Vehicle_Speed_Too_High" 28 "Tow_Haul_Not_available" 29 "Tow_Haul_Disengaged" 30 "Trans_Cool_Ready_to_Drive" 31 "Vehicle_Speed_Too_High_to_Shift_P" 32 "Vehicle_Speed_Too_High_to_Shift_R" 33 "Vehicle_Speed_Too_High_to_Shift_D" 34 "Manual_Shift_Temp_Not_Available" 35 "Vehicle_Speed_Too_High_to_Shift_L/S" 36 "Shift_to_Park_to_ obtain_drivability" 37 "Shift_to_Park_to_Start" 38 "APCM_in_Progress" 39 "Stop Vehicle to Shift" 40 "Service Transmission_Stop Vehicle to Shift " 41 "Service Transmission__Stop Vehicle_Restart Vehicle in P to Continue Driving" 42 "Service Transmission_Stop Vehicle to Shift _Restart Vehicle in P to Continue Driving" 43 "Press Brake To Prevent Vehicle From Rolling" 45 "Trans_Recover_Mode_Warning" 46 "Washing_Active" 47 "To_Select_Gear_Press_Brake_And_Unlock_Button" 48 "To_Select_Forward_Gear press brake_And_Unlock_Button" 49 "To_Select_Forward_Gear_Press_Brake" 50 "To_Select_Reverse_Gear_Press_Brake_And_Unlock button" 51 "To_Select_Reverse_Gear_Press_Brake" 52 "To_Select_Reverse_Gear_Press_Unlock_Button" 53 "Vehicle_Not_In_Park" 54 "Paddles_Not_Available" 55 "Service_Shifter_PButton_Not_Available" 56 "Service_Shifter_Unlock_Button_Not_Available" 57 "Lever_Out_Of_Position";
VAL_ 1448 TxDisengaged 0 "Engaged" 1 "Disengaged";
VAL_ 1448 UpDownShiftSel 0 "ON" 1 "OFF";
VAL_ 234 ActiveGearRatio 255 "SNA";
VAL_ 234 AMTIndex 127 "SNA";
VAL_ 234 ClutchStatus 0 "Open" 1 "Slip" 2 "Mslip" 3 "Closed";
VAL_ 234 CutOffTime 255 "SNA";
VAL_ 234 ESPReqFulfillDCTM 0 "False" 1 "True";
VAL_ 234 GearBoxAbsorption 63 "SNA";
VAL_ 234 LaunchActive 0 "Inactive" 1 "Allowed" 2 "Active" 3 "Not Defined";
VAL_ 253 CodeCheckSts_TRM 0 "No_Code" 1 "CodeCheck_OK" 2 "CodeCheck_Fault" 3 "Not_Used";
VAL_ 253 ProgrammedSts_TRM 0 "Not_Programmed" 1 "Programmed";
VAL_ 253 TxpFound 0 "Transponder_Read" 1 "Transponder_Absent";
VAL_ 253 TxpID 0 "Transponder_Not_Authenticated" 1 "Transponder_1_Authenticated" 2 "Transponder_2_Authenticated" 3 "Transponder_3_Authenticated" 4 "Transponder_4_Authenticated" 5 "Transponder_5_Authenticated" 6 "Transponder_6_Authenticated" 7 "Transponder_7_Authenticated" 8 "Transponder_8_Authenticated" 9 "Transponder_9_Authenticated" 10 "Transponder_10_Authenticated" 11 "Transponder_11_Authenticated" 12 "Transponder_12_Authenticated" 13 "Transponder_13_Authenticated" 14 "Transponder_14_Authenticated" 15 "Transponder_15_Authenticated";
VAL_ 243 FrameNumber 0 "Frame_1" 1 "Frame_2" 2 "Frame_3" 3 "Frame_4" 4 "Frame_5" 5 "Frame_6" 6 "Frame_7" 7 "Frame_8" 8 "Frame_9" 9 "Frame_10" 10 "Frame_11" 11 "Frame_12" 12 "Frame_13" 13 "Frame_14" 14 "Frame_15" 15 "Frame_16";
VAL_ 243 TotalFrameNumber 0 "One_Frame" 1 "Two_Frames" 2 "Three_Frames" 3 "Four_Frames" 4 "Five_Frames" 5 "Six_Frames" 6 "Seven_Frames" 7 "Eight_Frame" 8 "Nine_Frames" 9 "Ten_Frames" 10 "Eleven_Frames" 11 "Twelve_Frames" 12 "Thirteen_Frames" 13 "Fourteen_Frames" 14 "Fifteen_Frames" 15 "Sixteen_Frames";
VAL_ 1046 VIN_MSG 0 "VIN_LO" 1 "VIN_MID" 2 "VIN_HI" 3 "SNA";
VAL_ 2654208000 MainWakeSts_BCM 0 "Not_Active" 1 "Active";
VAL_ 2654208000 Node0 0 "Not_active" 1 "Active";
VAL_ 2654208000 Node1 0 "Not_active" 1 "Active";
VAL_ 2654208000 Node10 0 "Not_active" 1 "Active";
VAL_ 2654208000 Node11 0 "Not_active" 1 "Active";
VAL_ 2654208000 Node12 0 "Not_active" 1 "Active";
VAL_ 2654208000 Node13 0 "Not_active" 1 "Active";
VAL_ 2654208000 Node14 0 "Not_active" 1 "Active";
VAL_ 2654208000 Node15 0 "Not_active" 1 "Active";
VAL_ 2654208000 Node16 0 "Not_active" 1 "Active";
VAL_ 2654208000 Node17 0 "Not_active" 1 "Active";
VAL_ 2654208000 Node18 0 "Not_active" 1 "Active";
VAL_ 2654208000 Node19 0 "Not_active" 1 "Active";
VAL_ 2654208000 Node2 0 "Not_active" 1 "Active";
VAL_ 2654208000 Node20 0 "Not_active" 1 "Active";
VAL_ 2654208000 Node21 0 "Not_active" 1 "Active";
VAL_ 2654208000 Node22 0 "Not_active" 1 "Active";
VAL_ 2654208000 Node23 0 "Not_active" 1 "Active";
VAL_ 2654208000 Node24 0 "Not_active" 1 "Active";
VAL_ 2654208000 Node25 0 "Not_active" 1 "Active";
VAL_ 2654208000 Node26 0 "Not_active" 1 "Active";
VAL_ 2654208000 Node27 0 "Not_active" 1 "Active";
VAL_ 2654208000 Node28 0 "Not_active" 1 "Active";
VAL_ 2654208000 Node29 0 "Not_active" 1 "Active";
VAL_ 2654208000 Node3 0 "Not_active" 1 "Active";
VAL_ 2654208000 Node30 0 "Not_active" 1 "Active";
VAL_ 2654208000 Node31 0 "Not_active" 1 "Active";
VAL_ 2654208000 Node4 0 "Not_active" 1 "Active";
VAL_ 2654208000 Node5 0 "Not_active" 1 "Active";
VAL_ 2654208000 Node6 0 "Not_active" 1 "Active";
VAL_ 2654208000 Node7 0 "Not_active" 1 "Active";
VAL_ 2654208000 Node8 0 "Not_active" 1 "Active";
VAL_ 2654208000 Node9 0 "Not_active" 1 "Active";
VAL_ 2654208000 WakeRsn_BCM 0 "Diag" 1 "Network" 2 "WakeRsn2" 3 "WakeRsn3" 4 "WakeRsn4" 5 "WakeRsn5" 6 "WakeRsn6" 7 "WakeRsn7" 8 "WakeRsn8" 9 "WakeRsn9" 10 "WakeRsn10" 11 "WakeRsn11" 12 "WakeRsn12" 13 "WakeRsn13" 14 "WakeRsn14" 15 "WakeRsn15" 16 "WakeRsn16" 17 "WakeRsn17" 18 "WakeRsn18" 19 "WakeRsn19" 20 "WakeRsn20" 21 "WakeRsn21" 22 "WakeRsn22" 23 "WakeRsn23" 24 "WakeRsn24" 25 "WakeRsn25" 26 "WakeRsn26" 27 "WakeRsn27" 28 "WakeRsn28" 29 "WakeRsn29" 30 "WakeRsn30" 31 "WakeRsn31" 32 "WakeRsn32" 33 "WakeRsn33" 34 "WakeRsn34" 35 "WakeRsn35" 36 "WakeRsn36" 37 "WakeRsn37" 38 "WakeRsn38" 39 "WakeRsn39" 40 "WakeRsn40" 41 "WakeRsn41" 42 "WakeRsn42" 43 "WakeRsn43" 44 "WakeRsn44" 45 "WakeRsn45" 46 "WakeRsn46" 47 "WakeRsn47" 48 "WakeRsn48" 49 "WakeRsn49" 50 "WakeRsn50" 51 "WakeRsn51" 52 "WakeRsn52" 53 "WakeRsn53" 54 "WakeRsn54" 55 "WakeRsn55" 56 "WakeRsn56" 57 "WakeRsn57" 58 "WakeRsn58" 59 "WakeRsn59" 60 "WakeRsn60" 61 "WakeRsn61" 62 "WakeRsn62" 63 "WakeRsn63" 64 "WakeRsn64" 65 "WakeRsn65" 66 "WakeRsn66" 67 "WakeRsn67" 68 "WakeRsn68" 69 "WakeRsn69" 70 "WakeRsn70" 71 "WakeRsn71" 72 "WakeRsn72" 73 "WakeRsn73" 74 "WakeRsn74" 75 "WakeRsn75" 76 "WakeRsn76" 77 "WakeRsn77" 78 "WakeRsn78" 79 "WakeRsn79" 80 "WakeRsn80" 81 "WakeRsn81" 82 "WakeRsn82" 83 "WakeRsn83" 84 "WakeRsn84" 85 "WakeRsn85" 86 "WakeRsn86" 87 "WakeRsn87" 88 "WakeRsn88" 89 "WakeRsn89" 90 "WakeRsn90" 91 "WakeRsn91" 92 "WakeRsn92" 93 "WakeRsn93" 94 "WakeRsn94" 95 "WakeRsn95" 96 "WakeRsn96" 97 "WakeRsn97" 98 "WakeRsn98" 99 "WakeRsn99" 100 "WakeRsn100" 101 "WakeRsn101" 102 "WakeRsn102" 103 "WakeRsn103" 104 "WakeRsn104" 105 "WakeRsn105" 106 "WakeRsn106" 107 "WakeRsn107" 108 "WakeRsn108" 109 "WakeRsn109" 110 "WakeRsn110" 111 "WakeRsn111" 112 "WakeRsn112" 113 "WakeRsn113" 114 "WakeRsn114" 115 "WakeRsn115" 116 "WakeRsn116" 117 "WakeRsn117" 118 "WakeRsn118" 119 "WakeRsn119" 120 "WakeRsn120" 121 "WakeRsn121" 122 "WakeRsn122" 123 "WakeRsn123" 124 "WakeRsn124" 125 "WakeRsn125" 126 "WakeRsn126" 127 "WakeRsn127";
VAL_ 2654208006 WakeReq_BSM 0 "NotActive" 1 "Active";
VAL_ 2654208006 WakeRsn_BSM 0 "Diag" 1 "Network" 2 "WakeRsn2" 3 "WakeRsn3" 4 "WakeRsn4" 5 "WakeRsn5" 6 "WakeRsn6" 7 "WakeRsn7" 8 "WakeRsn8" 9 "WakeRsn9" 10 "WakeRsn10" 11 "WakeRsn11" 12 "WakeRsn12" 13 "WakeRsn13" 14 "WakeRsn14" 15 "WakeRsn15" 16 "WakeRsn16" 17 "WakeRsn17" 18 "WakeRsn18" 19 "WakeRsn19" 20 "WakeRsn20" 21 "WakeRsn21" 22 "WakeRsn22" 23 "WakeRsn23" 24 "WakeRsn24" 25 "WakeRsn25" 26 "WakeRsn26" 27 "WakeRsn27" 28 "WakeRsn28" 29 "WakeRsn29" 30 "WakeRsn30" 31 "WakeRsn31" 32 "WakeRsn32" 33 "WakeRsn33" 34 "WakeRsn34" 35 "WakeRsn35" 36 "WakeRsn36" 37 "WakeRsn37" 38 "WakeRsn38" 39 "WakeRsn39" 40 "WakeRsn40" 41 "WakeRsn41" 42 "WakeRsn42" 43 "WakeRsn43" 44 "WakeRsn44" 45 "WakeRsn45" 46 "WakeRsn46" 47 "WakeRsn47" 48 "WakeRsn48" 49 "WakeRsn49" 50 "WakeRsn50" 51 "WakeRsn51" 52 "WakeRsn52" 53 "WakeRsn53" 54 "WakeRsn54" 55 "WakeRsn55" 56 "WakeRsn56" 57 "WakeRsn57" 58 "WakeRsn58" 59 "WakeRsn59" 60 "WakeRsn60" 61 "WakeRsn61" 62 "WakeRsn62" 63 "WakeRsn63" 64 "WakeRsn64" 65 "WakeRsn65" 66 "WakeRsn66" 67 "WakeRsn67" 68 "WakeRsn68" 69 "WakeRsn69" 70 "WakeRsn70" 71 "WakeRsn71" 72 "WakeRsn72" 73 "WakeRsn73" 74 "WakeRsn74" 75 "WakeRsn75" 76 "WakeRsn76" 77 "WakeRsn77" 78 "WakeRsn78" 79 "WakeRsn79" 80 "WakeRsn80" 81 "WakeRsn81" 82 "WakeRsn82" 83 "WakeRsn83" 84 "WakeRsn84" 85 "WakeRsn85" 86 "WakeRsn86" 87 "WakeRsn87" 88 "WakeRsn88" 89 "WakeRsn89" 90 "WakeRsn90" 91 "WakeRsn91" 92 "WakeRsn92" 93 "WakeRsn93" 94 "WakeRsn94" 95 "WakeRsn95" 96 "WakeRsn96" 97 "WakeRsn97" 98 "WakeRsn98" 99 "WakeRsn99" 100 "WakeRsn100" 101 "WakeRsn101" 102 "WakeRsn102" 103 "WakeRsn103" 104 "WakeRsn104" 105 "WakeRsn105" 106 "WakeRsn106" 107 "WakeRsn107" 108 "WakeRsn108" 109 "WakeRsn109" 110 "WakeRsn110" 111 "WakeRsn111" 112 "WakeRsn112" 113 "WakeRsn113" 114 "WakeRsn114" 115 "WakeRsn115" 116 "WakeRsn116" 117 "WakeRsn117" 118 "WakeRsn118" 119 "WakeRsn119" 120 "WakeRsn120" 121 "WakeRsn121" 122 "WakeRsn122" 123 "WakeRsn123" 124 "WakeRsn124" 125 "WakeRsn125" 126 "WakeRsn126" 127 "WakeRsn127";
VAL_ 2654208003 WakeReq_IPC 0 "NotActive" 1 "Active";
VAL_ 2654208003 WakeRsn_IPC 0 "Diag" 1 "Network" 2 "WakeRsn2" 3 "WakeRsn3" 4 "WakeRsn4" 5 "WakeRsn5" 6 "WakeRsn6" 7 "WakeRsn7" 8 "WakeRsn8" 9 "WakeRsn9" 10 "WakeRsn10" 11 "WakeRsn11" 12 "WakeRsn12" 13 "WakeRsn13" 14 "WakeRsn14" 15 "WakeRsn15" 16 "WakeRsn16" 17 "WakeRsn17" 18 "WakeRsn18" 19 "WakeRsn19" 20 "WakeRsn20" 21 "WakeRsn21" 22 "WakeRsn22" 23 "WakeRsn23" 24 "WakeRsn24" 25 "WakeRsn25" 26 "WakeRsn26" 27 "WakeRsn27" 28 "WakeRsn28" 29 "WakeRsn29" 30 "WakeRsn30" 31 "WakeRsn31" 32 "WakeRsn32" 33 "WakeRsn33" 34 "WakeRsn34" 35 "WakeRsn35" 36 "WakeRsn36" 37 "WakeRsn37" 38 "WakeRsn38" 39 "WakeRsn39" 40 "WakeRsn40" 41 "WakeRsn41" 42 "WakeRsn42" 43 "WakeRsn43" 44 "WakeRsn44" 45 "WakeRsn45" 46 "WakeRsn46" 47 "WakeRsn47" 48 "WakeRsn48" 49 "WakeRsn49" 50 "WakeRsn50" 51 "WakeRsn51" 52 "WakeRsn52" 53 "WakeRsn53" 54 "WakeRsn54" 55 "WakeRsn55" 56 "WakeRsn56" 57 "WakeRsn57" 58 "WakeRsn58" 59 "WakeRsn59" 60 "WakeRsn60" 61 "WakeRsn61" 62 "WakeRsn62" 63 "WakeRsn63" 64 "WakeRsn64" 65 "WakeRsn65" 66 "WakeRsn66" 67 "WakeRsn67" 68 "WakeRsn68" 69 "WakeRsn69" 70 "WakeRsn70" 71 "WakeRsn71" 72 "WakeRsn72" 73 "WakeRsn73" 74 "WakeRsn74" 75 "WakeRsn75" 76 "WakeRsn76" 77 "WakeRsn77" 78 "WakeRsn78" 79 "WakeRsn79" 80 "WakeRsn80" 81 "WakeRsn81" 82 "WakeRsn82" 83 "WakeRsn83" 84 "WakeRsn84" 85 "WakeRsn85" 86 "WakeRsn86" 87 "WakeRsn87" 88 "WakeRsn88" 89 "WakeRsn89" 90 "WakeRsn90" 91 "WakeRsn91" 92 "WakeRsn92" 93 "WakeRsn93" 94 "WakeRsn94" 95 "WakeRsn95" 96 "WakeRsn96" 97 "WakeRsn97" 98 "WakeRsn98" 99 "WakeRsn99" 100 "WakeRsn100" 101 "WakeRsn101" 102 "WakeRsn102" 103 "WakeRsn103" 104 "WakeRsn104" 105 "WakeRsn105" 106 "WakeRsn106" 107 "WakeRsn107" 108 "WakeRsn108" 109 "WakeRsn109" 110 "WakeRsn110" 111 "WakeRsn111" 112 "WakeRsn112" 113 "WakeRsn113" 114 "WakeRsn114" 115 "WakeRsn115" 116 "WakeRsn116" 117 "WakeRsn117" 118 "WakeRsn118" 119 "WakeRsn119" 120 "WakeRsn120" 121 "WakeRsn121" 122 "WakeRsn122" 123 "WakeRsn123" 124 "WakeRsn124" 125 "WakeRsn125" 126 "WakeRsn126" 127 "WakeRsn127";
VAL_ 2654208065 WakeReq_RFHM 0 "NotActive" 1 "Active";
VAL_ 2654208065 WakeRsn_RFHM 0 "Diag" 1 "Network" 2 "WakeRsn2" 3 "WakeRsn3" 4 "WakeRsn4" 5 "WakeRsn5" 6 "WakeRsn6" 7 "WakeRsn7" 8 "WakeRsn8" 9 "WakeRsn9" 10 "WakeRsn10" 11 "WakeRsn11" 12 "WakeRsn12" 13 "WakeRsn13" 14 "WakeRsn14" 15 "WakeRsn15" 16 "WakeRsn16" 17 "WakeRsn17" 18 "WakeRsn18" 19 "WakeRsn19" 20 "WakeRsn20" 21 "WakeRsn21" 22 "WakeRsn22" 23 "WakeRsn23" 24 "WakeRsn24" 25 "WakeRsn25" 26 "WakeRsn26" 27 "WakeRsn27" 28 "WakeRsn28" 29 "WakeRsn29" 30 "WakeRsn30" 31 "WakeRsn31" 32 "WakeRsn32" 33 "WakeRsn33" 34 "WakeRsn34" 35 "WakeRsn35" 36 "WakeRsn36" 37 "WakeRsn37" 38 "WakeRsn38" 39 "WakeRsn39" 40 "WakeRsn40" 41 "WakeRsn41" 42 "WakeRsn42" 43 "WakeRsn43" 44 "WakeRsn44" 45 "WakeRsn45" 46 "WakeRsn46" 47 "WakeRsn47" 48 "WakeRsn48" 49 "WakeRsn49" 50 "WakeRsn50" 51 "WakeRsn51" 52 "WakeRsn52" 53 "WakeRsn53" 54 "WakeRsn54" 55 "WakeRsn55" 56 "WakeRsn56" 57 "WakeRsn57" 58 "WakeRsn58" 59 "WakeRsn59" 60 "WakeRsn60" 61 "WakeRsn61" 62 "WakeRsn62" 63 "WakeRsn63" 64 "WakeRsn64" 65 "WakeRsn65" 66 "WakeRsn66" 67 "WakeRsn67" 68 "WakeRsn68" 69 "WakeRsn69" 70 "WakeRsn70" 71 "WakeRsn71" 72 "WakeRsn72" 73 "WakeRsn73" 74 "WakeRsn74" 75 "WakeRsn75" 76 "WakeRsn76" 77 "WakeRsn77" 78 "WakeRsn78" 79 "WakeRsn79" 80 "WakeRsn80" 81 "WakeRsn81" 82 "WakeRsn82" 83 "WakeRsn83" 84 "WakeRsn84" 85 "WakeRsn85" 86 "WakeRsn86" 87 "WakeRsn87" 88 "WakeRsn88" 89 "WakeRsn89" 90 "WakeRsn90" 91 "WakeRsn91" 92 "WakeRsn92" 93 "WakeRsn93" 94 "WakeRsn94" 95 "WakeRsn95" 96 "WakeRsn96" 97 "WakeRsn97" 98 "WakeRsn98" 99 "WakeRsn99" 100 "WakeRsn100" 101 "WakeRsn101" 102 "WakeRsn102" 103 "WakeRsn103" 104 "WakeRsn104" 105 "WakeRsn105" 106 "WakeRsn106" 107 "WakeRsn107" 108 "WakeRsn108" 109 "WakeRsn109" 110 "WakeRsn110" 111 "WakeRsn111" 112 "WakeRsn112" 113 "WakeRsn113" 114 "WakeRsn114" 115 "WakeRsn115" 116 "WakeRsn116" 117 "WakeRsn117" 118 "WakeRsn118" 119 "WakeRsn119" 120 "WakeRsn120" 121 "WakeRsn121" 122 "WakeRsn122" 123 "WakeRsn123" 124 "WakeRsn124" 125 "WakeRsn125" 126 "WakeRsn126" 127 "WakeRsn127";
VAL_ 2654208011 WakeReq_TCM 0 "NotActive" 1 "Active";
VAL_ 2654208011 WakeRsn_TCM 0 "Diag" 1 "Network" 2 "WakeRsn2" 3 "WakeRsn3" 4 "WakeRsn4" 5 "WakeRsn5" 6 "WakeRsn6" 7 "WakeRsn7" 8 "WakeRsn8" 9 "WakeRsn9" 10 "WakeRsn10" 11 "WakeRsn11" 12 "WakeRsn12" 13 "WakeRsn13" 14 "WakeRsn14" 15 "WakeRsn15" 16 "WakeRsn16" 17 "WakeRsn17" 18 "WakeRsn18" 19 "WakeRsn19" 20 "WakeRsn20" 21 "WakeRsn21" 22 "WakeRsn22" 23 "WakeRsn23" 24 "WakeRsn24" 25 "WakeRsn25" 26 "WakeRsn26" 27 "WakeRsn27" 28 "WakeRsn28" 29 "WakeRsn29" 30 "WakeRsn30" 31 "WakeRsn31" 32 "WakeRsn32" 33 "WakeRsn33" 34 "WakeRsn34" 35 "WakeRsn35" 36 "WakeRsn36" 37 "WakeRsn37" 38 "WakeRsn38" 39 "WakeRsn39" 40 "WakeRsn40" 41 "WakeRsn41" 42 "WakeRsn42" 43 "WakeRsn43" 44 "WakeRsn44" 45 "WakeRsn45" 46 "WakeRsn46" 47 "WakeRsn47" 48 "WakeRsn48" 49 "WakeRsn49" 50 "WakeRsn50" 51 "WakeRsn51" 52 "WakeRsn52" 53 "WakeRsn53" 54 "WakeRsn54" 55 "WakeRsn55" 56 "WakeRsn56" 57 "WakeRsn57" 58 "WakeRsn58" 59 "WakeRsn59" 60 "WakeRsn60" 61 "WakeRsn61" 62 "WakeRsn62" 63 "WakeRsn63" 64 "WakeRsn64" 65 "WakeRsn65" 66 "WakeRsn66" 67 "WakeRsn67" 68 "WakeRsn68" 69 "WakeRsn69" 70 "WakeRsn70" 71 "WakeRsn71" 72 "WakeRsn72" 73 "WakeRsn73" 74 "WakeRsn74" 75 "WakeRsn75" 76 "WakeRsn76" 77 "WakeRsn77" 78 "WakeRsn78" 79 "WakeRsn79" 80 "WakeRsn80" 81 "WakeRsn81" 82 "WakeRsn82" 83 "WakeRsn83" 84 "WakeRsn84" 85 "WakeRsn85" 86 "WakeRsn86" 87 "WakeRsn87" 88 "WakeRsn88" 89 "WakeRsn89" 90 "WakeRsn90" 91 "WakeRsn91" 92 "WakeRsn92" 93 "WakeRsn93" 94 "WakeRsn94" 95 "WakeRsn95" 96 "WakeRsn96" 97 "WakeRsn97" 98 "WakeRsn98" 99 "WakeRsn99" 100 "WakeRsn100" 101 "WakeRsn101" 102 "WakeRsn102" 103 "WakeRsn103" 104 "WakeRsn104" 105 "WakeRsn105" 106 "WakeRsn106" 107 "WakeRsn107" 108 "WakeRsn108" 109 "WakeRsn109" 110 "WakeRsn110" 111 "WakeRsn111" 112 "WakeRsn112" 113 "WakeRsn113" 114 "WakeRsn114" 115 "WakeRsn115" 116 "WakeRsn116" 117 "WakeRsn117" 118 "WakeRsn118" 119 "WakeRsn119" 120 "WakeRsn120" 121 "WakeRsn121" 122 "WakeRsn122" 123 "WakeRsn123" 124 "WakeRsn124" 125 "WakeRsn125" 126 "WakeRsn126" 127 "WakeRsn127";
VAL_ 278 LHF_FastPulseCounter 255 "SNA";
VAL_ 278 LHF_Spin 0 "Stand_Still" 1 "Forward" 2 "Backward" 3 "SNA";
VAL_ 278 LHF_WheelSensorFailSts 0 "Fail_Not_Present" 1 "Fail_Present";
VAL_ 278 LHR_FastPulseCounter 255 "SNA";
VAL_ 278 LHR_Spin 0 "Stand_Still" 1 "Forward" 2 "Backward" 3 "SNA";
VAL_ 278 LHR_WheelSensorFailSts 0 "Fail_Not_Present" 1 "Fail_Present";
VAL_ 278 RHF_FastPulseCounter 255 "SNA";
VAL_ 278 RHF_Spin 0 "Stand_Still" 1 "Forward" 2 "Backward" 3 "SNA";
VAL_ 278 RHF_WheelSensorFailSts 0 "Fail_Not_Present" 1 "Fail_Present";
VAL_ 278 RHR_FastPulseCounter 255 "SNA";
VAL_ 278 RHR_Spin 0 "Stand_Still" 1 "Forward" 2 "Backward" 3 "SNA";
VAL_ 278 RHR_WheelSensorFailSts 0 "Fail_Not_Present" 1 "Fail_Present";
VAL_ 238 LHFWheelSpeed 8191 "SNA";
VAL_ 238 LHRWheelSpeed 8191 "SNA";
VAL_ 238 RHFWheelSpeed 8191 "SNA";
VAL_ 238 RHRWheelSpeed 8191 "SNA";
